VERSION ""

NS_ :

BS_:

BU_: XXX DSU HCU EPS IPAS XX X

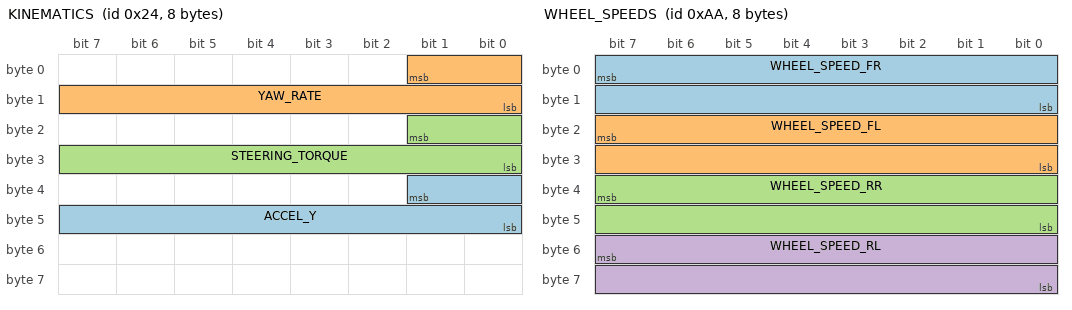
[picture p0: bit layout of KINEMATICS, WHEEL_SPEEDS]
BO_ 36 KINEMATICS: 8 XXX
 SG_ ACCEL_Y : 33|10@0+ (1,-512) [0|65535] "" XXX
 SG_ YAW_RATE : 1|10@0+ (1,-512) [0|65535] "" XXX
 SG_ STEERING_TORQUE : 17|10@0+ (1,-512) [0|65535] "" XXX

BO_ 166 BRAKE: 8 XXX
 SG_ BRAKE_AMOUNT : 7|8@0+ (1,0) [0|255] "" XXX
 SG_ BRAKE_PEDAL : 23|8@0+ (1,0) [0|255] "" XXX

BO_ 170 WHEEL_SPEEDS: 8 XXX
 SG_ WHEEL_SPEED_FR : 7|16@0+ (0.01,-67.67) [0|250] "kph" XXX
 SG_ WHEEL_SPEED_FL : 23|16@0+ (0.01,-67.67) [0|250] "kph" XXX
 SG_ WHEEL_SPEED_RR : 39|16@0+ (0.01,-67.67) [0|250] "kph" XXX
 SG_ WHEEL_SPEED_RL : 55|16@0+ (0.01,-67.67) [0|250] "kph" XXX

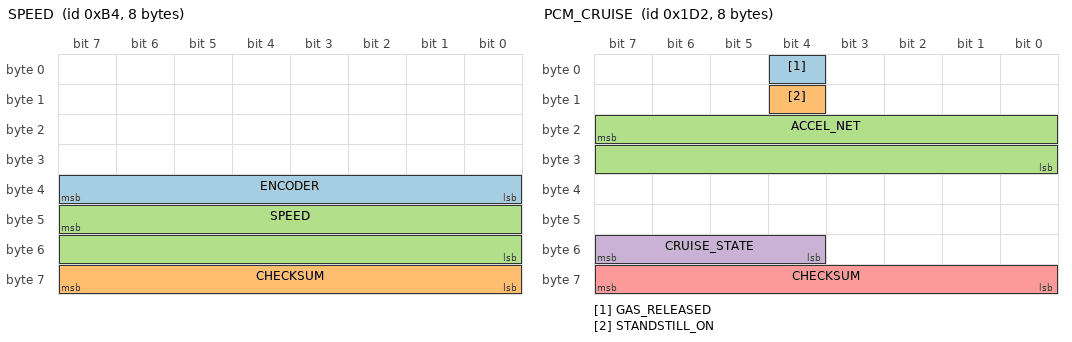
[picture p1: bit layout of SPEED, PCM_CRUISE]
BO_ 180 SPEED: 8 XXX
 SG_ ENCODER : 39|8@0+ (1,0) [0|255] "" XXX
 SG_ CHECKSUM : 63|8@0+ (1,0) [0|255] "" XXX
 SG_ SPEED : 47|16@0+ (0.01,0) [0|250] "kph" XXX

BO_ 466 PCM_CRUISE: 8 XXX
 SG_ GAS_RELEASED : 4|1@0+ (1,0) [0|1] "" XXX
 SG_ STANDSTILL_ON : 12|1@0+ (1,0) [0|1] "" XXX
 SG_ ACCEL_NET : 23|16@0- (0.001,0) [-20|20] "m/s2" XXX
 SG_ CRUISE_STATE : 55|4@0+ (1,0) [0|15] "" XXX
 SG_ CHECKSUM : 63|8@0+ (1,0) [0|255] "" XXX

BO_ 552 ACCELEROMETER: 8 XXX
 SG_ ACCEL_Z : 22|15@0- (1,0) [0|32767] "" XXX
 SG_ ACCEL_X : 6|15@0- (0.001,0) [-20|20] "m/s2" XXX

BO_ 560 BRAKE_MODULE2: 7 XXX
 SG_ BRAKE_PRESSED : 26|1@0+ (1,0) [0|1] "" XXX

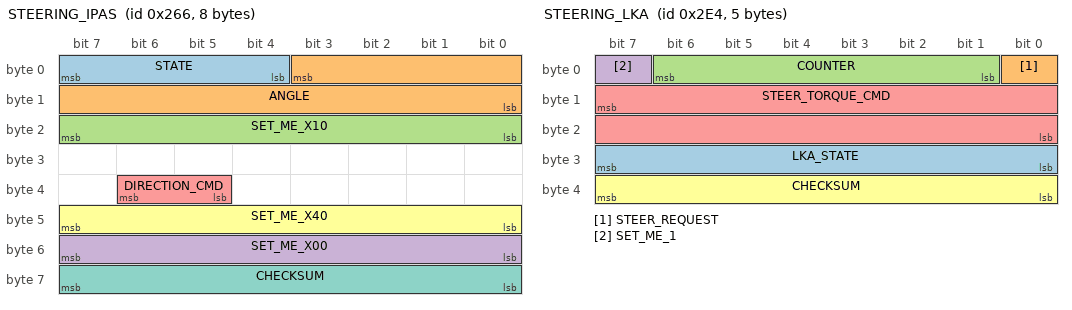
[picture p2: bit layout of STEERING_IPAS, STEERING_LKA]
BO_ 614 STEERING_IPAS: 8 IPAS
 SG_ STATE : 7|4@0+ (1,0) [0|15] "" XXX
 SG_ ANGLE : 3|12@0- (1.5,0) [-510|510] "deg" XXX
 SG_ SET_ME_X10 : 23|8@0+ (1,0) [0|255] "" XXX
 SG_ SET_ME_X00 : 55|8@0+ (1,0) [0|255] "" XXX
 SG_ DIRECTION_CMD : 38|2@0+ (1,0) [0|3] "" XXX
 SG_ SET_ME_X40 : 47|8@0+ (1,0) [0|255] "" XXX
 SG_ CHECKSUM : 63|8@0+ (1,0) [0|255] "" XXX

BO_ 643 PRE_COLLISION: 8 XXX

BO_ 740 STEERING_LKA: 5 XXX
 SG_ LKA_STATE : 31|8@0+ (1,0) [0|255] "" XXX
 SG_ STEER_REQUEST : 0|1@0+ (1,0) [0|1] "" XXX
 SG_ COUNTER : 6|6@0+ (1,0) [0|63] "" XXX
 SG_ SET_ME_1 : 7|1@0+ (1,0) [0|1] "" XXX
 SG_ STEER_TORQUE_CMD : 15|16@0- (1,0) [0|65535] "" XXX
 SG_ CHECKSUM : 39|8@0+ (1,0) [0|255] "" XXX

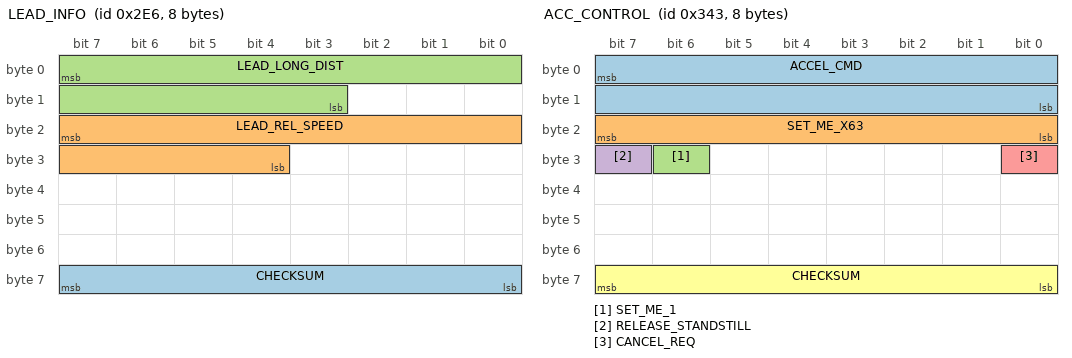
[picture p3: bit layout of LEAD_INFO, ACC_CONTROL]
BO_ 742 LEAD_INFO: 8 DSU
 SG_ CHECKSUM : 63|8@0+ (1,0) [0|255] "" HCU
 SG_ LEAD_REL_SPEED : 23|12@0- (0.025,0) [-100|100] "m/s" HCU
 SG_ LEAD_LONG_DIST : 7|13@0+ (0.05,0) [0|300] "m" HCU

BO_ 835 ACC_CONTROL: 8 DSU
 SG_ ACCEL_CMD : 7|16@0- (0.001,0) [-20|20] "m/s2" HCU
 SG_ SET_ME_X63 : 23|8@0+ (1,0) [0|255] "" HCU
 SG_ SET_ME_1 : 30|1@0+ (1,0) [0|1] "" HCU
 SG_ RELEASE_STANDSTILL : 31|1@0+ (1,0) [0|1] "" HCU
 SG_ CANCEL_REQ : 24|1@0+ (1,0) [0|1] "" HCU
 SG_ CHECKSUM : 63|8@0+ (1,0) [0|255] "" XXX

BO_ 1556 STEERING_LEVERS: 8 XXX
 SG_ TURN_SIGNALS : 29|2@0+ (1,0) [0|3] "" XXX

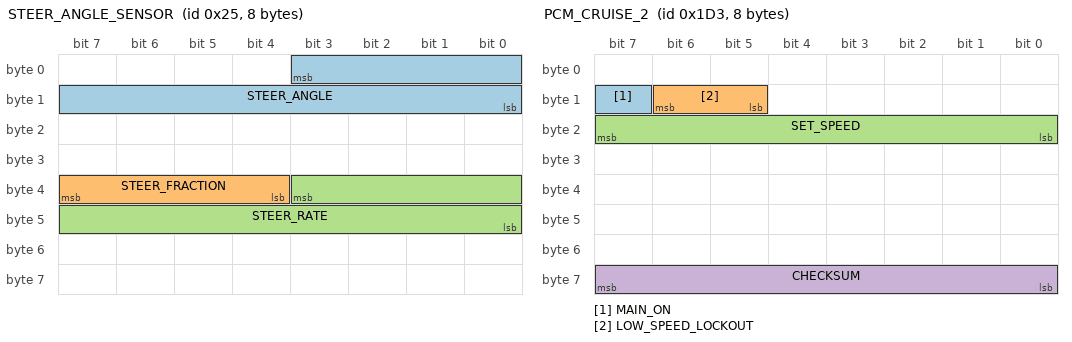
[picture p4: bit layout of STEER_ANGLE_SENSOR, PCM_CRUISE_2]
BO_ 37 STEER_ANGLE_SENSOR: 8 XXX
 SG_ STEER_ANGLE : 3|12@0- (1.5,0) [-500|500] "deg" XXX
 SG_ STEER_FRACTION : 39|4@0- (0.1,0) [-0.7|0.7] "deg" XXX
 SG_ STEER_RATE : 35|12@0- (1,0) [-2000|2000] "deg/s" XXX

BO_ 467 PCM_CRUISE_2: 8 XXX
 SG_ MAIN_ON : 15|1@0+ (1,0) [0|1] "" XXX
 SG_ LOW_SPEED_LOCKOUT : 14|2@0+ (1,0) [0|3] "kph" XXX
 SG_ SET_SPEED : 23|8@0+ (1,0) [0|255] "kph" XXX
 SG_ CHECKSUM : 63|8@0+ (1,0) [0|255] "" XXX

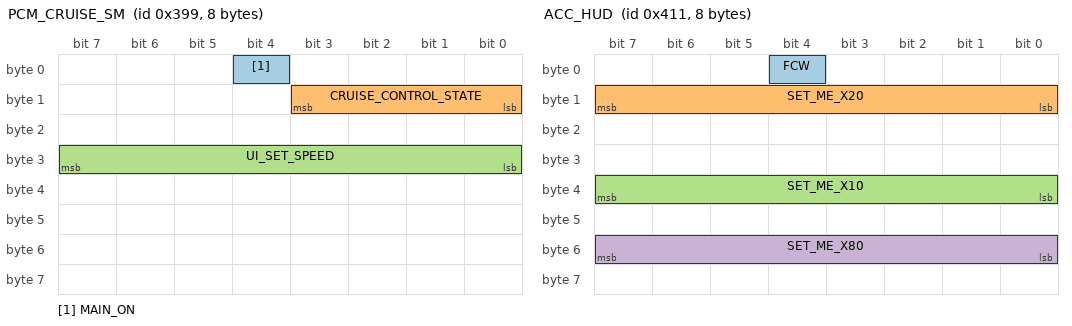
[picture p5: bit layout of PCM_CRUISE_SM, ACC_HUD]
BO_ 921 PCM_CRUISE_SM: 8 XXX
 SG_ MAIN_ON : 4|1@0+ (1,0) [0|1] "" XXX
 SG_ CRUISE_CONTROL_STATE : 11|4@0+ (1,0) [0|15] "" XXX
 SG_ UI_SET_SPEED : 31|8@0+ (1,0) [0|255] "" XXX

BO_ 951 ESP_CONTROL: 8 ESP
 SG_ TC_DISABLED : 13|1@0+ (1,0) [0|1] "" XXX
 SG_ BRAKE_LIGHTS_ACC : 18|1@0+ (1,0) [0|1] "" XXX

BO_ 1041 ACC_HUD: 8 DSU
 SG_ FCW : 4|1@0+ (1,0) [0|1] "" XXX
 SG_ SET_ME_X20 : 15|8@0+ (1,0) [0|1] "" XXX
 SG_ SET_ME_X10 : 39|8@0+ (1,0) [0|1] "" XXX
 SG_ SET_ME_X80 : 55|8@0+ (1,0) [0|1] "" XXX

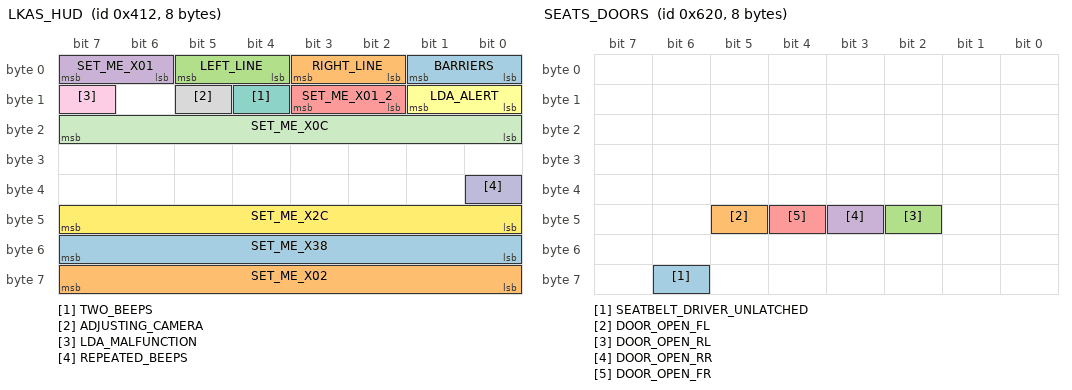
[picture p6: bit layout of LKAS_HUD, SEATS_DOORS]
BO_ 1042 LKAS_HUD: 8 XXX
 SG_ BARRIERS : 1|2@0+ (1,0) [0|3] "" XXX
 SG_ RIGHT_LINE : 3|2@0+ (1,0) [0|3] "" XXX
 SG_ LEFT_LINE : 5|2@0+ (1,0) [0|3] "" XXX
 SG_ SET_ME_X01 : 7|2@0+ (1,0) [0|3] "" XXX
 SG_ SET_ME_X01_2 : 11|2@0+ (1,0) [0|3] "" XXX
 SG_ LDA_ALERT : 9|2@0+ (1,0) [0|3] "" XXX
 SG_ TWO_BEEPS : 12|1@0+ (1,0) [0|1] "" XXX
 SG_ ADJUSTING_CAMERA : 13|1@0+ (1,0) [0|1] "" XXX
 SG_ LDA_MALFUNCTION : 15|1@0+ (1,0) [0|1] "" XXX
 SG_ REPEATED_BEEPS : 32|1@0+ (1,0) [0|1] "" XXX
 SG_ SET_ME_X0C : 23|8@0+ (1,0) [0|1] "" XXX
 SG_ SET_ME_X2C : 47|8@0+ (1,0) [0|1] "" XXX
 SG_ SET_ME_X38 : 55|8@0+ (1,0) [0|1] "" XXX
 SG_ SET_ME_X02 : 63|8@0+ (1,0) [0|1] "" XXX

BO_ 1553 UI_SEETING: 8 XXX
 SG_ UNITS : 26|2@0+ (1,0) [0|3] "" XXX

BO_ 1568 SEATS_DOORS: 8 XXX
 SG_ SEATBELT_DRIVER_UNLATCHED : 62|1@0+ (1,0) [0|1] "" XXX
 SG_ DOOR_OPEN_FL : 45|1@0+ (1,0) [0|1] "" XXX
 SG_ DOOR_OPEN_RL : 42|1@0+ (1,0) [0|1] "" XXX
 SG_ DOOR_OPEN_RR : 43|1@0+ (1,0) [0|1] "" XXX
 SG_ DOOR_OPEN_FR : 44|1@0+ (1,0) [0|1] "" XXX

BO_ 1570 LIGHT_STALK: 8 SCM
 SG_ AUTO_HIGH_BEAM : 37|1@0+ (1,0) [0|1] "" XXX

BO_ 550 BRAKE_MODULE: 8 XXX

BO_ 581 GAS_PEDAL: 5 XXX
 SG_ GAS_PEDAL : 23|8@0+ (0.005,0) [0|1] "" XXX

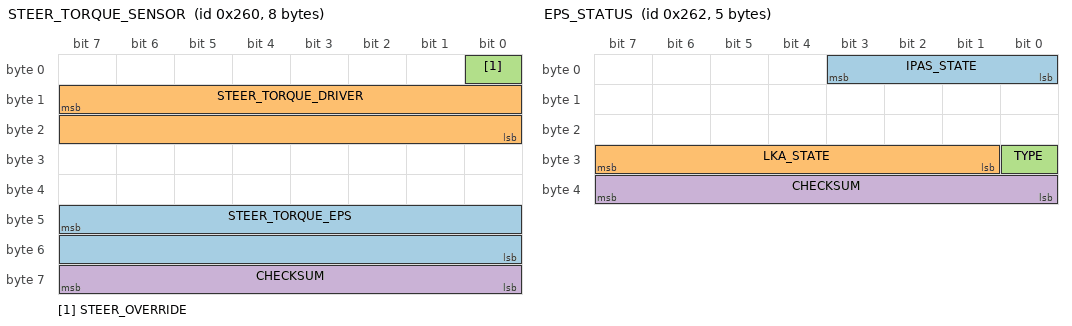
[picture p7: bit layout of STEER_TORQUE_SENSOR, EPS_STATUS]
BO_ 608 STEER_TORQUE_SENSOR: 8 XXX
 SG_ STEER_TORQUE_EPS : 47|16@0- (0.73,0) [-20000|20000] "" XXX
 SG_ STEER_TORQUE_DRIVER : 15|16@0- (1,0) [-32768|32767] "" XXX
 SG_ STEER_OVERRIDE : 0|1@0+ (1,0) [0|1] "" XXX
 SG_ CHECKSUM : 63|8@0+ (1,0) [0|255] "" XXX

BO_ 610 EPS_STATUS: 5 EPS
 SG_ IPAS_STATE : 3|4@0+ (1,0) [0|15] "" XXX
 SG_ LKA_STATE : 31|7@0+ (1,0) [0|127] "" XXX
 SG_ TYPE : 24|1@0+ (1,0) [0|1] "" XXX
 SG_ CHECKSUM : 39|8@0+ (1,0) [0|255] "" XXX

BO_ 956 GEAR_PACKET: 8 XXX
 SG_ GEAR : 13|6@0+ (1,0) [0|63] "" XXX

BO_ 1880 DEBUG: 8 XXX
 SG_ 61 : 16|8@1+ (1,0) [0|255] "" XXX
 SG_ 69 : 24|8@1+ (1,0) [0|255] "" XXX
 SG_ BLINDSPOTSIDE : 7|8@0+ (1,0) [0|255] "" XXX
 SG_ Blindspot : 38|1@0+ (1,0) [0|3] "" XXX
 SG_ NEW_SIGNAL_2 : 63|1@1+ (1,0) [0|15] "" XXX
 SG_ NEW_SIGNAL_1 : 59|1@1+ (1,0) [0|15] "" XXX
 SG_ NEW_SIGNAL_3 : 58|1@1+ (1,0) [0|7] "" XXX
 SG_ NEW_SIGNAL_4 : 57|1@1+ (1,0) [0|3] "" XXX
 SG_ NEW_SIGNAL_5 : 56|1@0+ (1,0) [0|3] "" XXX
 SG_ 06 : 8|8@1+ (1,0) [0|255] "" XXX
 SG_ NEW_SIGNAL_7 : 37|1@0+ (1,0) [0|1] "" XXX
 SG_ NEW_SIGNAL_6 : 36|1@1+ (1,0) [0|63] "" XXX
 SG_ NEW_SIGNAL_8 : 39|1@0+ (1,0) [0|1] "" XXX
 SG_ NEW_SIGNAL_10 : 47|8@0+ (1,0) [0|255] "" XXX
 SG_ NEW_SIGNAL_9 : 32|4@1+ (1,0) [0|15] "" XXX
 SG_ NEW_SIGNAL_12 : 62|3@0+ (1,0) [0|7] "" XXX
 SG_ NEW_SIGNAL_11 : 55|8@0+ (1,0) [0|255] "" XXX

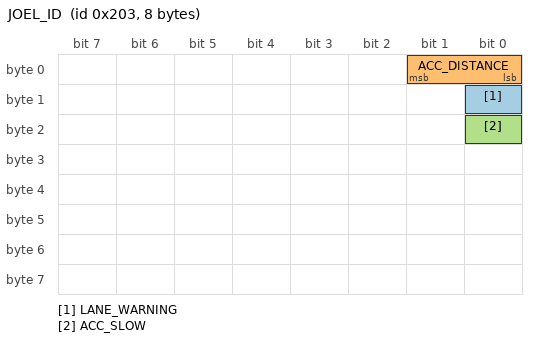
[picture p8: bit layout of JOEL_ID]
BO_ 515 JOEL_ID: 8 XXX
 SG_ LANE_WARNING : 8|1@0+ (1,0) [0|1] "" XXX
 SG_ ACC_DISTANCE : 1|2@0+ (1,0) [1|3] "" XXX
 SG_ ACC_SLOW : 16|1@0+ (1,0) [0|1] "" XXX

CM_ SG_ 36 ACCEL_Y "unit is tbd";
CM_ SG_ 36 YAW_RATE "verify";
CM_ SG_ 36 STEERING_TORQUE "does not seem the steer torque, tbd";
CM_ SG_ 466 ACCEL_NET "net acceleration produced by the system, given ACCEL_CMD, road grade and other factors";
CM_ SG_ 560 BRAKE_PRESSED "another brake pressed?";
CM_ SG_ 614 ANGLE "set to measured angle when ipas control isn't active";
CM_ SG_ 37 STEER_FRACTION "1/15th of the signal STEER_ANGLE, which is 1.5 deg; note that 0x8 is never set";
CM_ SG_ 37 STEER_RATE "factor is tbd";
CM_ SG_ 467 LOW_SPEED_LOCKOUT "in low speed lockout, system would always disengage below 28mph";
CM_ SG_ 467 SET_SPEED "43 kph are shown as 28mph, so conversion isnt perfect";
CM_ SG_ 921 UI_SET_SPEED "set speed shown in UI with user set unit";
CM_ SG_ 951 BRAKE_LIGHTS_ACC "brake lights when ACC commands decel";
CM_ SG_ 1042 REPEATED_BEEPS "recommended for fcw and other important alerts";
CM_ SG_ 581 GAS_PEDAL "it seems slightly filtered";
CM_ SG_ 610 TYPE "seems 1 on Corolla, 0 on all others";
CM_ SG_ 1880 BLINDSPOTSIDE "65 for Left and 66 for Right";
VAL_ 466 CRUISE_STATE 8 "active" 7 "standstill" 1 "off" ;
VAL_ 614 STATE 3 "enabled" 1 "disabled" ;
VAL_ 614 DIRECTION_CMD 3 "right" 2 "center" 1 "left" ;
VAL_ 1556 TURN_SIGNALS 3 "none" 2 "right" 1 "left" ;
VAL_ 467 LOW_SPEED_LOCKOUT 2 "low speed locked" 1 "ok" ;
VAL_ 921 CRUISE_CONTROL_STATE 2 "disabled" 11 "hold" 10 "hold_waiting_user_cmd" 6 "enabled" 5 "faulted" ;
VAL_ 1042 BARRIERS 3 "both" 2 "right" 1 "left" 0 "none" ;
VAL_ 1042 RIGHT_LINE 3 "orange" 2 "double" 1 "solid" 0 "none" ;
VAL_ 1042 LEFT_LINE 3 "orange" 2 "double" 1 "solid" 0 "none" ;
VAL_ 1042 LDA_ALERT 3 "hold with continuous beep" 2 "LDA unavailable" 1 "hold" 0 "none" ;
VAL_ 1553 UNITS 1 "km" 2 "miles" ;
VAL_ 610 IPAS_STATE 5 "override" 3 "enabled" 1 "disabled" ;
VAL_ 610 LKA_STATE 25 "temporary_fault" 9 "temporary_fault2" 5 "active" 1 "standby" ;
VAL_ 956 GEAR 0 "D" 1 "S" 8 "N" 16 "R" 32 "P" ;
CM_ "toyota_rav4_hybrid_2017_pt.dbc start
CM_ "toyota_rav4_hybrid_2017_pt.dbc st";
CM_ "toyota_rav4_hybrid_2017_pt.dbc sta
CM_ "toyota_rav4_hybrid_2017_pt.dbc sta";
CM_ "toyota_rav4_hybrid_2017_pt.dbc star
CM_ "toyota_rav4_hybrid_2017_pt.dbc sta";
CM_ "toyota_rav4_hybrid_2017_pt.dbc star
CM_ "toyota_rav4_hybrid_2017_pt.dbc star";
CM_ "toyota_rav4_hybrid_2017_pt.dbc start
CM_ "toyota_rav4_hybrid_2017_pt.dbc sta";
CM_ "toyota_rav4_hybrid_2017_pt.dbc star
CM_ "toyota_rav4_hybrid_2017_pt.dbc star";
CM_ "toyota_rav4_hybrid_2017_pt.dbc start
CM_ "toyota_rav4_hybrid_2017_pt.dbc star";
CM_ "toyota_rav4_hybrid_2017_pt.dbc start
CM_ "toyota_rav4_hybrid_2017_pt.dbc start";
CM_ "toyota_rav4_hybrid_2017_pt.dbc starts
CM_ "toyota_rav4_hybrid_2017_pt.dbc s";
CM_ "toyota_rav4_hybrid_2017_pt.dbc st
CM_ "toyota_rav4_hybrid_2017_pt.dbc st";
CM_ "toyota_rav4_hybrid_2017_pt.dbc sta
CM_ "toyota_rav4_hybrid_2017_pt.dbc st";
CM_ "toyota_rav4_hybrid_2017_pt.dbc sta
CM_ "toyota_rav4_hybrid_2017_pt.dbc sta";
CM_ "toyota_rav4_hybrid_2017_pt.dbc star
CM_ "toyota_rav4_hybrid_2017_pt.dbc st";
CM_ "toyota_rav4_hybrid_2017_pt.dbc sta
CM_ "toyota_rav4_hybrid_2017_pt.dbc sta";
CM_ "toyota_rav4_hybrid_2017_pt.dbc star
CM_ "toyota_rav4_hybrid_2017_pt.dbc sta";
CM_ "toyota_rav4_hybrid_2017_pt.dbc star
CM_ "toyota_rav4_hybrid_2017_pt.dbc star";
CM_ "toyota_rav4_hybrid_2017_pt.dbc start
CM_ "toyota_rav4_hybrid_2017_pt.dbc st";
CM_ "toyota_rav4_hybrid_2017_pt.dbc sta
CM_ "toyota_rav4_hybrid_2017_pt.dbc sta";
CM_ "toyota_rav4_hybrid_2017_pt.dbc star
CM_ "toyota_rav4_hybrid_2017_pt.dbc sta";
CM_ "toyota_rav4_hybrid_2017_pt.dbc star
CM_ "toyota_rav4_hybrid_2017_pt.dbc star";
CM_ "toyota_rav4_hybrid_2017_pt.dbc start
CM_ "toyota_rav4_hybrid_2017_pt.dbc sta";
CM_ "toyota_rav4_hybrid_2017_pt.dbc star
CM_ "toyota_rav4_hybrid_2017_pt.dbc star";
CM_ "toyota_rav4_hybrid_2017_pt.dbc start
CM_ "toyota_rav4_hybrid_2017_pt.dbc star";
CM_ "toyota_rav4_hybrid_2017_pt.dbc start
CM_ "toyota_rav4_hybrid_2017_pt.dbc start";
CM_ "toyota_rav4_hybrid_2017_pt.dbc starts
CM_ "toyota_rav4_hybrid_2017_pt.dbc s";
CM_ "toyota_rav4_hybrid_2017_pt.dbc st
CM_ "toyota_rav4_hybrid_2017_pt.dbc st";
CM_ "toyota_rav4_hybrid_2017_pt.dbc sta
CM_ "toyota_rav4_hybrid_2017_pt.dbc st";
CM_ "toyota_rav4_hybrid_2017_pt.dbc sta
CM_ "toyota_rav4_hybrid_2017_pt.dbc sta";
CM_ "toyota_rav4_hybrid_2017_pt.dbc star
CM_ "toyota_rav4_hybrid_2017_pt.dbc st";
CM_ "toyota_rav4_hybrid_2017_pt.dbc sta
CM_ "toyota_rav4_hybrid_2017_pt.dbc sta";
CM_ "toyota_rav4_hybrid_2017_pt.dbc star
CM_ "toyota_rav4_hybrid_2017_pt.dbc sta";
CM_ "toyota_rav4_hybrid_2017_pt.dbc star
CM_ "toyota_rav4_hybrid_2017_pt.dbc star";
CM_ "toyota_rav4_hybrid_2017_pt.dbc start
CM_ "toyota_rav4_hybrid_2017_pt.dbc st";
CM_ "toyota_rav4_hybrid_2017_pt.dbc sta
CM_ "toyota_rav4_hybrid_2017_pt.dbc sta";
CM_ "toyota_rav4_hybrid_2017_pt.dbc star
CM_ "toyota_rav4_hybrid_2017_pt.dbc sta";
CM_ "toyota_rav4_hybrid_2017_pt.dbc star
CM_ "toyota_rav4_hybrid_2017_pt.dbc star";
CM_ "toyota_rav4_hybrid_2017_pt.dbc start
CM_ "toyota_rav4_hybrid_2017_pt.dbc sta";
CM_ "toyota_rav4_hybrid_2017_pt.dbc star
CM_ "toyota_rav4_hybrid_2017_pt.dbc star";
CM_ "toyota_rav4_hybrid_2017_pt.dbc start
CM_ "toyota_rav4_hybrid_2017_pt.dbc star";
CM_ "toyota_rav4_hybrid_2017_pt.dbc start
CM_ "toyota_rav4_hybrid_2017_pt.dbc start";
CM_ "toyota_rav4_hybrid_2017_pt.dbc starts
CM_ "toyota_rav4_hybrid_2017_pt.dbc st";
CM_ "toyota_rav4_hybrid_2017_pt.dbc sta
CM_ "toyota_rav4_hybrid_2017_pt.dbc sta";
CM_ "toyota_rav4_hybrid_2017_pt.dbc star
CM_ "toyota_rav4_hybrid_2017_pt.dbc sta";
CM_ "toyota_rav4_hybrid_2017_pt.dbc star
CM_ "toyota_rav4_hybrid_2017_pt.dbc star";
CM_ "toyota_rav4_hybrid_2017_pt.dbc start
CM_ "toyota_rav4_hybrid_2017_pt.dbc sta";
CM_ "toyota_rav4_hybrid_2017_pt.dbc star
CM_ "toyota_rav4_hybrid_2017_pt.dbc star";
CM_ "toyota_rav4_hybrid_2017_pt.dbc start
CM_ "toyota_rav4_hybrid_2017_pt.dbc star";
CM_ "toyota_rav4_hybrid_2017_pt.dbc start
CM_ "toyota_rav4_hybrid_2017_pt.dbc start";
CM_ "toyota_rav4_hybrid_2017_pt.dbc starts
CM_ "toyota_rav4_hybrid_2017_pt.dbc st";
CM_ "toyota_rav4_hybrid_2017_pt.dbc sta
CM_ "toyota_rav4_hybrid_2017_pt.dbc sta";
CM_ "toyota_rav4_hybrid_2017_pt.dbc star
CM_ "toyota_rav4_hybrid_2017_pt.dbc sta";
CM_ "toyota_rav4_hybrid_2017_pt.dbc star
CM_ "toyota_rav4_hybrid_2017_pt.dbc star";
CM_ "toyota_rav4_hybrid_2017_pt.dbc start
CM_ "toyota_rav4_hybrid_2017_pt.dbc sta";
CM_ "toyota_rav4_hybrid_2017_pt.dbc star
CM_ "toyota_rav4_hybrid_2017_pt.dbc star";
CM_ "toyota_rav4_hybrid_2017_pt.dbc start
CM_ "toyota_rav4_hybrid_2017_pt.dbc star";
CM_ "toyota_rav4_hybrid_2017_pt.dbc start
CM_ "toyota_rav4_hybrid_2017_pt.dbc start";
CM_ "toyota_rav4_hybrid_2017_pt.dbc starts
CM_ "toyota_rav4_hybrid_2017_pt.dbc sta";
CM_ "toyota_rav4_hybrid_2017_pt.dbc star
CM_ "toyota_rav4_hybrid_2017_pt.dbc star";
CM_ "toyota_rav4_hybrid_2017_pt.dbc start
CM_ "toyota_rav4_hybrid_2017_pt.dbc star";
CM_ "toyota_rav4_hybrid_2017_pt.dbc start
CM_ "toyota_rav4_hybrid_2017_pt.dbc start";
CM_ "toyota_rav4_hybrid_2017_pt.dbc starts
CM_ "toyota_rav4_hybrid_2017_pt.dbc sta";
CM_ "toyota_rav4_hybrid_2017_pt.dbc star
CM_ "toyota_rav4_hybrid_2017_pt.dbc star";
CM_ "toyota_rav4_hybrid_2017_pt.dbc start
CM_ "toyota_rav4_hybrid_2017_pt.dbc star";
CM_ "toyota_rav4_hybrid_2017_pt.dbc start
CM_ "toyota_rav4_hybrid_2017_pt.dbc start";
CM_ "toyota_rav4_hybrid_2017_pt.dbc starts
CM_ "toyota_rav4_hybrid_2017_pt.dbc star";
CM_ "toyota_rav4_hybrid_2017_pt.dbc start
CM_ "toyota_rav4_hybrid_2017_pt.dbc start";
CM_ "toyota_rav4_hybrid_2017_pt.dbc starts
CM_ "toyota_rav4_hybrid_2017_pt.dbc star";
CM_ "toyota_rav4_hybrid_2017_pt.dbc start
CM_ "toyota_rav4_hybrid_2017_pt.dbc start";
CM_ "toyota_rav4_hybrid_2017_pt.dbc starts
CM_ "toyota_rav4_hybrid_2017_pt.dbc start";
CM_ "toyota_rav4_hybrid_2017_pt.dbc starts
CM_ "toyota_rav4_hybrid_2017_pt.dbc start";
CM_ "toyota_rav4_hybrid_2017_pt.dbc starts
CM_ "toyota_rav4_hybrid_2017_pt.dbc starts";
CM_ "toyota_rav4_hybrid_2017_pt.dbc starts
CM_ "toyota_rav4_hybrid_2017_pt.dbc starts ";
CM_ "toyota_rav4_hybrid_2017_pt.dbc starts h
CM_ "toyota_rav4_hybrid_2017_pt.dbc s";
CM_ "toyota_rav4_hybrid_2017_pt.dbc st
CM_ "toyota_rav4_hybrid_2017_pt.dbc st";
CM_ "toyota_rav4_hybrid_2017_pt.dbc sta
CM_ "toyota_rav4_hybrid_2017_pt.dbc st";
CM_ "toyota_rav4_hybrid_2017_pt.dbc sta
CM_ "toyota_rav4_hybrid_2017_pt.dbc sta";
CM_ "toyota_rav4_hybrid_2017_pt.dbc star
CM_ "toyota_rav4_hybrid_2017_pt.dbc st";
CM_ "toyota_rav4_hybrid_2017_pt.dbc sta
CM_ "toyota_rav4_hybrid_2017_pt.dbc sta";
CM_ "toyota_rav4_hybrid_2017_pt.dbc star
CM_ "toyota_rav4_hybrid_2017_pt.dbc sta";
CM_ "toyota_rav4_hybrid_2017_pt.dbc star
CM_ "toyota_rav4_hybrid_2017_pt.dbc star";
CM_ "toyota_rav4_hybrid_2017_pt.dbc start
CM_ "toyota_rav4_hybrid_2017_pt.dbc st";
CM_ "toyota_rav4_hybrid_2017_pt.dbc sta
CM_ "toyota_rav4_hybrid_2017_pt.dbc sta";
CM_ "toyota_rav4_hybrid_2017_pt.dbc star
CM_ "toyota_rav4_hybrid_2017_pt.dbc sta";
CM_ "toyota_rav4_hybrid_2017_pt.dbc star
CM_ "toyota_rav4_hybrid_2017_pt.dbc star";
CM_ "toyota_rav4_hybrid_2017_pt.dbc start
CM_ "toyota_rav4_hybrid_2017_pt.dbc sta";
CM_ "toyota_rav4_hybrid_2017_pt.dbc star
CM_ "toyota_rav4_hybrid_2017_pt.dbc star";
CM_ "toyota_rav4_hybrid_2017_pt.dbc start
CM_ "toyota_rav4_hybrid_2017_pt.dbc star";
CM_ "toyota_rav4_hybrid_2017_pt.dbc start
CM_ "toyota_rav4_hybrid_2017_pt.dbc start";
CM_ "toyota_rav4_hybrid_2017_pt.dbc starts
CM_ "toyota_rav4_hybrid_2017_pt.dbc s";
CM_ "toyota_rav4_hybrid_2017_pt.dbc st
CM_ "toyota_rav4_hybrid_2017_pt.dbc st";
CM_ "toyota_rav4_hybrid_2017_pt.dbc sta
CM_ "toyota_rav4_hybrid_2017_pt.dbc st";
CM_ "toyota_rav4_hybrid_2017_pt.dbc sta
CM_ "toyota_rav4_hybrid_2017_pt.dbc sta";
CM_ "toyota_rav4_hybrid_2017_pt.dbc star
CM_ "toyota_rav4_hybrid_2017_pt.dbc st";
CM_ "toyota_rav4_hybrid_2017_pt.dbc sta
CM_ "toyota_rav4_hybrid_2017_pt.dbc sta";
CM_ "toyota_rav4_hybrid_2017_pt.dbc star
CM_ "toyota_rav4_hybrid_2017_pt.dbc sta";
CM_ "toyota_rav4_hybrid_2017_pt.dbc star
CM_ "toyota_rav4_hybrid_2017_pt.dbc star";
CM_ "toyota_rav4_hybrid_2017_pt.dbc start
CM_ "toyota_rav4_hybrid_2017_pt.dbc st";
CM_ "toyota_rav4_hybrid_2017_pt.dbc sta
CM_ "toyota_rav4_hybrid_2017_pt.dbc sta";
CM_ "toyota_rav4_hybrid_2017_pt.dbc star
CM_ "toyota_rav4_hybrid_2017_pt.dbc sta";
CM_ "toyota_rav4_hybrid_2017_pt.dbc star
CM_ "toyota_rav4_hybrid_2017_pt.dbc star";
CM_ "toyota_rav4_hybrid_2017_pt.dbc start
CM_ "toyota_rav4_hybrid_2017_pt.dbc sta";
CM_ "toyota_rav4_hybrid_2017_pt.dbc star
CM_ "toyota_rav4_hybrid_2017_pt.dbc star";
CM_ "toyota_rav4_hybrid_2017_pt.dbc start
CM_ "toyota_rav4_hybrid_2017_pt.dbc star";
CM_ "toyota_rav4_hybrid_2017_pt.dbc start
CM_ "toyota_rav4_hybrid_2017_pt.dbc start";
CM_ "toyota_rav4_hybrid_2017_pt.dbc starts
CM_ "toyota_rav4_hybrid_2017_pt.dbc st";
CM_ "toyota_rav4_hybrid_2017_pt.dbc sta
CM_ "toyota_rav4_hybrid_2017_pt.dbc sta";
CM_ "toyota_rav4_hybrid_2017_pt.dbc star
CM_ "toyota_rav4_hybrid_2017_pt.dbc sta";
CM_ "toyota_rav4_hybrid_2017_pt.dbc star
CM_ "toyota_rav4_hybrid_2017_pt.dbc star";
CM_ "toyota_rav4_hybrid_2017_pt.dbc start
CM_ "toyota_rav4_hybrid_2017_pt.dbc sta";
CM_ "toyota_rav4_hybrid_2017_pt.dbc star
CM_ "toyota_rav4_hybrid_2017_pt.dbc star";
CM_ "toyota_rav4_hybrid_2017_pt.dbc start
CM_ "toyota_rav4_hybrid_2017_pt.dbc star";
CM_ "toyota_rav4_hybrid_2017_pt.dbc start
CM_ "toyota_rav4_hybrid_2017_pt.dbc start";
CM_ "toyota_rav4_hybrid_2017_pt.dbc starts
CM_ "toyota_rav4_hybrid_2017_pt.dbc st";
CM_ "toyota_rav4_hybrid_2017_pt.dbc sta
CM_ "toyota_rav4_hybrid_2017_pt.dbc sta";
CM_ "toyota_rav4_hybrid_2017_pt.dbc star
CM_ "toyota_rav4_hybrid_2017_pt.dbc sta";
CM_ "toyota_rav4_hybrid_2017_pt.dbc star
CM_ "toyota_rav4_hybrid_2017_pt.dbc star";
CM_ "toyota_rav4_hybrid_2017_pt.dbc start
CM_ "toyota_rav4_hybrid_2017_pt.dbc sta";
CM_ "toyota_rav4_hybrid_2017_pt.dbc star
CM_ "toyota_rav4_hybrid_2017_pt.dbc star";
CM_ "toyota_rav4_hybrid_2017_pt.dbc start
CM_ "toyota_rav4_hybrid_2017_pt.dbc star";
CM_ "toyota_rav4_hybrid_2017_pt.dbc start
CM_ "toyota_rav4_hybrid_2017_pt.dbc start";
CM_ "toyota_rav4_hybrid_2017_pt.dbc starts
CM_ "toyota_rav4_hybrid_2017_pt.dbc sta";
CM_ "toyota_rav4_hybrid_2017_pt.dbc star
CM_ "toyota_rav4_hybrid_2017_pt.dbc star";
CM_ "toyota_rav4_hybrid_2017_pt.dbc start
CM_ "toyota_rav4_hybrid_2017_pt.dbc star";
CM_ "toyota_rav4_hybrid_2017_pt.dbc start
CM_ "toyota_rav4_hybrid_2017_pt.dbc start";
CM_ "toyota_rav4_hybrid_2017_pt.dbc starts
CM_ "toyota_rav4_hybrid_2017_pt.dbc sta";
CM_ "toyota_rav4_hybrid_2017_pt.dbc star
CM_ "toyota_rav4_hybrid_2017_pt.dbc star";
CM_ "toyota_rav4_hybrid_2017_pt.dbc start
CM_ "toyota_rav4_hybrid_2017_pt.dbc star";
CM_ "toyota_rav4_hybrid_2017_pt.dbc start
CM_ "toyota_rav4_hybrid_2017_pt.dbc start";
CM_ "toyota_rav4_hybrid_2017_pt.dbc starts
CM_ "toyota_rav4_hybrid_2017_pt.dbc star";
CM_ "toyota_rav4_hybrid_2017_pt.dbc start
CM_ "toyota_rav4_hybrid_2017_pt.dbc start";
CM_ "toyota_rav4_hybrid_2017_pt.dbc starts
CM_ "toyota_rav4_hybrid_2017_pt.dbc star";
CM_ "toyota_rav4_hybrid_2017_pt.dbc start
CM_ "toyota_rav4_hybrid_2017_pt.dbc start";
CM_ "toyota_rav4_hybrid_2017_pt.dbc starts
CM_ "toyota_rav4_hybrid_2017_pt.dbc start";
CM_ "toyota_rav4_hybrid_2017_pt.dbc starts
CM_ "toyota_rav4_hybrid_2017_pt.dbc start";
CM_ "toyota_rav4_hybrid_2017_pt.dbc starts
CM_ "toyota_rav4_hybrid_2017_pt.dbc starts";
CM_ "toyota_rav4_hybrid_2017_pt.dbc starts
CM_ "toyota_rav4_hybrid_2017_pt.dbc starts ";
CM_ "toyota_rav4_hybrid_2017_pt.dbc starts h
CM_ "toyota_rav4_hybrid_2017_pt.dbc st";
CM_ "toyota_rav4_hybrid_2017_pt.dbc sta
CM_ "toyota_rav4_hybrid_2017_pt.dbc sta";
CM_ "toyota_rav4_hybrid_2017_pt.dbc star
CM_ "toyota_rav4_hybrid_2017_pt.dbc sta";
CM_ "toyota_rav4_hybrid_2017_pt.dbc star
CM_ "toyota_rav4_hybrid_2017_pt.dbc star";
CM_ "toyota_rav4_hybrid_2017_pt.dbc start
CM_ "toyota_rav4_hybrid_2017_pt.dbc sta";
CM_ "toyota_rav4_hybrid_2017_pt.dbc star
CM_ "toyota_rav4_hybrid_2017_pt.dbc star";
CM_ "toyota_rav4_hybrid_2017_pt.dbc start
CM_ "toyota_rav4_hybrid_2017_pt.dbc star";
CM_ "toyota_rav4_hybrid_2017_pt.dbc start
CM_ "toyota_rav4_hybrid_2017_pt.dbc start";
CM_ "toyota_rav4_hybrid_2017_pt.dbc starts
CM_ "toyota_rav4_hybrid_2017_pt.dbc st";
CM_ "toyota_rav4_hybrid_2017_pt.dbc sta
CM_ "toyota_rav4_hybrid_2017_pt.dbc sta";
CM_ "toyota_rav4_hybrid_2017_pt.dbc star
CM_ "toyota_rav4_hybrid_2017_pt.dbc sta";
CM_ "toyota_rav4_hybrid_2017_pt.dbc star
CM_ "toyota_rav4_hybrid_2017_pt.dbc star";
CM_ "toyota_rav4_hybrid_2017_pt.dbc start
CM_ "toyota_rav4_hybrid_2017_pt.dbc sta";
CM_ "toyota_rav4_hybrid_2017_pt.dbc star
CM_ "toyota_rav4_hybrid_2017_pt.dbc star";
CM_ "toyota_rav4_hybrid_2017_pt.dbc start
CM_ "toyota_rav4_hybrid_2017_pt.dbc star";
CM_ "toyota_rav4_hybrid_2017_pt.dbc start
CM_ "toyota_rav4_hybrid_2017_pt.dbc start";
CM_ "toyota_rav4_hybrid_2017_pt.dbc starts
CM_ "toyota_rav4_hybrid_2017_pt.dbc sta";
CM_ "toyota_rav4_hybrid_2017_pt.dbc star
CM_ "toyota_rav4_hybrid_2017_pt.dbc star";
CM_ "toyota_rav4_hybrid_2017_pt.dbc start
CM_ "toyota_rav4_hybrid_2017_pt.dbc star";
CM_ "toyota_rav4_hybrid_2017_pt.dbc start
CM_ "toyota_rav4_hybrid_2017_pt.dbc start";
CM_ "toyota_rav4_hybrid_2017_pt.dbc starts
CM_ "toyota_rav4_hybrid_2017_pt.dbc sta";
CM_ "toyota_rav4_hybrid_2017_pt.dbc star
CM_ "toyota_rav4_hybrid_2017_pt.dbc star";
CM_ "toyota_rav4_hybrid_2017_pt.dbc start
CM_ "toyota_rav4_hybrid_2017_pt.dbc star";
CM_ "toyota_rav4_hybrid_2017_pt.dbc start
CM_ "toyota_rav4_hybrid_2017_pt.dbc start";
CM_ "toyota_rav4_hybrid_2017_pt.dbc starts
CM_ "toyota_rav4_hybrid_2017_pt.dbc star";
CM_ "toyota_rav4_hybrid_2017_pt.dbc start
CM_ "toyota_rav4_hybrid_2017_pt.dbc start";
CM_ "toyota_rav4_hybrid_2017_pt.dbc starts
CM_ "toyota_rav4_hybrid_2017_pt.dbc star";
CM_ "toyota_rav4_hybrid_2017_pt.dbc start
CM_ "toyota_rav4_hybrid_2017_pt.dbc start";
CM_ "toyota_rav4_hybrid_2017_pt.dbc starts
CM_ "toyota_rav4_hybrid_2017_pt.dbc start";
CM_ "toyota_rav4_hybrid_2017_pt.dbc starts
CM_ "toyota_rav4_hybrid_2017_pt.dbc start";
CM_ "toyota_rav4_hybrid_2017_pt.dbc starts
CM_ "toyota_rav4_hybrid_2017_pt.dbc starts";
CM_ "toyota_rav4_hybrid_2017_pt.dbc starts
CM_ "toyota_rav4_hybrid_2017_pt.dbc starts ";
CM_ "toyota_rav4_hybrid_2017_pt.dbc starts h
CM_ "toyota_rav4_hybrid_2017_pt.dbc sta";
CM_ "toyota_rav4_hybrid_2017_pt.dbc star
CM_ "toyota_rav4_hybrid_2017_pt.dbc star";
CM_ "toyota_rav4_hybrid_2017_pt.dbc start
CM_ "toyota_rav4_hybrid_2017_pt.dbc star";
CM_ "toyota_rav4_hybrid_2017_pt.dbc start
CM_ "toyota_rav4_hybrid_2017_pt.dbc start";
CM_ "toyota_rav4_hybrid_2017_pt.dbc starts
CM_ "toyota_rav4_hybrid_2017_pt.dbc sta";
CM_ "toyota_rav4_hybrid_2017_pt.dbc star
CM_ "toyota_rav4_hybrid_2017_pt.dbc star";
CM_ "toyota_rav4_hybrid_2017_pt.dbc start
CM_ "toyota_rav4_hybrid_2017_pt.dbc star";
CM_ "toyota_rav4_hybrid_2017_pt.dbc start
CM_ "toyota_rav4_hybrid_2017_pt.dbc start";
CM_ "toyota_rav4_hybrid_2017_pt.dbc starts
CM_ "toyota_rav4_hybrid_2017_pt.dbc star";
CM_ "toyota_rav4_hybrid_2017_pt.dbc start
CM_ "toyota_rav4_hybrid_2017_pt.dbc start";
CM_ "toyota_rav4_hybrid_2017_pt.dbc starts
CM_ "toyota_rav4_hybrid_2017_pt.dbc star";
CM_ "toyota_rav4_hybrid_2017_pt.dbc start
CM_ "toyota_rav4_hybrid_2017_pt.dbc start";
CM_ "toyota_rav4_hybrid_2017_pt.dbc starts
CM_ "toyota_rav4_hybrid_2017_pt.dbc start";
CM_ "toyota_rav4_hybrid_2017_pt.dbc starts
CM_ "toyota_rav4_hybrid_2017_pt.dbc start";
CM_ "toyota_rav4_hybrid_2017_pt.dbc starts
CM_ "toyota_rav4_hybrid_2017_pt.dbc starts";
CM_ "toyota_rav4_hybrid_2017_pt.dbc starts
CM_ "toyota_rav4_hybrid_2017_pt.dbc starts ";
CM_ "toyota_rav4_hybrid_2017_pt.dbc starts h
CM_ "toyota_rav4_hybrid_2017_pt.dbc star";
CM_ "toyota_rav4_hybrid_2017_pt.dbc start
CM_ "toyota_rav4_hybrid_2017_pt.dbc start";
CM_ "toyota_rav4_hybrid_2017_pt.dbc starts
CM_ "toyota_rav4_hybrid_2017_pt.dbc star";
CM_ "toyota_rav4_hybrid_2017_pt.dbc start
CM_ "toyota_rav4_hybrid_2017_pt.dbc start";
CM_ "toyota_rav4_hybrid_2017_pt.dbc starts
CM_ "toyota_rav4_hybrid_2017_pt.dbc start";
CM_ "toyota_rav4_hybrid_2017_pt.dbc starts
CM_ "toyota_rav4_hybrid_2017_pt.dbc start";
CM_ "toyota_rav4_hybrid_2017_pt.dbc starts
CM_ "toyota_rav4_hybrid_2017_pt.dbc starts";
CM_ "toyota_rav4_hybrid_2017_pt.dbc starts
CM_ "toyota_rav4_hybrid_2017_pt.dbc starts ";
CM_ "toyota_rav4_hybrid_2017_pt.dbc starts h
CM_ "toyota_rav4_hybrid_2017_pt.dbc start";
CM_ "toyota_rav4_hybrid_2017_pt.dbc starts
CM_ "toyota_rav4_hybrid_2017_pt.dbc start";
CM_ "toyota_rav4_hybrid_2017_pt.dbc starts
CM_ "toyota_rav4_hybrid_2017_pt.dbc starts";
CM_ "toyota_rav4_hybrid_2017_pt.dbc starts
CM_ "toyota_rav4_hybrid_2017_pt.dbc starts ";
CM_ "toyota_rav4_hybrid_2017_pt.dbc starts h
CM_ "toyota_rav4_hybrid_2017_pt.dbc starts";
CM_ "toyota_rav4_hybrid_2017_pt.dbc starts
CM_ "toyota_rav4_hybrid_2017_pt.dbc starts ";
CM_ "toyota_rav4_hybrid_2017_pt.dbc starts h
CM_ "toyota_rav4_hybrid_2017_pt.dbc starts ";
CM_ "toyota_rav4_hybrid_2017_pt.dbc starts h
CM_ "toyota_rav4_hybrid_2017_pt.dbc starts h";
CM_ "toyota_rav4_hybrid_2017_pt.dbc starts he
CM_ "toyota_rav4_hybrid_2017_pt.dbc s";
CM_ "toyota_rav4_hybrid_2017_pt.dbc st
CM_ "toyota_rav4_hybrid_2017_pt.dbc st";
CM_ "toyota_rav4_hybrid_2017_pt.dbc sta
CM_ "toyota_rav4_hybrid_2017_pt.dbc st";
CM_ "toyota_rav4_hybrid_2017_pt.dbc sta
CM_ "toyota_rav4_hybrid_2017_pt.dbc sta";
CM_ "toyota_rav4_hybrid_2017_pt.dbc star
CM_ "toyota_rav4_hybrid_2017_pt.dbc st";
CM_ "toyota_rav4_hybrid_2017_pt.dbc sta
CM_ "toyota_rav4_hybrid_2017_pt.dbc sta";
CM_ "toyota_rav4_hybrid_2017_pt.dbc star
CM_ "toyota_rav4_hybrid_2017_pt.dbc sta";
CM_ "toyota_rav4_hybrid_2017_pt.dbc star
CM_ "toyota_rav4_hybrid_2017_pt.dbc star";
CM_ "toyota_rav4_hybrid_2017_pt.dbc start
CM_ "toyota_rav4_hybrid_2017_pt.dbc st";
CM_ "toyota_rav4_hybrid_2017_pt.dbc sta
CM_ "toyota_rav4_hybrid_2017_pt.dbc sta";
CM_ "toyota_rav4_hybrid_2017_pt.dbc star
CM_ "toyota_rav4_hybrid_2017_pt.dbc sta";
CM_ "toyota_rav4_hybrid_2017_pt.dbc star
CM_ "toyota_rav4_hybrid_2017_pt.dbc star";
CM_ "toyota_rav4_hybrid_2017_pt.dbc start
CM_ "toyota_rav4_hybrid_2017_pt.dbc sta";
CM_ "toyota_rav4_hybrid_2017_pt.dbc star
CM_ "toyota_rav4_hybrid_2017_pt.dbc star";
CM_ "toyota_rav4_hybrid_2017_pt.dbc start
CM_ "toyota_rav4_hybrid_2017_pt.dbc star";
CM_ "toyota_rav4_hybrid_2017_pt.dbc start
CM_ "toyota_rav4_hybrid_2017_pt.dbc start";
CM_ "toyota_rav4_hybrid_2017_pt.dbc starts
CM_ "toyota_rav4_hybrid_2017_pt.dbc s";
CM_ "toyota_rav4_hybrid_2017_pt.dbc st
CM_ "toyota_rav4_hybrid_2017_pt.dbc st";
CM_ "toyota_rav4_hybrid_2017_pt.dbc sta
CM_ "toyota_rav4_hybrid_2017_pt.dbc st";
CM_ "toyota_rav4_hybrid_2017_pt.dbc sta
CM_ "toyota_rav4_hybrid_2017_pt.dbc sta";
CM_ "toyota_rav4_hybrid_2017_pt.dbc star
CM_ "toyota_rav4_hybrid_2017_pt.dbc st";
CM_ "toyota_rav4_hybrid_2017_pt.dbc sta
CM_ "toyota_rav4_hybrid_2017_pt.dbc sta";
CM_ "toyota_rav4_hybrid_2017_pt.dbc star
CM_ "toyota_rav4_hybrid_2017_pt.dbc sta";
CM_ "toyota_rav4_hybrid_2017_pt.dbc star
CM_ "toyota_rav4_hybrid_2017_pt.dbc star";
CM_ "toyota_rav4_hybrid_2017_pt.dbc start
CM_ "toyota_rav4_hybrid_2017_pt.dbc st";
CM_ "toyota_rav4_hybrid_2017_pt.dbc sta
CM_ "toyota_rav4_hybrid_2017_pt.dbc sta";
CM_ "toyota_rav4_hybrid_2017_pt.dbc star
CM_ "toyota_rav4_hybrid_2017_pt.dbc sta";
CM_ "toyota_rav4_hybrid_2017_pt.dbc star
CM_ "toyota_rav4_hybrid_2017_pt.dbc star";
CM_ "toyota_rav4_hybrid_2017_pt.dbc start
CM_ "toyota_rav4_hybrid_2017_pt.dbc sta";
CM_ "toyota_rav4_hybrid_2017_pt.dbc star
CM_ "toyota_rav4_hybrid_2017_pt.dbc star";
CM_ "toyota_rav4_hybrid_2017_pt.dbc start
CM_ "toyota_rav4_hybrid_2017_pt.dbc star";
CM_ "toyota_rav4_hybrid_2017_pt.dbc start
CM_ "toyota_rav4_hybrid_2017_pt.dbc start";
CM_ "toyota_rav4_hybrid_2017_pt.dbc starts
CM_ "toyota_rav4_hybrid_2017_pt.dbc st";
CM_ "toyota_rav4_hybrid_2017_pt.dbc sta
CM_ "toyota_rav4_hybrid_2017_pt.dbc sta";
CM_ "toyota_rav4_hybrid_2017_pt.dbc star
CM_ "toyota_rav4_hybrid_2017_pt.dbc sta";
CM_ "toyota_rav4_hybrid_2017_pt.dbc star
CM_ "toyota_rav4_hybrid_2017_pt.dbc star";
CM_ "toyota_rav4_hybrid_2017_pt.dbc start
CM_ "toyota_rav4_hybrid_2017_pt.dbc sta";
CM_ "toyota_rav4_hybrid_2017_pt.dbc star
CM_ "toyota_rav4_hybrid_2017_pt.dbc star";
CM_ "toyota_rav4_hybrid_2017_pt.dbc start
CM_ "toyota_rav4_hybrid_2017_pt.dbc star";
CM_ "toyota_rav4_hybrid_2017_pt.dbc start
CM_ "toyota_rav4_hybrid_2017_pt.dbc start";
CM_ "toyota_rav4_hybrid_2017_pt.dbc starts
CM_ "toyota_rav4_hybrid_2017_pt.dbc st";
CM_ "toyota_rav4_hybrid_2017_pt.dbc sta
CM_ "toyota_rav4_hybrid_2017_pt.dbc sta";
CM_ "toyota_rav4_hybrid_2017_pt.dbc star
CM_ "toyota_rav4_hybrid_2017_pt.dbc sta";
CM_ "toyota_rav4_hybrid_2017_pt.dbc star
CM_ "toyota_rav4_hybrid_2017_pt.dbc star";
CM_ "toyota_rav4_hybrid_2017_pt.dbc start
CM_ "toyota_rav4_hybrid_2017_pt.dbc sta";
CM_ "toyota_rav4_hybrid_2017_pt.dbc star
CM_ "toyota_rav4_hybrid_2017_pt.dbc star";
CM_ "toyota_rav4_hybrid_2017_pt.dbc start
CM_ "toyota_rav4_hybrid_2017_pt.dbc star";
CM_ "toyota_rav4_hybrid_2017_pt.dbc start
CM_ "toyota_rav4_hybrid_2017_pt.dbc start";
CM_ "toyota_rav4_hybrid_2017_pt.dbc starts
CM_ "toyota_rav4_hybrid_2017_pt.dbc sta";
CM_ "toyota_rav4_hybrid_2017_pt.dbc star
CM_ "toyota_rav4_hybrid_2017_pt.dbc star";
CM_ "toyota_rav4_hybrid_2017_pt.dbc start
CM_ "toyota_rav4_hybrid_2017_pt.dbc star";
CM_ "toyota_rav4_hybrid_2017_pt.dbc start
CM_ "toyota_rav4_hybrid_2017_pt.dbc start";
CM_ "toyota_rav4_hybrid_2017_pt.dbc starts
CM_ "toyota_rav4_hybrid_2017_pt.dbc sta";
CM_ "toyota_rav4_hybrid_2017_pt.dbc star
CM_ "toyota_rav4_hybrid_2017_pt.dbc star";
CM_ "toyota_rav4_hybrid_2017_pt.dbc start
CM_ "toyota_rav4_hybrid_2017_pt.dbc star";
CM_ "toyota_rav4_hybrid_2017_pt.dbc start
CM_ "toyota_rav4_hybrid_2017_pt.dbc start";
CM_ "toyota_rav4_hybrid_2017_pt.dbc starts
CM_ "toyota_rav4_hybrid_2017_pt.dbc star";
CM_ "toyota_rav4_hybrid_2017_pt.dbc start
CM_ "toyota_rav4_hybrid_2017_pt.dbc start";
CM_ "toyota_rav4_hybrid_2017_pt.dbc starts
CM_ "toyota_rav4_hybrid_2017_pt.dbc star";
CM_ "toyota_rav4_hybrid_2017_pt.dbc start
CM_ "toyota_rav4_hybrid_2017_pt.dbc start";
CM_ "toyota_rav4_hybrid_2017_pt.dbc starts
CM_ "toyota_rav4_hybrid_2017_pt.dbc start";
CM_ "toyota_rav4_hybrid_2017_pt.dbc starts
CM_ "toyota_rav4_hybrid_2017_pt.dbc start";
CM_ "toyota_rav4_hybrid_2017_pt.dbc starts
CM_ "toyota_rav4_hybrid_2017_pt.dbc starts";
CM_ "toyota_rav4_hybrid_2017_pt.dbc starts
CM_ "toyota_rav4_hybrid_2017_pt.dbc starts ";
CM_ "toyota_rav4_hybrid_2017_pt.dbc starts h
CM_ "toyota_rav4_hybrid_2017_pt.dbc st";
CM_ "toyota_rav4_hybrid_2017_pt.dbc sta
CM_ "toyota_rav4_hybrid_2017_pt.dbc sta";
CM_ "toyota_rav4_hybrid_2017_pt.dbc star
CM_ "toyota_rav4_hybrid_2017_pt.dbc sta";
CM_ "toyota_rav4_hybrid_2017_pt.dbc star
CM_ "toyota_rav4_hybrid_2017_pt.dbc star";
CM_ "toyota_rav4_hybrid_2017_pt.dbc start
CM_ "toyota_rav4_hybrid_2017_pt.dbc sta";
CM_ "toyota_rav4_hybrid_2017_pt.dbc star
CM_ "toyota_rav4_hybrid_2017_pt.dbc star";
CM_ "toyota_rav4_hybrid_2017_pt.dbc start
CM_ "toyota_rav4_hybrid_2017_pt.dbc star";
CM_ "toyota_rav4_hybrid_2017_pt.dbc start
CM_ "toyota_rav4_hybrid_2017_pt.dbc start";
CM_ "toyota_rav4_hybrid_2017_pt.dbc starts
CM_ "toyota_rav4_hybrid_2017_pt.dbc st";
CM_ "toyota_rav4_hybrid_2017_pt.dbc sta
CM_ "toyota_rav4_hybrid_2017_pt.dbc sta";
CM_ "toyota_rav4_hybrid_2017_pt.dbc star
CM_ "toyota_rav4_hybrid_2017_pt.dbc sta";
CM_ "toyota_rav4_hybrid_2017_pt.dbc star
CM_ "toyota_rav4_hybrid_2017_pt.dbc star";
CM_ "toyota_rav4_hybrid_2017_pt.dbc start
CM_ "toyota_rav4_hybrid_2017_pt.dbc sta";
CM_ "toyota_rav4_hybrid_2017_pt.dbc star
CM_ "toyota_rav4_hybrid_2017_pt.dbc star";
CM_ "toyota_rav4_hybrid_2017_pt.dbc start
CM_ "toyota_rav4_hybrid_2017_pt.dbc star";
CM_ "toyota_rav4_hybrid_2017_pt.dbc start
CM_ "toyota_rav4_hybrid_2017_pt.dbc start";
CM_ "toyota_rav4_hybrid_2017_pt.dbc starts
CM_ "toyota_rav4_hybrid_2017_pt.dbc sta";
CM_ "toyota_rav4_hybrid_2017_pt.dbc star
CM_ "toyota_rav4_hybrid_2017_pt.dbc star";
CM_ "toyota_rav4_hybrid_2017_pt.dbc start
CM_ "toyota_rav4_hybrid_2017_pt.dbc star";
CM_ "toyota_rav4_hybrid_2017_pt.dbc start
CM_ "toyota_rav4_hybrid_2017_pt.dbc start";
CM_ "toyota_rav4_hybrid_2017_pt.dbc starts
CM_ "toyota_rav4_hybrid_2017_pt.dbc sta";
CM_ "toyota_rav4_hybrid_2017_pt.dbc star
CM_ "toyota_rav4_hybrid_2017_pt.dbc star";
CM_ "toyota_rav4_hybrid_2017_pt.dbc start
CM_ "toyota_rav4_hybrid_2017_pt.dbc star";
CM_ "toyota_rav4_hybrid_2017_pt.dbc start
CM_ "toyota_rav4_hybrid_2017_pt.dbc start";
CM_ "toyota_rav4_hybrid_2017_pt.dbc starts
CM_ "toyota_rav4_hybrid_2017_pt.dbc star";
CM_ "toyota_rav4_hybrid_2017_pt.dbc start
CM_ "toyota_rav4_hybrid_2017_pt.dbc start";
CM_ "toyota_rav4_hybrid_2017_pt.dbc starts
CM_ "toyota_rav4_hybrid_2017_pt.dbc star";
CM_ "toyota_rav4_hybrid_2017_pt.dbc start
CM_ "toyota_rav4_hybrid_2017_pt.dbc start";
CM_ "toyota_rav4_hybrid_2017_pt.dbc starts
CM_ "toyota_rav4_hybrid_2017_pt.dbc start";
CM_ "toyota_rav4_hybrid_2017_pt.dbc starts
CM_ "toyota_rav4_hybrid_2017_pt.dbc start";
CM_ "toyota_rav4_hybrid_2017_pt.dbc starts
CM_ "toyota_rav4_hybrid_2017_pt.dbc starts";
CM_ "toyota_rav4_hybrid_2017_pt.dbc starts
CM_ "toyota_rav4_hybrid_2017_pt.dbc starts ";
CM_ "toyota_rav4_hybrid_2017_pt.dbc starts h
CM_ "toyota_rav4_hybrid_2017_pt.dbc sta";
CM_ "toyota_rav4_hybrid_2017_pt.dbc star
CM_ "toyota_rav4_hybrid_2017_pt.dbc star";
CM_ "toyota_rav4_hybrid_2017_pt.dbc start
CM_ "toyota_rav4_hybrid_2017_pt.dbc star";
CM_ "toyota_rav4_hybrid_2017_pt.dbc start
CM_ "toyota_rav4_hybrid_2017_pt.dbc start";
CM_ "toyota_rav4_hybrid_2017_pt.dbc starts
CM_ "toyota_rav4_hybrid_2017_pt.dbc sta";
CM_ "toyota_rav4_hybrid_2017_pt.dbc star
CM_ "toyota_rav4_hybrid_2017_pt.dbc star";
CM_ "toyota_rav4_hybrid_2017_pt.dbc start
CM_ "toyota_rav4_hybrid_2017_pt.dbc star";
CM_ "toyota_rav4_hybrid_2017_pt.dbc start
CM_ "toyota_rav4_hybrid_2017_pt.dbc start";
CM_ "toyota_rav4_hybrid_2017_pt.dbc starts
CM_ "toyota_rav4_hybrid_2017_pt.dbc star";
CM_ "toyota_rav4_hybrid_2017_pt.dbc start
CM_ "toyota_rav4_hybrid_2017_pt.dbc start";
CM_ "toyota_rav4_hybrid_2017_pt.dbc starts
CM_ "toyota_rav4_hybrid_2017_pt.dbc star";
CM_ "toyota_rav4_hybrid_2017_pt.dbc start
CM_ "toyota_rav4_hybrid_2017_pt.dbc start";
CM_ "toyota_rav4_hybrid_2017_pt.dbc starts
CM_ "toyota_rav4_hybrid_2017_pt.dbc start";
CM_ "toyota_rav4_hybrid_2017_pt.dbc starts
CM_ "toyota_rav4_hybrid_2017_pt.dbc start";
CM_ "toyota_rav4_hybrid_2017_pt.dbc starts
CM_ "toyota_rav4_hybrid_2017_pt.dbc starts";
CM_ "toyota_rav4_hybrid_2017_pt.dbc starts
CM_ "toyota_rav4_hybrid_2017_pt.dbc starts ";
CM_ "toyota_rav4_hybrid_2017_pt.dbc starts h
CM_ "toyota_rav4_hybrid_2017_pt.dbc star";
CM_ "toyota_rav4_hybrid_2017_pt.dbc start
CM_ "toyota_rav4_hybrid_2017_pt.dbc start";
CM_ "toyota_rav4_hybrid_2017_pt.dbc starts
CM_ "toyota_rav4_hybrid_2017_pt.dbc star";
CM_ "toyota_rav4_hybrid_2017_pt.dbc start
CM_ "toyota_rav4_hybrid_2017_pt.dbc start";
CM_ "toyota_rav4_hybrid_2017_pt.dbc starts
CM_ "toyota_rav4_hybrid_2017_pt.dbc start";
CM_ "toyota_rav4_hybrid_2017_pt.dbc starts
CM_ "toyota_rav4_hybrid_2017_pt.dbc start";
CM_ "toyota_rav4_hybrid_2017_pt.dbc starts
CM_ "toyota_rav4_hybrid_2017_pt.dbc starts";
CM_ "toyota_rav4_hybrid_2017_pt.dbc starts
CM_ "toyota_rav4_hybrid_2017_pt.dbc starts ";
CM_ "toyota_rav4_hybrid_2017_pt.dbc starts h
CM_ "toyota_rav4_hybrid_2017_pt.dbc start";
CM_ "toyota_rav4_hybrid_2017_pt.dbc starts
CM_ "toyota_rav4_hybrid_2017_pt.dbc start";
CM_ "toyota_rav4_hybrid_2017_pt.dbc starts
CM_ "toyota_rav4_hybrid_2017_pt.dbc starts";
CM_ "toyota_rav4_hybrid_2017_pt.dbc starts
CM_ "toyota_rav4_hybrid_2017_pt.dbc starts ";
CM_ "toyota_rav4_hybrid_2017_pt.dbc starts h
CM_ "toyota_rav4_hybrid_2017_pt.dbc starts";
CM_ "toyota_rav4_hybrid_2017_pt.dbc starts
CM_ "toyota_rav4_hybrid_2017_pt.dbc starts ";
CM_ "toyota_rav4_hybrid_2017_pt.dbc starts h
CM_ "toyota_rav4_hybrid_2017_pt.dbc starts ";
CM_ "toyota_rav4_hybrid_2017_pt.dbc starts h
CM_ "toyota_rav4_hybrid_2017_pt.dbc starts h";
CM_ "toyota_rav4_hybrid_2017_pt.dbc starts he
CM_ "toyota_rav4_hybrid_2017_pt.dbc st";
CM_ "toyota_rav4_hybrid_2017_pt.dbc sta
CM_ "toyota_rav4_hybrid_2017_pt.dbc sta";
CM_ "toyota_rav4_hybrid_2017_pt.dbc star
CM_ "toyota_rav4_hybrid_2017_pt.dbc sta";
CM_ "toyota_rav4_hybrid_2017_pt.dbc star
CM_ "toyota_rav4_hybrid_2017_pt.dbc star";
CM_ "toyota_rav4_hybrid_2017_pt.dbc start
CM_ "toyota_rav4_hybrid_2017_pt.dbc sta";
CM_ "toyota_rav4_hybrid_2017_pt.dbc star
CM_ "toyota_rav4_hybrid_2017_pt.dbc star";
CM_ "toyota_rav4_hybrid_2017_pt.dbc start
CM_ "toyota_rav4_hybrid_2017_pt.dbc star";
CM_ "toyota_rav4_hybrid_2017_pt.dbc start
CM_ "toyota_rav4_hybrid_2017_pt.dbc start";
CM_ "toyota_rav4_hybrid_2017_pt.dbc starts
CM_ "toyota_rav4_hybrid_2017_pt.dbc st";
CM_ "toyota_rav4_hybrid_2017_pt.dbc sta
CM_ "toyota_rav4_hybrid_2017_pt.dbc sta";
CM_ "toyota_rav4_hybrid_2017_pt.dbc star
CM_ "toyota_rav4_hybrid_2017_pt.dbc sta";
CM_ "toyota_rav4_hybrid_2017_pt.dbc star
CM_ "toyota_rav4_hybrid_2017_pt.dbc star";
CM_ "toyota_rav4_hybrid_2017_pt.dbc start
CM_ "toyota_rav4_hybrid_2017_pt.dbc sta";
CM_ "toyota_rav4_hybrid_2017_pt.dbc star
CM_ "toyota_rav4_hybrid_2017_pt.dbc star";
CM_ "toyota_rav4_hybrid_2017_pt.dbc start
CM_ "toyota_rav4_hybrid_2017_pt.dbc star";
CM_ "toyota_rav4_hybrid_2017_pt.dbc start
CM_ "toyota_rav4_hybrid_2017_pt.dbc start";
CM_ "toyota_rav4_hybrid_2017_pt.dbc starts
CM_ "toyota_rav4_hybrid_2017_pt.dbc sta";
CM_ "toyota_rav4_hybrid_2017_pt.dbc star
CM_ "toyota_rav4_hybrid_2017_pt.dbc star";
CM_ "toyota_rav4_hybrid_2017_pt.dbc start
CM_ "toyota_rav4_hybrid_2017_pt.dbc star";
CM_ "toyota_rav4_hybrid_2017_pt.dbc start
CM_ "toyota_rav4_hybrid_2017_pt.dbc start";
CM_ "toyota_rav4_hybrid_2017_pt.dbc starts
CM_ "toyota_rav4_hybrid_2017_pt.dbc sta";
CM_ "toyota_rav4_hybrid_2017_pt.dbc star
CM_ "toyota_rav4_hybrid_2017_pt.dbc star";
CM_ "toyota_rav4_hybrid_2017_pt.dbc start
CM_ "toyota_rav4_hybrid_2017_pt.dbc star";
CM_ "toyota_rav4_hybrid_2017_pt.dbc start
CM_ "toyota_rav4_hybrid_2017_pt.dbc start";
CM_ "toyota_rav4_hybrid_2017_pt.dbc starts
CM_ "toyota_rav4_hybrid_2017_pt.dbc star";
CM_ "toyota_rav4_hybrid_2017_pt.dbc start
CM_ "toyota_rav4_hybrid_2017_pt.dbc start";
CM_ "toyota_rav4_hybrid_2017_pt.dbc starts
CM_ "toyota_rav4_hybrid_2017_pt.dbc star";
CM_ "toyota_rav4_hybrid_2017_pt.dbc start
CM_ "toyota_rav4_hybrid_2017_pt.dbc start";
CM_ "toyota_rav4_hybrid_2017_pt.dbc starts
CM_ "toyota_rav4_hybrid_2017_pt.dbc start";
CM_ "toyota_rav4_hybrid_2017_pt.dbc starts
CM_ "toyota_rav4_hybrid_2017_pt.dbc start";
CM_ "toyota_rav4_hybrid_2017_pt.dbc starts
CM_ "toyota_rav4_hybrid_2017_pt.dbc starts";
CM_ "toyota_rav4_hybrid_2017_pt.dbc starts
CM_ "toyota_rav4_hybrid_2017_pt.dbc starts ";
CM_ "toyota_rav4_hybrid_2017_pt.dbc starts h
CM_ "toyota_rav4_hybrid_2017_pt.dbc sta";
CM_ "toyota_rav4_hybrid_2017_pt.dbc star
CM_ "toyota_rav4_hybrid_2017_pt.dbc star";
CM_ "toyota_rav4_hybrid_2017_pt.dbc start
CM_ "toyota_rav4_hybrid_2017_pt.dbc star";
CM_ "toyota_rav4_hybrid_2017_pt.dbc start
CM_ "toyota_rav4_hybrid_2017_pt.dbc start";
CM_ "toyota_rav4_hybrid_2017_pt.dbc starts
CM_ "toyota_rav4_hybrid_2017_pt.dbc sta";
CM_ "toyota_rav4_hybrid_2017_pt.dbc star
CM_ "toyota_rav4_hybrid_2017_pt.dbc star";
CM_ "toyota_rav4_hybrid_2017_pt.dbc start
CM_ "toyota_rav4_hybrid_2017_pt.dbc star";
CM_ "toyota_rav4_hybrid_2017_pt.dbc start
CM_ "toyota_rav4_hybrid_2017_pt.dbc start";
CM_ "toyota_rav4_hybrid_2017_pt.dbc starts
CM_ "toyota_rav4_hybrid_2017_pt.dbc star";
CM_ "toyota_rav4_hybrid_2017_pt.dbc start
CM_ "toyota_rav4_hybrid_2017_pt.dbc start";
CM_ "toyota_rav4_hybrid_2017_pt.dbc starts
CM_ "toyota_rav4_hybrid_2017_pt.dbc star";
CM_ "toyota_rav4_hybrid_2017_pt.dbc start
CM_ "toyota_rav4_hybrid_2017_pt.dbc start";
CM_ "toyota_rav4_hybrid_2017_pt.dbc starts
CM_ "toyota_rav4_hybrid_2017_pt.dbc start";
CM_ "toyota_rav4_hybrid_2017_pt.dbc starts
CM_ "toyota_rav4_hybrid_2017_pt.dbc start";
CM_ "toyota_rav4_hybrid_2017_pt.dbc starts
CM_ "toyota_rav4_hybrid_2017_pt.dbc starts";
CM_ "toyota_rav4_hybrid_2017_pt.dbc starts
CM_ "toyota_rav4_hybrid_2017_pt.dbc starts ";
CM_ "toyota_rav4_hybrid_2017_pt.dbc starts h
CM_ "toyota_rav4_hybrid_2017_pt.dbc star";
CM_ "toyota_rav4_hybrid_2017_pt.dbc start
CM_ "toyota_rav4_hybrid_2017_pt.dbc start";
CM_ "toyota_rav4_hybrid_2017_pt.dbc starts
CM_ "toyota_rav4_hybrid_2017_pt.dbc star";
CM_ "toyota_rav4_hybrid_2017_pt.dbc start
CM_ "toyota_rav4_hybrid_2017_pt.dbc start";
CM_ "toyota_rav4_hybrid_2017_pt.dbc starts
CM_ "toyota_rav4_hybrid_2017_pt.dbc start";
CM_ "toyota_rav4_hybrid_2017_pt.dbc starts
CM_ "toyota_rav4_hybrid_2017_pt.dbc start";
CM_ "toyota_rav4_hybrid_2017_pt.dbc starts
CM_ "toyota_rav4_hybrid_2017_pt.dbc starts";
CM_ "toyota_rav4_hybrid_2017_pt.dbc starts
CM_ "toyota_rav4_hybrid_2017_pt.dbc starts ";
CM_ "toyota_rav4_hybrid_2017_pt.dbc starts h
CM_ "toyota_rav4_hybrid_2017_pt.dbc start";
CM_ "toyota_rav4_hybrid_2017_pt.dbc starts
CM_ "toyota_rav4_hybrid_2017_pt.dbc start";
CM_ "toyota_rav4_hybrid_2017_pt.dbc starts
CM_ "toyota_rav4_hybrid_2017_pt.dbc starts";
CM_ "toyota_rav4_hybrid_2017_pt.dbc starts
CM_ "toyota_rav4_hybrid_2017_pt.dbc starts ";
CM_ "toyota_rav4_hybrid_2017_pt.dbc starts h
CM_ "toyota_rav4_hybrid_2017_pt.dbc starts";
CM_ "toyota_rav4_hybrid_2017_pt.dbc starts
CM_ "toyota_rav4_hybrid_2017_pt.dbc starts ";
CM_ "toyota_rav4_hybrid_2017_pt.dbc starts h
CM_ "toyota_rav4_hybrid_2017_pt.dbc starts ";
CM_ "toyota_rav4_hybrid_2017_pt.dbc starts h
CM_ "toyota_rav4_hybrid_2017_pt.dbc starts h";
CM_ "toyota_rav4_hybrid_2017_pt.dbc starts he
CM_ "toyota_rav4_hybrid_2017_pt.dbc sta";
CM_ "toyota_rav4_hybrid_2017_pt.dbc star
CM_ "toyota_rav4_hybrid_2017_pt.dbc star";
CM_ "toyota_rav4_hybrid_2017_pt.dbc start
CM_ "toyota_rav4_hybrid_2017_pt.dbc star";
CM_ "toyota_rav4_hybrid_2017_pt.dbc start
CM_ "toyota_rav4_hybrid_2017_pt.dbc start";
CM_ "toyota_rav4_hybrid_2017_pt.dbc starts
CM_ "toyota_rav4_hybrid_2017_pt.dbc sta";
CM_ "toyota_rav4_hybrid_2017_pt.dbc star
CM_ "toyota_rav4_hybrid_2017_pt.dbc star";
CM_ "toyota_rav4_hybrid_2017_pt.dbc start
CM_ "toyota_rav4_hybrid_2017_pt.dbc star";
CM_ "toyota_rav4_hybrid_2017_pt.dbc start
CM_ "toyota_rav4_hybrid_2017_pt.dbc start";
CM_ "toyota_rav4_hybrid_2017_pt.dbc starts
CM_ "toyota_rav4_hybrid_2017_pt.dbc star";
CM_ "toyota_rav4_hybrid_2017_pt.dbc start
CM_ "toyota_rav4_hybrid_2017_pt.dbc start";
CM_ "toyota_rav4_hybrid_2017_pt.dbc starts
CM_ "toyota_rav4_hybrid_2017_pt.dbc star";
CM_ "toyota_rav4_hybrid_2017_pt.dbc start
CM_ "toyota_rav4_hybrid_2017_pt.dbc start";
CM_ "toyota_rav4_hybrid_2017_pt.dbc starts
CM_ "toyota_rav4_hybrid_2017_pt.dbc start";
CM_ "toyota_rav4_hybrid_2017_pt.dbc starts
CM_ "toyota_rav4_hybrid_2017_pt.dbc start";
CM_ "toyota_rav4_hybrid_2017_pt.dbc starts
CM_ "toyota_rav4_hybrid_2017_pt.dbc starts";
CM_ "toyota_rav4_hybrid_2017_pt.dbc starts
CM_ "toyota_rav4_hybrid_2017_pt.dbc starts ";
CM_ "toyota_rav4_hybrid_2017_pt.dbc starts h
CM_ "toyota_rav4_hybrid_2017_pt.dbc star";
CM_ "toyota_rav4_hybrid_2017_pt.dbc start
CM_ "toyota_rav4_hybrid_2017_pt.dbc start";
CM_ "toyota_rav4_hybrid_2017_pt.dbc starts
CM_ "toyota_rav4_hybrid_2017_pt.dbc star";
CM_ "toyota_rav4_hybrid_2017_pt.dbc start
CM_ "toyota_rav4_hybrid_2017_pt.dbc start";
CM_ "toyota_rav4_hybrid_2017_pt.dbc starts
CM_ "toyota_rav4_hybrid_2017_pt.dbc start";
CM_ "toyota_rav4_hybrid_2017_pt.dbc starts
CM_ "toyota_rav4_hybrid_2017_pt.dbc start";
CM_ "toyota_rav4_hybrid_2017_pt.dbc starts
CM_ "toyota_rav4_hybrid_2017_pt.dbc starts";
CM_ "toyota_rav4_hybrid_2017_pt.dbc starts
CM_ "toyota_rav4_hybrid_2017_pt.dbc starts ";
CM_ "toyota_rav4_hybrid_2017_pt.dbc starts h
CM_ "toyota_rav4_hybrid_2017_pt.dbc start";
CM_ "toyota_rav4_hybrid_2017_pt.dbc starts
CM_ "toyota_rav4_hybrid_2017_pt.dbc start";
CM_ "toyota_rav4_hybrid_2017_pt.dbc starts
CM_ "toyota_rav4_hybrid_2017_pt.dbc starts";
CM_ "toyota_rav4_hybrid_2017_pt.dbc starts
CM_ "toyota_rav4_hybrid_2017_pt.dbc starts ";
CM_ "toyota_rav4_hybrid_2017_pt.dbc starts h
CM_ "toyota_rav4_hybrid_2017_pt.dbc starts";
CM_ "toyota_rav4_hybrid_2017_pt.dbc starts
CM_ "toyota_rav4_hybrid_2017_pt.dbc starts ";
CM_ "toyota_rav4_hybrid_2017_pt.dbc starts h
CM_ "toyota_rav4_hybrid_2017_pt.dbc starts ";
CM_ "toyota_rav4_hybrid_2017_pt.dbc starts h
CM_ "toyota_rav4_hybrid_2017_pt.dbc starts h";
CM_ "toyota_rav4_hybrid_2017_pt.dbc starts he
CM_ "toyota_rav4_hybrid_2017_pt.dbc star";
CM_ "toyota_rav4_hybrid_2017_pt.dbc start
CM_ "toyota_rav4_hybrid_2017_pt.dbc start";
CM_ "toyota_rav4_hybrid_2017_pt.dbc starts
CM_ "toyota_rav4_hybrid_2017_pt.dbc star";
CM_ "toyota_rav4_hybrid_2017_pt.dbc start
CM_ "toyota_rav4_hybrid_2017_pt.dbc start";
CM_ "toyota_rav4_hybrid_2017_pt.dbc starts
CM_ "toyota_rav4_hybrid_2017_pt.dbc start";
CM_ "toyota_rav4_hybrid_2017_pt.dbc starts
CM_ "toyota_rav4_hybrid_2017_pt.dbc start";
CM_ "toyota_rav4_hybrid_2017_pt.dbc starts
CM_ "toyota_rav4_hybrid_2017_pt.dbc starts";
CM_ "toyota_rav4_hybrid_2017_pt.dbc starts
CM_ "toyota_rav4_hybrid_2017_pt.dbc starts ";
CM_ "toyota_rav4_hybrid_2017_pt.dbc starts h
CM_ "toyota_rav4_hybrid_2017_pt.dbc start";
CM_ "toyota_rav4_hybrid_2017_pt.dbc starts
CM_ "toyota_rav4_hybrid_2017_pt.dbc start";
CM_ "toyota_rav4_hybrid_2017_pt.dbc starts
CM_ "toyota_rav4_hybrid_2017_pt.dbc starts";
CM_ "toyota_rav4_hybrid_2017_pt.dbc starts
CM_ "toyota_rav4_hybrid_2017_pt.dbc starts ";
CM_ "toyota_rav4_hybrid_2017_pt.dbc starts h
CM_ "toyota_rav4_hybrid_2017_pt.dbc starts";
CM_ "toyota_rav4_hybrid_2017_pt.dbc starts
CM_ "toyota_rav4_hybrid_2017_pt.dbc starts ";
CM_ "toyota_rav4_hybrid_2017_pt.dbc starts h
CM_ "toyota_rav4_hybrid_2017_pt.dbc starts ";
CM_ "toyota_rav4_hybrid_2017_pt.dbc starts h
CM_ "toyota_rav4_hybrid_2017_pt.dbc starts h";
CM_ "toyota_rav4_hybrid_2017_pt.dbc starts he
CM_ "toyota_rav4_hybrid_2017_pt.dbc start";
CM_ "toyota_rav4_hybrid_2017_pt.dbc starts
CM_ "toyota_rav4_hybrid_2017_pt.dbc start";
CM_ "toyota_rav4_hybrid_2017_pt.dbc starts
CM_ "toyota_rav4_hybrid_2017_pt.dbc starts";
CM_ "toyota_rav4_hybrid_2017_pt.dbc starts
CM_ "toyota_rav4_hybrid_2017_pt.dbc starts ";
CM_ "toyota_rav4_hybrid_2017_pt.dbc starts h
CM_ "toyota_rav4_hybrid_2017_pt.dbc starts";
CM_ "toyota_rav4_hybrid_2017_pt.dbc starts
CM_ "toyota_rav4_hybrid_2017_pt.dbc starts ";
CM_ "toyota_rav4_hybrid_2017_pt.dbc starts h
CM_ "toyota_rav4_hybrid_2017_pt.dbc starts ";
CM_ "toyota_rav4_hybrid_2017_pt.dbc starts h
CM_ "toyota_rav4_hybrid_2017_pt.dbc starts h";
CM_ "toyota_rav4_hybrid_2017_pt.dbc starts he
CM_ "toyota_rav4_hybrid_2017_pt.dbc starts";
CM_ "toyota_rav4_hybrid_2017_pt.dbc starts
CM_ "toyota_rav4_hybrid_2017_pt.dbc starts ";
CM_ "toyota_rav4_hybrid_2017_pt.dbc starts h
CM_ "toyota_rav4_hybrid_2017_pt.dbc starts ";
CM_ "toyota_rav4_hybrid_2017_pt.dbc starts h
CM_ "toyota_rav4_hybrid_2017_pt.dbc starts h";
CM_ "toyota_rav4_hybrid_2017_pt.dbc starts he
CM_ "toyota_rav4_hybrid_2017_pt.dbc starts ";
CM_ "toyota_rav4_hybrid_2017_pt.dbc starts h
CM_ "toyota_rav4_hybrid_2017_pt.dbc starts h";
CM_ "toyota_rav4_hybrid_2017_pt.dbc starts he
CM_ "toyota_rav4_hybrid_2017_pt.dbc starts h";
CM_ "toyota_rav4_hybrid_2017_pt.dbc starts he
CM_ "toyota_rav4_hybrid_2017_pt.dbc starts he";
CM_ "toyota_rav4_hybrid_2017_pt.dbc starts her
CM_ "toyota_rav4_hybrid_2017_pt.dbc s";
CM_ "toyota_rav4_hybrid_2017_pt.dbc st
CM_ "toyota_rav4_hybrid_2017_pt.dbc st";
CM_ "toyota_rav4_hybrid_2017_pt.dbc sta
CM_ "toyota_rav4_hybrid_2017_pt.dbc st";
CM_ "toyota_rav4_hybrid_2017_pt.dbc sta
CM_ "toyota_rav4_hybrid_2017_pt.dbc sta";
CM_ "toyota_rav4_hybrid_2017_pt.dbc star
CM_ "toyota_rav4_hybrid_2017_pt.dbc st";
CM_ "toyota_rav4_hybrid_2017_pt.dbc sta
CM_ "toyota_rav4_hybrid_2017_pt.dbc sta";
CM_ "toyota_rav4_hybrid_2017_pt.dbc star
CM_ "toyota_rav4_hybrid_2017_pt.dbc sta";
CM_ "toyota_rav4_hybrid_2017_pt.dbc star
CM_ "toyota_rav4_hybrid_2017_pt.dbc star";
CM_ "toyota_rav4_hybrid_2017_pt.dbc start
CM_ "toyota_rav4_hybrid_2017_pt.dbc st";
CM_ "toyota_rav4_hybrid_2017_pt.dbc sta
CM_ "toyota_rav4_hybrid_2017_pt.dbc sta";
CM_ "toyota_rav4_hybrid_2017_pt.dbc star
CM_ "toyota_rav4_hybrid_2017_pt.dbc sta";
CM_ "toyota_rav4_hybrid_2017_pt.dbc star
CM_ "toyota_rav4_hybrid_2017_pt.dbc star";
CM_ "toyota_rav4_hybrid_2017_pt.dbc start
CM_ "toyota_rav4_hybrid_2017_pt.dbc sta";
CM_ "toyota_rav4_hybrid_2017_pt.dbc star
CM_ "toyota_rav4_hybrid_2017_pt.dbc star";
CM_ "toyota_rav4_hybrid_2017_pt.dbc start
CM_ "toyota_rav4_hybrid_2017_pt.dbc star";
CM_ "toyota_rav4_hybrid_2017_pt.dbc start
CM_ "toyota_rav4_hybrid_2017_pt.dbc start";
CM_ "toyota_rav4_hybrid_2017_pt.dbc starts
CM_ "toyota_rav4_hybrid_2017_pt.dbc s";
CM_ "toyota_rav4_hybrid_2017_pt.dbc st
CM_ "toyota_rav4_hybrid_2017_pt.dbc st";
CM_ "toyota_rav4_hybrid_2017_pt.dbc sta
CM_ "toyota_rav4_hybrid_2017_pt.dbc st";
CM_ "toyota_rav4_hybrid_2017_pt.dbc sta
CM_ "toyota_rav4_hybrid_2017_pt.dbc sta";
CM_ "toyota_rav4_hybrid_2017_pt.dbc star
CM_ "toyota_rav4_hybrid_2017_pt.dbc st";
CM_ "toyota_rav4_hybrid_2017_pt.dbc sta
CM_ "toyota_rav4_hybrid_2017_pt.dbc sta";
CM_ "toyota_rav4_hybrid_2017_pt.dbc star
CM_ "toyota_rav4_hybrid_2017_pt.dbc sta";
CM_ "toyota_rav4_hybrid_2017_pt.dbc star
CM_ "toyota_rav4_hybrid_2017_pt.dbc star";
CM_ "toyota_rav4_hybrid_2017_pt.dbc start
CM_ "toyota_rav4_hybrid_2017_pt.dbc st";
CM_ "toyota_rav4_hybrid_2017_pt.dbc sta
CM_ "toyota_rav4_hybrid_2017_pt.dbc sta";
CM_ "toyota_rav4_hybrid_2017_pt.dbc star
CM_ "toyota_rav4_hybrid_2017_pt.dbc sta";
CM_ "toyota_rav4_hybrid_2017_pt.dbc star
CM_ "toyota_rav4_hybrid_2017_pt.dbc star";
CM_ "toyota_rav4_hybrid_2017_pt.dbc start
CM_ "toyota_rav4_hybrid_2017_pt.dbc sta";
CM_ "toyota_rav4_hybrid_2017_pt.dbc star
CM_ "toyota_rav4_hybrid_2017_pt.dbc star";
CM_ "toyota_rav4_hybrid_2017_pt.dbc start
CM_ "toyota_rav4_hybrid_2017_pt.dbc star";
CM_ "toyota_rav4_hybrid_2017_pt.dbc start
CM_ "toyota_rav4_hybrid_2017_pt.dbc start";
CM_ "toyota_rav4_hybrid_2017_pt.dbc starts
CM_ "toyota_rav4_hybrid_2017_pt.dbc st";
CM_ "toyota_rav4_hybrid_2017_pt.dbc sta
CM_ "toyota_rav4_hybrid_2017_pt.dbc sta";
CM_ "toyota_rav4_hybrid_2017_pt.dbc star
CM_ "toyota_rav4_hybrid_2017_pt.dbc sta";
CM_ "toyota_rav4_hybrid_2017_pt.dbc star
CM_ "toyota_rav4_hybrid_2017_pt.dbc star";
CM_ "toyota_rav4_hybrid_2017_pt.dbc start
CM_ "toyota_rav4_hybrid_2017_pt.dbc sta";
CM_ "toyota_rav4_hybrid_2017_pt.dbc star
CM_ "toyota_rav4_hybrid_2017_pt.dbc star";
CM_ "toyota_rav4_hybrid_2017_pt.dbc start
CM_ "toyota_rav4_hybrid_2017_pt.dbc star";
CM_ "toyota_rav4_hybrid_2017_pt.dbc start
CM_ "toyota_rav4_hybrid_2017_pt.dbc start";
CM_ "toyota_rav4_hybrid_2017_pt.dbc starts
CM_ "toyota_rav4_hybrid_2017_pt.dbc st";
CM_ "toyota_rav4_hybrid_2017_pt.dbc sta
CM_ "toyota_rav4_hybrid_2017_pt.dbc sta";
CM_ "toyota_rav4_hybrid_2017_pt.dbc star
CM_ "toyota_rav4_hybrid_2017_pt.dbc sta";
CM_ "toyota_rav4_hybrid_2017_pt.dbc star
CM_ "toyota_rav4_hybrid_2017_pt.dbc star";
CM_ "toyota_rav4_hybrid_2017_pt.dbc start
CM_ "toyota_rav4_hybrid_2017_pt.dbc sta";
CM_ "toyota_rav4_hybrid_2017_pt.dbc star
CM_ "toyota_rav4_hybrid_2017_pt.dbc star";
CM_ "toyota_rav4_hybrid_2017_pt.dbc start
CM_ "toyota_rav4_hybrid_2017_pt.dbc star";
CM_ "toyota_rav4_hybrid_2017_pt.dbc start
CM_ "toyota_rav4_hybrid_2017_pt.dbc start";
CM_ "toyota_rav4_hybrid_2017_pt.dbc starts
CM_ "toyota_rav4_hybrid_2017_pt.dbc sta";
CM_ "toyota_rav4_hybrid_2017_pt.dbc star
CM_ "toyota_rav4_hybrid_2017_pt.dbc star";
CM_ "toyota_rav4_hybrid_2017_pt.dbc start
CM_ "toyota_rav4_hybrid_2017_pt.dbc star";
CM_ "toyota_rav4_hybrid_2017_pt.dbc start
CM_ "toyota_rav4_hybrid_2017_pt.dbc start";
CM_ "toyota_rav4_hybrid_2017_pt.dbc starts
CM_ "toyota_rav4_hybrid_2017_pt.dbc sta";
CM_ "toyota_rav4_hybrid_2017_pt.dbc star
CM_ "toyota_rav4_hybrid_2017_pt.dbc star";
CM_ "toyota_rav4_hybrid_2017_pt.dbc start
CM_ "toyota_rav4_hybrid_2017_pt.dbc star";
CM_ "toyota_rav4_hybrid_2017_pt.dbc start
CM_ "toyota_rav4_hybrid_2017_pt.dbc start";
CM_ "toyota_rav4_hybrid_2017_pt.dbc starts
CM_ "toyota_rav4_hybrid_2017_pt.dbc star";
CM_ "toyota_rav4_hybrid_2017_pt.dbc start
CM_ "toyota_rav4_hybrid_2017_pt.dbc start";
CM_ "toyota_rav4_hybrid_2017_pt.dbc starts
CM_ "toyota_rav4_hybrid_2017_pt.dbc star";
CM_ "toyota_rav4_hybrid_2017_pt.dbc start
CM_ "toyota_rav4_hybrid_2017_pt.dbc start";
CM_ "toyota_rav4_hybrid_2017_pt.dbc starts
CM_ "toyota_rav4_hybrid_2017_pt.dbc start";
CM_ "toyota_rav4_hybrid_2017_pt.dbc starts
CM_ "toyota_rav4_hybrid_2017_pt.dbc start";
CM_ "toyota_rav4_hybrid_2017_pt.dbc starts
CM_ "toyota_rav4_hybrid_2017_pt.dbc starts";
CM_ "toyota_rav4_hybrid_2017_pt.dbc starts
CM_ "toyota_rav4_hybrid_2017_pt.dbc starts ";
CM_ "toyota_rav4_hybrid_2017_pt.dbc starts h
CM_ "toyota_rav4_hybrid_2017_pt.dbc st";
CM_ "toyota_rav4_hybrid_2017_pt.dbc sta
CM_ "toyota_rav4_hybrid_2017_pt.dbc sta";
CM_ "toyota_rav4_hybrid_2017_pt.dbc star
CM_ "toyota_rav4_hybrid_2017_pt.dbc sta";
CM_ "toyota_rav4_hybrid_2017_pt.dbc star
CM_ "toyota_rav4_hybrid_2017_pt.dbc star";
CM_ "toyota_rav4_hybrid_2017_pt.dbc start
CM_ "toyota_rav4_hybrid_2017_pt.dbc sta";
CM_ "toyota_rav4_hybrid_2017_pt.dbc star
CM_ "toyota_rav4_hybrid_2017_pt.dbc star";
CM_ "toyota_rav4_hybrid_2017_pt.dbc start
CM_ "toyota_rav4_hybrid_2017_pt.dbc star";
CM_ "toyota_rav4_hybrid_2017_pt.dbc start
CM_ "toyota_rav4_hybrid_2017_pt.dbc start";
CM_ "toyota_rav4_hybrid_2017_pt.dbc starts
CM_ "toyota_rav4_hybrid_2017_pt.dbc st";
CM_ "toyota_rav4_hybrid_2017_pt.dbc sta
CM_ "toyota_rav4_hybrid_2017_pt.dbc sta";
CM_ "toyota_rav4_hybrid_2017_pt.dbc star
CM_ "toyota_rav4_hybrid_2017_pt.dbc sta";
CM_ "toyota_rav4_hybrid_2017_pt.dbc star
CM_ "toyota_rav4_hybrid_2017_pt.dbc star";
CM_ "toyota_rav4_hybrid_2017_pt.dbc start
CM_ "toyota_rav4_hybrid_2017_pt.dbc sta";
CM_ "toyota_rav4_hybrid_2017_pt.dbc star
CM_ "toyota_rav4_hybrid_2017_pt.dbc star";
CM_ "toyota_rav4_hybrid_2017_pt.dbc start
CM_ "toyota_rav4_hybrid_2017_pt.dbc star";
CM_ "toyota_rav4_hybrid_2017_pt.dbc start
CM_ "toyota_rav4_hybrid_2017_pt.dbc start";
CM_ "toyota_rav4_hybrid_2017_pt.dbc starts
CM_ "toyota_rav4_hybrid_2017_pt.dbc sta";
CM_ "toyota_rav4_hybrid_2017_pt.dbc star
CM_ "toyota_rav4_hybrid_2017_pt.dbc star";
CM_ "toyota_rav4_hybrid_2017_pt.dbc start
CM_ "toyota_rav4_hybrid_2017_pt.dbc star";
CM_ "toyota_rav4_hybrid_2017_pt.dbc start
CM_ "toyota_rav4_hybrid_2017_pt.dbc start";
CM_ "toyota_rav4_hybrid_2017_pt.dbc starts
CM_ "toyota_rav4_hybrid_2017_pt.dbc sta";
CM_ "toyota_rav4_hybrid_2017_pt.dbc star
CM_ "toyota_rav4_hybrid_2017_pt.dbc star";
CM_ "toyota_rav4_hybrid_2017_pt.dbc start
CM_ "toyota_rav4_hybrid_2017_pt.dbc star";
CM_ "toyota_rav4_hybrid_2017_pt.dbc start
CM_ "toyota_rav4_hybrid_2017_pt.dbc start";
CM_ "toyota_rav4_hybrid_2017_pt.dbc starts
CM_ "toyota_rav4_hybrid_2017_pt.dbc star";
CM_ "toyota_rav4_hybrid_2017_pt.dbc start
CM_ "toyota_rav4_hybrid_2017_pt.dbc start";
CM_ "toyota_rav4_hybrid_2017_pt.dbc starts
CM_ "toyota_rav4_hybrid_2017_pt.dbc star";
CM_ "toyota_rav4_hybrid_2017_pt.dbc start
CM_ "toyota_rav4_hybrid_2017_pt.dbc start";
CM_ "toyota_rav4_hybrid_2017_pt.dbc starts
CM_ "toyota_rav4_hybrid_2017_pt.dbc start";
CM_ "toyota_rav4_hybrid_2017_pt.dbc starts
CM_ "toyota_rav4_hybrid_2017_pt.dbc start";
CM_ "toyota_rav4_hybrid_2017_pt.dbc starts
CM_ "toyota_rav4_hybrid_2017_pt.dbc starts";
CM_ "toyota_rav4_hybrid_2017_pt.dbc starts
CM_ "toyota_rav4_hybrid_2017_pt.dbc starts ";
CM_ "toyota_rav4_hybrid_2017_pt.dbc starts h
CM_ "toyota_rav4_hybrid_2017_pt.dbc sta";
CM_ "toyota_rav4_hybrid_2017_pt.dbc star
CM_ "toyota_rav4_hybrid_2017_pt.dbc star";
CM_ "toyota_rav4_hybrid_2017_pt.dbc start
CM_ "toyota_rav4_hybrid_2017_pt.dbc star";
CM_ "toyota_rav4_hybrid_2017_pt.dbc start
CM_ "toyota_rav4_hybrid_2017_pt.dbc start";
CM_ "toyota_rav4_hybrid_2017_pt.dbc starts
CM_ "toyota_rav4_hybrid_2017_pt.dbc sta";
CM_ "toyota_rav4_hybrid_2017_pt.dbc star
CM_ "toyota_rav4_hybrid_2017_pt.dbc star";
CM_ "toyota_rav4_hybrid_2017_pt.dbc start
CM_ "toyota_rav4_hybrid_2017_pt.dbc star";
CM_ "toyota_rav4_hybrid_2017_pt.dbc start
CM_ "toyota_rav4_hybrid_2017_pt.dbc start";
CM_ "toyota_rav4_hybrid_2017_pt.dbc starts
CM_ "toyota_rav4_hybrid_2017_pt.dbc star";
CM_ "toyota_rav4_hybrid_2017_pt.dbc start
CM_ "toyota_rav4_hybrid_2017_pt.dbc start";
CM_ "toyota_rav4_hybrid_2017_pt.dbc starts
CM_ "toyota_rav4_hybrid_2017_pt.dbc star";
CM_ "toyota_rav4_hybrid_2017_pt.dbc start
CM_ "toyota_rav4_hybrid_2017_pt.dbc start";
CM_ "toyota_rav4_hybrid_2017_pt.dbc starts
CM_ "toyota_rav4_hybrid_2017_pt.dbc start";
CM_ "toyota_rav4_hybrid_2017_pt.dbc starts
CM_ "toyota_rav4_hybrid_2017_pt.dbc start";
CM_ "toyota_rav4_hybrid_2017_pt.dbc starts
CM_ "toyota_rav4_hybrid_2017_pt.dbc starts";
CM_ "toyota_rav4_hybrid_2017_pt.dbc starts
CM_ "toyota_rav4_hybrid_2017_pt.dbc starts ";
CM_ "toyota_rav4_hybrid_2017_pt.dbc starts h
CM_ "toyota_rav4_hybrid_2017_pt.dbc star";
CM_ "toyota_rav4_hybrid_2017_pt.dbc start
CM_ "toyota_rav4_hybrid_2017_pt.dbc start";
CM_ "toyota_rav4_hybrid_2017_pt.dbc starts
CM_ "toyota_rav4_hybrid_2017_pt.dbc star";
CM_ "toyota_rav4_hybrid_2017_pt.dbc start
CM_ "toyota_rav4_hybrid_2017_pt.dbc start";
CM_ "toyota_rav4_hybrid_2017_pt.dbc starts
CM_ "toyota_rav4_hybrid_2017_pt.dbc start";
CM_ "toyota_rav4_hybrid_2017_pt.dbc starts
CM_ "toyota_rav4_hybrid_2017_pt.dbc start";
CM_ "toyota_rav4_hybrid_2017_pt.dbc starts
CM_ "toyota_rav4_hybrid_2017_pt.dbc starts";
CM_ "toyota_rav4_hybrid_2017_pt.dbc starts
CM_ "toyota_rav4_hybrid_2017_pt.dbc starts ";
CM_ "toyota_rav4_hybrid_2017_pt.dbc starts h
CM_ "toyota_rav4_hybrid_2017_pt.dbc start";
CM_ "toyota_rav4_hybrid_2017_pt.dbc starts
CM_ "toyota_rav4_hybrid_2017_pt.dbc start";
CM_ "toyota_rav4_hybrid_2017_pt.dbc starts
CM_ "toyota_rav4_hybrid_2017_pt.dbc starts";
CM_ "toyota_rav4_hybrid_2017_pt.dbc starts
CM_ "toyota_rav4_hybrid_2017_pt.dbc starts ";
CM_ "toyota_rav4_hybrid_2017_pt.dbc starts h
CM_ "toyota_rav4_hybrid_2017_pt.dbc starts";
CM_ "toyota_rav4_hybrid_2017_pt.dbc starts
CM_ "toyota_rav4_hybrid_2017_pt.dbc starts ";
CM_ "toyota_rav4_hybrid_2017_pt.dbc starts h
CM_ "toyota_rav4_hybrid_2017_pt.dbc starts ";
CM_ "toyota_rav4_hybrid_2017_pt.dbc starts h
CM_ "toyota_rav4_hybrid_2017_pt.dbc starts h";
CM_ "toyota_rav4_hybrid_2017_pt.dbc starts he
CM_ "toyota_rav4_hybrid_2017_pt.dbc st";
CM_ "toyota_rav4_hybrid_2017_pt.dbc sta
CM_ "toyota_rav4_hybrid_2017_pt.dbc sta";
CM_ "toyota_rav4_hybrid_2017_pt.dbc star
CM_ "toyota_rav4_hybrid_2017_pt.dbc sta";
CM_ "toyota_rav4_hybrid_2017_pt.dbc star
CM_ "toyota_rav4_hybrid_2017_pt.dbc star";
CM_ "toyota_rav4_hybrid_2017_pt.dbc start
CM_ "toyota_rav4_hybrid_2017_pt.dbc sta";
CM_ "toyota_rav4_hybrid_2017_pt.dbc star
CM_ "toyota_rav4_hybrid_2017_pt.dbc star";
CM_ "toyota_rav4_hybrid_2017_pt.dbc start
CM_ "toyota_rav4_hybrid_2017_pt.dbc star";
CM_ "toyota_rav4_hybrid_2017_pt.dbc start
CM_ "toyota_rav4_hybrid_2017_pt.dbc start";
CM_ "toyota_rav4_hybrid_2017_pt.dbc starts
CM_ "toyota_rav4_hybrid_2017_pt.dbc st";
CM_ "toyota_rav4_hybrid_2017_pt.dbc sta
CM_ "toyota_rav4_hybrid_2017_pt.dbc sta";
CM_ "toyota_rav4_hybrid_2017_pt.dbc star
CM_ "toyota_rav4_hybrid_2017_pt.dbc sta";
CM_ "toyota_rav4_hybrid_2017_pt.dbc star
CM_ "toyota_rav4_hybrid_2017_pt.dbc star";
CM_ "toyota_rav4_hybrid_2017_pt.dbc start
CM_ "toyota_rav4_hybrid_2017_pt.dbc sta";
CM_ "toyota_rav4_hybrid_2017_pt.dbc star
CM_ "toyota_rav4_hybrid_2017_pt.dbc star";
CM_ "toyota_rav4_hybrid_2017_pt.dbc start
CM_ "toyota_rav4_hybrid_2017_pt.dbc star";
CM_ "toyota_rav4_hybrid_2017_pt.dbc start
CM_ "toyota_rav4_hybrid_2017_pt.dbc start";
CM_ "toyota_rav4_hybrid_2017_pt.dbc starts
CM_ "toyota_rav4_hybrid_2017_pt.dbc sta";
CM_ "toyota_rav4_hybrid_2017_pt.dbc star
CM_ "toyota_rav4_hybrid_2017_pt.dbc star";
CM_ "toyota_rav4_hybrid_2017_pt.dbc start
CM_ "toyota_rav4_hybrid_2017_pt.dbc star";
CM_ "toyota_rav4_hybrid_2017_pt.dbc start
CM_ "toyota_rav4_hybrid_2017_pt.dbc start";
CM_ "toyota_rav4_hybrid_2017_pt.dbc starts
CM_ "toyota_rav4_hybrid_2017_pt.dbc sta";
CM_ "toyota_rav4_hybrid_2017_pt.dbc star
CM_ "toyota_rav4_hybrid_2017_pt.dbc star";
CM_ "toyota_rav4_hybrid_2017_pt.dbc start
CM_ "toyota_rav4_hybrid_2017_pt.dbc star";
CM_ "toyota_rav4_hybrid_2017_pt.dbc start
CM_ "toyota_rav4_hybrid_2017_pt.dbc start";
CM_ "toyota_rav4_hybrid_2017_pt.dbc starts
CM_ "toyota_rav4_hybrid_2017_pt.dbc star";
CM_ "toyota_rav4_hybrid_2017_pt.dbc start
CM_ "toyota_rav4_hybrid_2017_pt.dbc start";
CM_ "toyota_rav4_hybrid_2017_pt.dbc starts
CM_ "toyota_rav4_hybrid_2017_pt.dbc star";
CM_ "toyota_rav4_hybrid_2017_pt.dbc start
CM_ "toyota_rav4_hybrid_2017_pt.dbc start";
CM_ "toyota_rav4_hybrid_2017_pt.dbc starts
CM_ "toyota_rav4_hybrid_2017_pt.dbc start";
CM_ "toyota_rav4_hybrid_2017_pt.dbc starts
CM_ "toyota_rav4_hybrid_2017_pt.dbc start";
CM_ "toyota_rav4_hybrid_2017_pt.dbc starts
CM_ "toyota_rav4_hybrid_2017_pt.dbc starts";
CM_ "toyota_rav4_hybrid_2017_pt.dbc starts
CM_ "toyota_rav4_hybrid_2017_pt.dbc starts ";
CM_ "toyota_rav4_hybrid_2017_pt.dbc starts h
CM_ "toyota_rav4_hybrid_2017_pt.dbc sta";
CM_ "toyota_rav4_hybrid_2017_pt.dbc star
CM_ "toyota_rav4_hybrid_2017_pt.dbc star";
CM_ "toyota_rav4_hybrid_2017_pt.dbc start
CM_ "toyota_rav4_hybrid_2017_pt.dbc star";
CM_ "toyota_rav4_hybrid_2017_pt.dbc start
CM_ "toyota_rav4_hybrid_2017_pt.dbc start";
CM_ "toyota_rav4_hybrid_2017_pt.dbc starts
CM_ "toyota_rav4_hybrid_2017_pt.dbc sta";
CM_ "toyota_rav4_hybrid_2017_pt.dbc star
CM_ "toyota_rav4_hybrid_2017_pt.dbc star";
CM_ "toyota_rav4_hybrid_2017_pt.dbc start
CM_ "toyota_rav4_hybrid_2017_pt.dbc star";
CM_ "toyota_rav4_hybrid_2017_pt.dbc start
CM_ "toyota_rav4_hybrid_2017_pt.dbc start";
CM_ "toyota_rav4_hybrid_2017_pt.dbc starts
CM_ "toyota_rav4_hybrid_2017_pt.dbc star";
CM_ "toyota_rav4_hybrid_2017_pt.dbc start
CM_ "toyota_rav4_hybrid_2017_pt.dbc start";
CM_ "toyota_rav4_hybrid_2017_pt.dbc starts
CM_ "toyota_rav4_hybrid_2017_pt.dbc star";
CM_ "toyota_rav4_hybrid_2017_pt.dbc start
CM_ "toyota_rav4_hybrid_2017_pt.dbc start";
CM_ "toyota_rav4_hybrid_2017_pt.dbc starts
CM_ "toyota_rav4_hybrid_2017_pt.dbc start";
CM_ "toyota_rav4_hybrid_2017_pt.dbc starts
CM_ "toyota_rav4_hybrid_2017_pt.dbc start";
CM_ "toyota_rav4_hybrid_2017_pt.dbc starts
CM_ "toyota_rav4_hybrid_2017_pt.dbc starts";
CM_ "toyota_rav4_hybrid_2017_pt.dbc starts
CM_ "toyota_rav4_hybrid_2017_pt.dbc starts ";
CM_ "toyota_rav4_hybrid_2017_pt.dbc starts h
CM_ "toyota_rav4_hybrid_2017_pt.dbc star";
CM_ "toyota_rav4_hybrid_2017_pt.dbc start
CM_ "toyota_rav4_hybrid_2017_pt.dbc start";
CM_ "toyota_rav4_hybrid_2017_pt.dbc starts
CM_ "toyota_rav4_hybrid_2017_pt.dbc star";
CM_ "toyota_rav4_hybrid_2017_pt.dbc start
CM_ "toyota_rav4_hybrid_2017_pt.dbc start";
CM_ "toyota_rav4_hybrid_2017_pt.dbc starts
CM_ "toyota_rav4_hybrid_2017_pt.dbc start";
CM_ "toyota_rav4_hybrid_2017_pt.dbc starts
CM_ "toyota_rav4_hybrid_2017_pt.dbc start";
CM_ "toyota_rav4_hybrid_2017_pt.dbc starts
CM_ "toyota_rav4_hybrid_2017_pt.dbc starts";
CM_ "toyota_rav4_hybrid_2017_pt.dbc starts
CM_ "toyota_rav4_hybrid_2017_pt.dbc starts ";
CM_ "toyota_rav4_hybrid_2017_pt.dbc starts h
CM_ "toyota_rav4_hybrid_2017_pt.dbc start";
CM_ "toyota_rav4_hybrid_2017_pt.dbc starts
CM_ "toyota_rav4_hybrid_2017_pt.dbc start";
CM_ "toyota_rav4_hybrid_2017_pt.dbc starts
CM_ "toyota_rav4_hybrid_2017_pt.dbc starts";
CM_ "toyota_rav4_hybrid_2017_pt.dbc starts
CM_ "toyota_rav4_hybrid_2017_pt.dbc starts ";
CM_ "toyota_rav4_hybrid_2017_pt.dbc starts h
CM_ "toyota_rav4_hybrid_2017_pt.dbc starts";
CM_ "toyota_rav4_hybrid_2017_pt.dbc starts
CM_ "toyota_rav4_hybrid_2017_pt.dbc starts ";
CM_ "toyota_rav4_hybrid_2017_pt.dbc starts h
CM_ "toyota_rav4_hybrid_2017_pt.dbc starts ";
CM_ "toyota_rav4_hybrid_2017_pt.dbc starts h
CM_ "toyota_rav4_hybrid_2017_pt.dbc starts h";
CM_ "toyota_rav4_hybrid_2017_pt.dbc starts he
CM_ "toyota_rav4_hybrid_2017_pt.dbc sta";
CM_ "toyota_rav4_hybrid_2017_pt.dbc star
CM_ "toyota_rav4_hybrid_2017_pt.dbc star";
CM_ "toyota_rav4_hybrid_2017_pt.dbc start
CM_ "toyota_rav4_hybrid_2017_pt.dbc star";
CM_ "toyota_rav4_hybrid_2017_pt.dbc start
CM_ "toyota_rav4_hybrid_2017_pt.dbc start";
CM_ "toyota_rav4_hybrid_2017_pt.dbc starts
CM_ "toyota_rav4_hybrid_2017_pt.dbc sta";
CM_ "toyota_rav4_hybrid_2017_pt.dbc star
CM_ "toyota_rav4_hybrid_2017_pt.dbc star";
CM_ "toyota_rav4_hybrid_2017_pt.dbc start
CM_ "toyota_rav4_hybrid_2017_pt.dbc star";
CM_ "toyota_rav4_hybrid_2017_pt.dbc start
CM_ "toyota_rav4_hybrid_2017_pt.dbc start";
CM_ "toyota_rav4_hybrid_2017_pt.dbc starts
CM_ "toyota_rav4_hybrid_2017_pt.dbc star";
CM_ "toyota_rav4_hybrid_2017_pt.dbc start
CM_ "toyota_rav4_hybrid_2017_pt.dbc start";
CM_ "toyota_rav4_hybrid_2017_pt.dbc starts
CM_ "toyota_rav4_hybrid_2017_pt.dbc star";
CM_ "toyota_rav4_hybrid_2017_pt.dbc start
CM_ "toyota_rav4_hybrid_2017_pt.dbc start";
CM_ "toyota_rav4_hybrid_2017_pt.dbc starts
CM_ "toyota_rav4_hybrid_2017_pt.dbc start";
CM_ "toyota_rav4_hybrid_2017_pt.dbc starts
CM_ "toyota_rav4_hybrid_2017_pt.dbc start";
CM_ "toyota_rav4_hybrid_2017_pt.dbc starts
CM_ "toyota_rav4_hybrid_2017_pt.dbc starts";
CM_ "toyota_rav4_hybrid_2017_pt.dbc starts
CM_ "toyota_rav4_hybrid_2017_pt.dbc starts ";
CM_ "toyota_rav4_hybrid_2017_pt.dbc starts h
CM_ "toyota_rav4_hybrid_2017_pt.dbc star";
CM_ "toyota_rav4_hybrid_2017_pt.dbc start
CM_ "toyota_rav4_hybrid_2017_pt.dbc start";
CM_ "toyota_rav4_hybrid_2017_pt.dbc starts
CM_ "toyota_rav4_hybrid_2017_pt.dbc star";
CM_ "toyota_rav4_hybrid_2017_pt.dbc start
CM_ "toyota_rav4_hybrid_2017_pt.dbc start";
CM_ "toyota_rav4_hybrid_2017_pt.dbc starts
CM_ "toyota_rav4_hybrid_2017_pt.dbc start";
CM_ "toyota_rav4_hybrid_2017_pt.dbc starts
CM_ "toyota_rav4_hybrid_2017_pt.dbc start";
CM_ "toyota_rav4_hybrid_2017_pt.dbc starts
CM_ "toyota_rav4_hybrid_2017_pt.dbc starts";
CM_ "toyota_rav4_hybrid_2017_pt.dbc starts
CM_ "toyota_rav4_hybrid_2017_pt.dbc starts ";
CM_ "toyota_rav4_hybrid_2017_pt.dbc starts h
CM_ "toyota_rav4_hybrid_2017_pt.dbc start";
CM_ "toyota_rav4_hybrid_2017_pt.dbc starts
CM_ "toyota_rav4_hybrid_2017_pt.dbc start";
CM_ "toyota_rav4_hybrid_2017_pt.dbc starts
CM_ "toyota_rav4_hybrid_2017_pt.dbc starts";
CM_ "toyota_rav4_hybrid_2017_pt.dbc starts
CM_ "toyota_rav4_hybrid_2017_pt.dbc starts ";
CM_ "toyota_rav4_hybrid_2017_pt.dbc starts h
CM_ "toyota_rav4_hybrid_2017_pt.dbc starts";
CM_ "toyota_rav4_hybrid_2017_pt.dbc starts
CM_ "toyota_rav4_hybrid_2017_pt.dbc starts ";
CM_ "toyota_rav4_hybrid_2017_pt.dbc starts h
CM_ "toyota_rav4_hybrid_2017_pt.dbc starts ";
CM_ "toyota_rav4_hybrid_2017_pt.dbc starts h
CM_ "toyota_rav4_hybrid_2017_pt.dbc starts h";
CM_ "toyota_rav4_hybrid_2017_pt.dbc starts he
CM_ "toyota_rav4_hybrid_2017_pt.dbc star";
CM_ "toyota_rav4_hybrid_2017_pt.dbc start
CM_ "toyota_rav4_hybrid_2017_pt.dbc start";
CM_ "toyota_rav4_hybrid_2017_pt.dbc starts
CM_ "toyota_rav4_hybrid_2017_pt.dbc star";
CM_ "toyota_rav4_hybrid_2017_pt.dbc start
CM_ "toyota_rav4_hybrid_2017_pt.dbc start";
CM_ "toyota_rav4_hybrid_2017_pt.dbc starts
CM_ "toyota_rav4_hybrid_2017_pt.dbc start";
CM_ "toyota_rav4_hybrid_2017_pt.dbc starts
CM_ "toyota_rav4_hybrid_2017_pt.dbc start";
CM_ "toyota_rav4_hybrid_2017_pt.dbc starts
CM_ "toyota_rav4_hybrid_2017_pt.dbc starts";
CM_ "toyota_rav4_hybrid_2017_pt.dbc starts
CM_ "toyota_rav4_hybrid_2017_pt.dbc starts ";
CM_ "toyota_rav4_hybrid_2017_pt.dbc starts h
CM_ "toyota_rav4_hybrid_2017_pt.dbc start";
CM_ "toyota_rav4_hybrid_2017_pt.dbc starts
CM_ "toyota_rav4_hybrid_2017_pt.dbc start";
CM_ "toyota_rav4_hybrid_2017_pt.dbc starts
CM_ "toyota_rav4_hybrid_2017_pt.dbc starts";
CM_ "toyota_rav4_hybrid_2017_pt.dbc starts
CM_ "toyota_rav4_hybrid_2017_pt.dbc starts ";
CM_ "toyota_rav4_hybrid_2017_pt.dbc starts h
CM_ "toyota_rav4_hybrid_2017_pt.dbc starts";
CM_ "toyota_rav4_hybrid_2017_pt.dbc starts
CM_ "toyota_rav4_hybrid_2017_pt.dbc starts ";
CM_ "toyota_rav4_hybrid_2017_pt.dbc starts h
CM_ "toyota_rav4_hybrid_2017_pt.dbc starts ";
CM_ "toyota_rav4_hybrid_2017_pt.dbc starts h
CM_ "toyota_rav4_hybrid_2017_pt.dbc starts h";
CM_ "toyota_rav4_hybrid_2017_pt.dbc starts he
CM_ "toyota_rav4_hybrid_2017_pt.dbc start";
CM_ "toyota_rav4_hybrid_2017_pt.dbc starts
CM_ "toyota_rav4_hybrid_2017_pt.dbc start";
CM_ "toyota_rav4_hybrid_2017_pt.dbc starts
CM_ "toyota_rav4_hybrid_2017_pt.dbc starts";
CM_ "toyota_rav4_hybrid_2017_pt.dbc starts
CM_ "toyota_rav4_hybrid_2017_pt.dbc starts ";
CM_ "toyota_rav4_hybrid_2017_pt.dbc starts h
CM_ "toyota_rav4_hybrid_2017_pt.dbc starts";
CM_ "toyota_rav4_hybrid_2017_pt.dbc starts
CM_ "toyota_rav4_hybrid_2017_pt.dbc starts ";
CM_ "toyota_rav4_hybrid_2017_pt.dbc starts h
CM_ "toyota_rav4_hybrid_2017_pt.dbc starts ";
CM_ "toyota_rav4_hybrid_2017_pt.dbc starts h
CM_ "toyota_rav4_hybrid_2017_pt.dbc starts h";
CM_ "toyota_rav4_hybrid_2017_pt.dbc starts he
CM_ "toyota_rav4_hybrid_2017_pt.dbc starts";
CM_ "toyota_rav4_hybrid_2017_pt.dbc starts
CM_ "toyota_rav4_hybrid_2017_pt.dbc starts ";
CM_ "toyota_rav4_hybrid_2017_pt.dbc starts h
CM_ "toyota_rav4_hybrid_2017_pt.dbc starts ";
CM_ "toyota_rav4_hybrid_2017_pt.dbc starts h
CM_ "toyota_rav4_hybrid_2017_pt.dbc starts h";
CM_ "toyota_rav4_hybrid_2017_pt.dbc starts he
CM_ "toyota_rav4_hybrid_2017_pt.dbc starts ";
CM_ "toyota_rav4_hybrid_2017_pt.dbc starts h
CM_ "toyota_rav4_hybrid_2017_pt.dbc starts h";
CM_ "toyota_rav4_hybrid_2017_pt.dbc starts he
CM_ "toyota_rav4_hybrid_2017_pt.dbc starts h";
CM_ "toyota_rav4_hybrid_2017_pt.dbc starts he
CM_ "toyota_rav4_hybrid_2017_pt.dbc starts he";
CM_ "toyota_rav4_hybrid_2017_pt.dbc starts her
CM_ "toyota_rav4_hybrid_2017_pt.dbc st";
CM_ "toyota_rav4_hybrid_2017_pt.dbc sta
CM_ "toyota_rav4_hybrid_2017_pt.dbc sta";
CM_ "toyota_rav4_hybrid_2017_pt.dbc star
CM_ "toyota_rav4_hybrid_2017_pt.dbc sta";
CM_ "toyota_rav4_hybrid_2017_pt.dbc star
CM_ "toyota_rav4_hybrid_2017_pt.dbc star";
CM_ "toyota_rav4_hybrid_2017_pt.dbc start
CM_ "toyota_rav4_hybrid_2017_pt.dbc sta";
CM_ "toyota_rav4_hybrid_2017_pt.dbc star
CM_ "toyota_rav4_hybrid_2017_pt.dbc star";
CM_ "toyota_rav4_hybrid_2017_pt.dbc start
CM_ "toyota_rav4_hybrid_2017_pt.dbc star";
CM_ "toyota_rav4_hybrid_2017_pt.dbc start
CM_ "toyota_rav4_hybrid_2017_pt.dbc start";
CM_ "toyota_rav4_hybrid_2017_pt.dbc starts
CM_ "toyota_rav4_hybrid_2017_pt.dbc st";
CM_ "toyota_rav4_hybrid_2017_pt.dbc sta
CM_ "toyota_rav4_hybrid_2017_pt.dbc sta";
CM_ "toyota_rav4_hybrid_2017_pt.dbc star
CM_ "toyota_rav4_hybrid_2017_pt.dbc sta";
CM_ "toyota_rav4_hybrid_2017_pt.dbc star
CM_ "toyota_rav4_hybrid_2017_pt.dbc star";
CM_ "toyota_rav4_hybrid_2017_pt.dbc start
CM_ "toyota_rav4_hybrid_2017_pt.dbc sta";
CM_ "toyota_rav4_hybrid_2017_pt.dbc star
CM_ "toyota_rav4_hybrid_2017_pt.dbc star";
CM_ "toyota_rav4_hybrid_2017_pt.dbc start
CM_ "toyota_rav4_hybrid_2017_pt.dbc star";
CM_ "toyota_rav4_hybrid_2017_pt.dbc start
CM_ "toyota_rav4_hybrid_2017_pt.dbc start";
CM_ "toyota_rav4_hybrid_2017_pt.dbc starts
CM_ "toyota_rav4_hybrid_2017_pt.dbc sta";
CM_ "toyota_rav4_hybrid_2017_pt.dbc star
CM_ "toyota_rav4_hybrid_2017_pt.dbc star";
CM_ "toyota_rav4_hybrid_2017_pt.dbc start
CM_ "toyota_rav4_hybrid_2017_pt.dbc star";
CM_ "toyota_rav4_hybrid_2017_pt.dbc start
CM_ "toyota_rav4_hybrid_2017_pt.dbc start";
CM_ "toyota_rav4_hybrid_2017_pt.dbc starts
CM_ "toyota_rav4_hybrid_2017_pt.dbc sta";
CM_ "toyota_rav4_hybrid_2017_pt.dbc star
CM_ "toyota_rav4_hybrid_2017_pt.dbc star";
CM_ "toyota_rav4_hybrid_2017_pt.dbc start
CM_ "toyota_rav4_hybrid_2017_pt.dbc star";
CM_ "toyota_rav4_hybrid_2017_pt.dbc start
CM_ "toyota_rav4_hybrid_2017_pt.dbc start";
CM_ "toyota_rav4_hybrid_2017_pt.dbc starts
CM_ "toyota_rav4_hybrid_2017_pt.dbc star";
CM_ "toyota_rav4_hybrid_2017_pt.dbc start
CM_ "toyota_rav4_hybrid_2017_pt.dbc start";
CM_ "toyota_rav4_hybrid_2017_pt.dbc starts
CM_ "toyota_rav4_hybrid_2017_pt.dbc star";
CM_ "toyota_rav4_hybrid_2017_pt.dbc start
CM_ "toyota_rav4_hybrid_2017_pt.dbc start";
CM_ "toyota_rav4_hybrid_2017_pt.dbc starts
CM_ "toyota_rav4_hybrid_2017_pt.dbc start";
CM_ "toyota_rav4_hybrid_2017_pt.dbc starts
CM_ "toyota_rav4_hybrid_2017_pt.dbc start";
CM_ "toyota_rav4_hybrid_2017_pt.dbc starts
CM_ "toyota_rav4_hybrid_2017_pt.dbc starts";
CM_ "toyota_rav4_hybrid_2017_pt.dbc starts
CM_ "toyota_rav4_hybrid_2017_pt.dbc starts ";
CM_ "toyota_rav4_hybrid_2017_pt.dbc starts h
CM_ "toyota_rav4_hybrid_2017_pt.dbc sta";
CM_ "toyota_rav4_hybrid_2017_pt.dbc star
CM_ "toyota_rav4_hybrid_2017_pt.dbc star";
CM_ "toyota_rav4_hybrid_2017_pt.dbc start
CM_ "toyota_rav4_hybrid_2017_pt.dbc star";
CM_ "toyota_rav4_hybrid_2017_pt.dbc start
CM_ "toyota_rav4_hybrid_2017_pt.dbc start";
CM_ "toyota_rav4_hybrid_2017_pt.dbc starts
CM_ "toyota_rav4_hybrid_2017_pt.dbc sta";
CM_ "toyota_rav4_hybrid_2017_pt.dbc star
CM_ "toyota_rav4_hybrid_2017_pt.dbc star";
CM_ "toyota_rav4_hybrid_2017_pt.dbc start
CM_ "toyota_rav4_hybrid_2017_pt.dbc star";
CM_ "toyota_rav4_hybrid_2017_pt.dbc start
CM_ "toyota_rav4_hybrid_2017_pt.dbc start";
CM_ "toyota_rav4_hybrid_2017_pt.dbc starts
CM_ "toyota_rav4_hybrid_2017_pt.dbc star";
CM_ "toyota_rav4_hybrid_2017_pt.dbc start
CM_ "toyota_rav4_hybrid_2017_pt.dbc start";
CM_ "toyota_rav4_hybrid_2017_pt.dbc starts
CM_ "toyota_rav4_hybrid_2017_pt.dbc star";
CM_ "toyota_rav4_hybrid_2017_pt.dbc start
CM_ "toyota_rav4_hybrid_2017_pt.dbc start";
CM_ "toyota_rav4_hybrid_2017_pt.dbc starts
CM_ "toyota_rav4_hybrid_2017_pt.dbc start";
CM_ "toyota_rav4_hybrid_2017_pt.dbc starts
CM_ "toyota_rav4_hybrid_2017_pt.dbc start";
CM_ "toyota_rav4_hybrid_2017_pt.dbc starts
CM_ "toyota_rav4_hybrid_2017_pt.dbc starts";
CM_ "toyota_rav4_hybrid_2017_pt.dbc starts
CM_ "toyota_rav4_hybrid_2017_pt.dbc starts ";
CM_ "toyota_rav4_hybrid_2017_pt.dbc starts h
CM_ "toyota_rav4_hybrid_2017_pt.dbc star";
CM_ "toyota_rav4_hybrid_2017_pt.dbc start
CM_ "toyota_rav4_hybrid_2017_pt.dbc start";
CM_ "toyota_rav4_hybrid_2017_pt.dbc starts
CM_ "toyota_rav4_hybrid_2017_pt.dbc star";
CM_ "toyota_rav4_hybrid_2017_pt.dbc start
CM_ "toyota_rav4_hybrid_2017_pt.dbc start";
CM_ "toyota_rav4_hybrid_2017_pt.dbc starts
CM_ "toyota_rav4_hybrid_2017_pt.dbc start";
CM_ "toyota_rav4_hybrid_2017_pt.dbc starts
CM_ "toyota_rav4_hybrid_2017_pt.dbc start";
CM_ "toyota_rav4_hybrid_2017_pt.dbc starts
CM_ "toyota_rav4_hybrid_2017_pt.dbc starts";
CM_ "toyota_rav4_hybrid_2017_pt.dbc starts
CM_ "toyota_rav4_hybrid_2017_pt.dbc starts ";
CM_ "toyota_rav4_hybrid_2017_pt.dbc starts h
CM_ "toyota_rav4_hybrid_2017_pt.dbc start";
CM_ "toyota_rav4_hybrid_2017_pt.dbc starts
CM_ "toyota_rav4_hybrid_2017_pt.dbc start";
CM_ "toyota_rav4_hybrid_2017_pt.dbc starts
CM_ "toyota_rav4_hybrid_2017_pt.dbc starts";
CM_ "toyota_rav4_hybrid_2017_pt.dbc starts
CM_ "toyota_rav4_hybrid_2017_pt.dbc starts ";
CM_ "toyota_rav4_hybrid_2017_pt.dbc starts h
CM_ "toyota_rav4_hybrid_2017_pt.dbc starts";
CM_ "toyota_rav4_hybrid_2017_pt.dbc starts
CM_ "toyota_rav4_hybrid_2017_pt.dbc starts ";
CM_ "toyota_rav4_hybrid_2017_pt.dbc starts h
CM_ "toyota_rav4_hybrid_2017_pt.dbc starts ";
CM_ "toyota_rav4_hybrid_2017_pt.dbc starts h
CM_ "toyota_rav4_hybrid_2017_pt.dbc starts h";
CM_ "toyota_rav4_hybrid_2017_pt.dbc starts he
CM_ "toyota_rav4_hybrid_2017_pt.dbc sta";
CM_ "toyota_rav4_hybrid_2017_pt.dbc star
CM_ "toyota_rav4_hybrid_2017_pt.dbc star";
CM_ "toyota_rav4_hybrid_2017_pt.dbc start
CM_ "toyota_rav4_hybrid_2017_pt.dbc star";
CM_ "toyota_rav4_hybrid_2017_pt.dbc start
CM_ "toyota_rav4_hybrid_2017_pt.dbc start";
CM_ "toyota_rav4_hybrid_2017_pt.dbc starts
CM_ "toyota_rav4_hybrid_2017_pt.dbc sta";
CM_ "toyota_rav4_hybrid_2017_pt.dbc star
CM_ "toyota_rav4_hybrid_2017_pt.dbc star";
CM_ "toyota_rav4_hybrid_2017_pt.dbc start
CM_ "toyota_rav4_hybrid_2017_pt.dbc star";
CM_ "toyota_rav4_hybrid_2017_pt.dbc start
CM_ "toyota_rav4_hybrid_2017_pt.dbc start";
CM_ "toyota_rav4_hybrid_2017_pt.dbc starts
CM_ "toyota_rav4_hybrid_2017_pt.dbc star";
CM_ "toyota_rav4_hybrid_2017_pt.dbc start
CM_ "toyota_rav4_hybrid_2017_pt.dbc start";
CM_ "toyota_rav4_hybrid_2017_pt.dbc starts
CM_ "toyota_rav4_hybrid_2017_pt.dbc star";
CM_ "toyota_rav4_hybrid_2017_pt.dbc start
CM_ "toyota_rav4_hybrid_2017_pt.dbc start";
CM_ "toyota_rav4_hybrid_2017_pt.dbc starts
CM_ "toyota_rav4_hybrid_2017_pt.dbc start";
CM_ "toyota_rav4_hybrid_2017_pt.dbc starts
CM_ "toyota_rav4_hybrid_2017_pt.dbc start";
CM_ "toyota_rav4_hybrid_2017_pt.dbc starts
CM_ "toyota_rav4_hybrid_2017_pt.dbc starts";
CM_ "toyota_rav4_hybrid_2017_pt.dbc starts
CM_ "toyota_rav4_hybrid_2017_pt.dbc starts ";
CM_ "toyota_rav4_hybrid_2017_pt.dbc starts h
CM_ "toyota_rav4_hybrid_2017_pt.dbc star";
CM_ "toyota_rav4_hybrid_2017_pt.dbc start
CM_ "toyota_rav4_hybrid_2017_pt.dbc start";
CM_ "toyota_rav4_hybrid_2017_pt.dbc starts
CM_ "toyota_rav4_hybrid_2017_pt.dbc star";
CM_ "toyota_rav4_hybrid_2017_pt.dbc start
CM_ "toyota_rav4_hybrid_2017_pt.dbc start";
CM_ "toyota_rav4_hybrid_2017_pt.dbc starts
CM_ "toyota_rav4_hybrid_2017_pt.dbc start";
CM_ "toyota_rav4_hybrid_2017_pt.dbc starts
CM_ "toyota_rav4_hybrid_2017_pt.dbc start";
CM_ "toyota_rav4_hybrid_2017_pt.dbc starts
CM_ "toyota_rav4_hybrid_2017_pt.dbc starts";
CM_ "toyota_rav4_hybrid_2017_pt.dbc starts
CM_ "toyota_rav4_hybrid_2017_pt.dbc starts ";
CM_ "toyota_rav4_hybrid_2017_pt.dbc starts h
CM_ "toyota_rav4_hybrid_2017_pt.dbc start";
CM_ "toyota_rav4_hybrid_2017_pt.dbc starts
CM_ "toyota_rav4_hybrid_2017_pt.dbc start";
CM_ "toyota_rav4_hybrid_2017_pt.dbc starts
CM_ "toyota_rav4_hybrid_2017_pt.dbc starts";
CM_ "toyota_rav4_hybrid_2017_pt.dbc starts
CM_ "toyota_rav4_hybrid_2017_pt.dbc starts ";
CM_ "toyota_rav4_hybrid_2017_pt.dbc starts h
CM_ "toyota_rav4_hybrid_2017_pt.dbc starts";
CM_ "toyota_rav4_hybrid_2017_pt.dbc starts
CM_ "toyota_rav4_hybrid_2017_pt.dbc starts ";
CM_ "toyota_rav4_hybrid_2017_pt.dbc starts h
CM_ "toyota_rav4_hybrid_2017_pt.dbc starts ";
CM_ "toyota_rav4_hybrid_2017_pt.dbc starts h
CM_ "toyota_rav4_hybrid_2017_pt.dbc starts h";
CM_ "toyota_rav4_hybrid_2017_pt.dbc starts he
CM_ "toyota_rav4_hybrid_2017_pt.dbc star";
CM_ "toyota_rav4_hybrid_2017_pt.dbc start
CM_ "toyota_rav4_hybrid_2017_pt.dbc start";
CM_ "toyota_rav4_hybrid_2017_pt.dbc starts
CM_ "toyota_rav4_hybrid_2017_pt.dbc star";
CM_ "toyota_rav4_hybrid_2017_pt.dbc start
CM_ "toyota_rav4_hybrid_2017_pt.dbc start";
CM_ "toyota_rav4_hybrid_2017_pt.dbc starts
CM_ "toyota_rav4_hybrid_2017_pt.dbc start";
CM_ "toyota_rav4_hybrid_2017_pt.dbc starts
CM_ "toyota_rav4_hybrid_2017_pt.dbc start";
CM_ "toyota_rav4_hybrid_2017_pt.dbc starts
CM_ "toyota_rav4_hybrid_2017_pt.dbc starts";
CM_ "toyota_rav4_hybrid_2017_pt.dbc starts
CM_ "toyota_rav4_hybrid_2017_pt.dbc starts ";
CM_ "toyota_rav4_hybrid_2017_pt.dbc starts h
CM_ "toyota_rav4_hybrid_2017_pt.dbc start";
CM_ "toyota_rav4_hybrid_2017_pt.dbc starts
CM_ "toyota_rav4_hybrid_2017_pt.dbc start";
CM_ "toyota_rav4_hybrid_2017_pt.dbc starts
CM_ "toyota_rav4_hybrid_2017_pt.dbc starts";
CM_ "toyota_rav4_hybrid_2017_pt.dbc starts
CM_ "toyota_rav4_hybrid_2017_pt.dbc starts ";
CM_ "toyota_rav4_hybrid_2017_pt.dbc starts h
CM_ "toyota_rav4_hybrid_2017_pt.dbc starts";
CM_ "toyota_rav4_hybrid_2017_pt.dbc starts
CM_ "toyota_rav4_hybrid_2017_pt.dbc starts ";
CM_ "toyota_rav4_hybrid_2017_pt.dbc starts h
CM_ "toyota_rav4_hybrid_2017_pt.dbc starts ";
CM_ "toyota_rav4_hybrid_2017_pt.dbc starts h
CM_ "toyota_rav4_hybrid_2017_pt.dbc starts h";
CM_ "toyota_rav4_hybrid_2017_pt.dbc starts he
CM_ "toyota_rav4_hybrid_2017_pt.dbc start";
CM_ "toyota_rav4_hybrid_2017_pt.dbc starts
CM_ "toyota_rav4_hybrid_2017_pt.dbc start";
CM_ "toyota_rav4_hybrid_2017_pt.dbc starts
CM_ "toyota_rav4_hybrid_2017_pt.dbc starts";
CM_ "toyota_rav4_hybrid_2017_pt.dbc starts
CM_ "toyota_rav4_hybrid_2017_pt.dbc starts ";
CM_ "toyota_rav4_hybrid_2017_pt.dbc starts h
CM_ "toyota_rav4_hybrid_2017_pt.dbc starts";
CM_ "toyota_rav4_hybrid_2017_pt.dbc starts
CM_ "toyota_rav4_hybrid_2017_pt.dbc starts ";
CM_ "toyota_rav4_hybrid_2017_pt.dbc starts h
CM_ "toyota_rav4_hybrid_2017_pt.dbc starts ";
CM_ "toyota_rav4_hybrid_2017_pt.dbc starts h
CM_ "toyota_rav4_hybrid_2017_pt.dbc starts h";
CM_ "toyota_rav4_hybrid_2017_pt.dbc starts he
CM_ "toyota_rav4_hybrid_2017_pt.dbc starts";
CM_ "toyota_rav4_hybrid_2017_pt.dbc starts
CM_ "toyota_rav4_hybrid_2017_pt.dbc starts ";
CM_ "toyota_rav4_hybrid_2017_pt.dbc starts h
CM_ "toyota_rav4_hybrid_2017_pt.dbc starts ";
CM_ "toyota_rav4_hybrid_2017_pt.dbc starts h
CM_ "toyota_rav4_hybrid_2017_pt.dbc starts h";
CM_ "toyota_rav4_hybrid_2017_pt.dbc starts he
CM_ "toyota_rav4_hybrid_2017_pt.dbc starts ";
CM_ "toyota_rav4_hybrid_2017_pt.dbc starts h
CM_ "toyota_rav4_hybrid_2017_pt.dbc starts h";
CM_ "toyota_rav4_hybrid_2017_pt.dbc starts he
CM_ "toyota_rav4_hybrid_2017_pt.dbc starts h";
CM_ "toyota_rav4_hybrid_2017_pt.dbc starts he
CM_ "toyota_rav4_hybrid_2017_pt.dbc starts he";
CM_ "toyota_rav4_hybrid_2017_pt.dbc starts her
CM_ "toyota_rav4_hybrid_2017_pt.dbc sta";
CM_ "toyota_rav4_hybrid_2017_pt.dbc star
CM_ "toyota_rav4_hybrid_2017_pt.dbc star";
CM_ "toyota_rav4_hybrid_2017_pt.dbc start
CM_ "toyota_rav4_hybrid_2017_pt.dbc star";
CM_ "toyota_rav4_hybrid_2017_pt.dbc start
CM_ "toyota_rav4_hybrid_2017_pt.dbc start";
CM_ "toyota_rav4_hybrid_2017_pt.dbc starts
CM_ "toyota_rav4_hybrid_2017_pt.dbc sta";
CM_ "toyota_rav4_hybrid_2017_pt.dbc star
CM_ "toyota_rav4_hybrid_2017_pt.dbc star";
CM_ "toyota_rav4_hybrid_2017_pt.dbc start
CM_ "toyota_rav4_hybrid_2017_pt.dbc star";
CM_ "toyota_rav4_hybrid_2017_pt.dbc start
CM_ "toyota_rav4_hybrid_2017_pt.dbc start";
CM_ "toyota_rav4_hybrid_2017_pt.dbc starts
CM_ "toyota_rav4_hybrid_2017_pt.dbc star";
CM_ "toyota_rav4_hybrid_2017_pt.dbc start
CM_ "toyota_rav4_hybrid_2017_pt.dbc start";
CM_ "toyota_rav4_hybrid_2017_pt.dbc starts
CM_ "toyota_rav4_hybrid_2017_pt.dbc star";
CM_ "toyota_rav4_hybrid_2017_pt.dbc start
CM_ "toyota_rav4_hybrid_2017_pt.dbc start";
CM_ "toyota_rav4_hybrid_2017_pt.dbc starts
CM_ "toyota_rav4_hybrid_2017_pt.dbc start";
CM_ "toyota_rav4_hybrid_2017_pt.dbc starts
CM_ "toyota_rav4_hybrid_2017_pt.dbc start";
CM_ "toyota_rav4_hybrid_2017_pt.dbc starts
CM_ "toyota_rav4_hybrid_2017_pt.dbc starts";
CM_ "toyota_rav4_hybrid_2017_pt.dbc starts
CM_ "toyota_rav4_hybrid_2017_pt.dbc starts ";
CM_ "toyota_rav4_hybrid_2017_pt.dbc starts h
CM_ "toyota_rav4_hybrid_2017_pt.dbc star";
CM_ "toyota_rav4_hybrid_2017_pt.dbc start
CM_ "toyota_rav4_hybrid_2017_pt.dbc start";
CM_ "toyota_rav4_hybrid_2017_pt.dbc starts
CM_ "toyota_rav4_hybrid_2017_pt.dbc star";
CM_ "toyota_rav4_hybrid_2017_pt.dbc start
CM_ "toyota_rav4_hybrid_2017_pt.dbc start";
CM_ "toyota_rav4_hybrid_2017_pt.dbc starts
CM_ "toyota_rav4_hybrid_2017_pt.dbc start";
CM_ "toyota_rav4_hybrid_2017_pt.dbc starts
CM_ "toyota_rav4_hybrid_2017_pt.dbc start";
CM_ "toyota_rav4_hybrid_2017_pt.dbc starts
CM_ "toyota_rav4_hybrid_2017_pt.dbc starts";
CM_ "toyota_rav4_hybrid_2017_pt.dbc starts
CM_ "toyota_rav4_hybrid_2017_pt.dbc starts ";
CM_ "toyota_rav4_hybrid_2017_pt.dbc starts h
CM_ "toyota_rav4_hybrid_2017_pt.dbc start";
CM_ "toyota_rav4_hybrid_2017_pt.dbc starts
CM_ "toyota_rav4_hybrid_2017_pt.dbc start";
CM_ "toyota_rav4_hybrid_2017_pt.dbc starts
CM_ "toyota_rav4_hybrid_2017_pt.dbc starts";
CM_ "toyota_rav4_hybrid_2017_pt.dbc starts
CM_ "toyota_rav4_hybrid_2017_pt.dbc starts ";
CM_ "toyota_rav4_hybrid_2017_pt.dbc starts h
CM_ "toyota_rav4_hybrid_2017_pt.dbc starts";
CM_ "toyota_rav4_hybrid_2017_pt.dbc starts
CM_ "toyota_rav4_hybrid_2017_pt.dbc starts ";
CM_ "toyota_rav4_hybrid_2017_pt.dbc starts h
CM_ "toyota_rav4_hybrid_2017_pt.dbc starts ";
CM_ "toyota_rav4_hybrid_2017_pt.dbc starts h
CM_ "toyota_rav4_hybrid_2017_pt.dbc starts h";
CM_ "toyota_rav4_hybrid_2017_pt.dbc starts he
CM_ "toyota_rav4_hybrid_2017_pt.dbc star";
CM_ "toyota_rav4_hybrid_2017_pt.dbc start
CM_ "toyota_rav4_hybrid_2017_pt.dbc start";
CM_ "toyota_rav4_hybrid_2017_pt.dbc starts
CM_ "toyota_rav4_hybrid_2017_pt.dbc star";
CM_ "toyota_rav4_hybrid_2017_pt.dbc start
CM_ "toyota_rav4_hybrid_2017_pt.dbc start";
CM_ "toyota_rav4_hybrid_2017_pt.dbc starts
CM_ "toyota_rav4_hybrid_2017_pt.dbc start";
CM_ "toyota_rav4_hybrid_2017_pt.dbc starts
CM_ "toyota_rav4_hybrid_2017_pt.dbc start";
CM_ "toyota_rav4_hybrid_2017_pt.dbc starts
CM_ "toyota_rav4_hybrid_2017_pt.dbc starts";
CM_ "toyota_rav4_hybrid_2017_pt.dbc starts
CM_ "toyota_rav4_hybrid_2017_pt.dbc starts ";
CM_ "toyota_rav4_hybrid_2017_pt.dbc starts h
CM_ "toyota_rav4_hybrid_2017_pt.dbc start";
CM_ "toyota_rav4_hybrid_2017_pt.dbc starts
CM_ "toyota_rav4_hybrid_2017_pt.dbc start";
CM_ "toyota_rav4_hybrid_2017_pt.dbc starts
CM_ "toyota_rav4_hybrid_2017_pt.dbc starts";
CM_ "toyota_rav4_hybrid_2017_pt.dbc starts
CM_ "toyota_rav4_hybrid_2017_pt.dbc starts ";
CM_ "toyota_rav4_hybrid_2017_pt.dbc starts h
CM_ "toyota_rav4_hybrid_2017_pt.dbc starts";
CM_ "toyota_rav4_hybrid_2017_pt.dbc starts
CM_ "toyota_rav4_hybrid_2017_pt.dbc starts ";
CM_ "toyota_rav4_hybrid_2017_pt.dbc starts h
CM_ "toyota_rav4_hybrid_2017_pt.dbc starts ";
CM_ "toyota_rav4_hybrid_2017_pt.dbc starts h
CM_ "toyota_rav4_hybrid_2017_pt.dbc starts h";
CM_ "toyota_rav4_hybrid_2017_pt.dbc starts he
CM_ "toyota_rav4_hybrid_2017_pt.dbc start";
CM_ "toyota_rav4_hybrid_2017_pt.dbc starts
CM_ "toyota_rav4_hybrid_2017_pt.dbc start";
CM_ "toyota_rav4_hybrid_2017_pt.dbc starts
CM_ "toyota_rav4_hybrid_2017_pt.dbc starts";
CM_ "toyota_rav4_hybrid_2017_pt.dbc starts
CM_ "toyota_rav4_hybrid_2017_pt.dbc starts ";
CM_ "toyota_rav4_hybrid_2017_pt.dbc starts h
CM_ "toyota_rav4_hybrid_2017_pt.dbc starts";
CM_ "toyota_rav4_hybrid_2017_pt.dbc starts
CM_ "toyota_rav4_hybrid_2017_pt.dbc starts ";
CM_ "toyota_rav4_hybrid_2017_pt.dbc starts h
CM_ "toyota_rav4_hybrid_2017_pt.dbc starts ";
CM_ "toyota_rav4_hybrid_2017_pt.dbc starts h
CM_ "toyota_rav4_hybrid_2017_pt.dbc starts h";
CM_ "toyota_rav4_hybrid_2017_pt.dbc starts he
CM_ "toyota_rav4_hybrid_2017_pt.dbc starts";
CM_ "toyota_rav4_hybrid_2017_pt.dbc starts
CM_ "toyota_rav4_hybrid_2017_pt.dbc starts ";
CM_ "toyota_rav4_hybrid_2017_pt.dbc starts h
CM_ "toyota_rav4_hybrid_2017_pt.dbc starts ";
CM_ "toyota_rav4_hybrid_2017_pt.dbc starts h
CM_ "toyota_rav4_hybrid_2017_pt.dbc starts h";
CM_ "toyota_rav4_hybrid_2017_pt.dbc starts he
CM_ "toyota_rav4_hybrid_2017_pt.dbc starts ";
CM_ "toyota_rav4_hybrid_2017_pt.dbc starts h
CM_ "toyota_rav4_hybrid_2017_pt.dbc starts h";
CM_ "toyota_rav4_hybrid_2017_pt.dbc starts he
CM_ "toyota_rav4_hybrid_2017_pt.dbc starts h";
CM_ "toyota_rav4_hybrid_2017_pt.dbc starts he
CM_ "toyota_rav4_hybrid_2017_pt.dbc starts he";
CM_ "toyota_rav4_hybrid_2017_pt.dbc starts her
CM_ "toyota_rav4_hybrid_2017_pt.dbc star";
CM_ "toyota_rav4_hybrid_2017_pt.dbc start
CM_ "toyota_rav4_hybrid_2017_pt.dbc start";
CM_ "toyota_rav4_hybrid_2017_pt.dbc starts
CM_ "toyota_rav4_hybrid_2017_pt.dbc star";
CM_ "toyota_rav4_hybrid_2017_pt.dbc start
CM_ "toyota_rav4_hybrid_2017_pt.dbc start";
CM_ "toyota_rav4_hybrid_2017_pt.dbc starts
CM_ "toyota_rav4_hybrid_2017_pt.dbc start";
CM_ "toyota_rav4_hybrid_2017_pt.dbc starts
CM_ "toyota_rav4_hybrid_2017_pt.dbc start";
CM_ "toyota_rav4_hybrid_2017_pt.dbc starts
CM_ "toyota_rav4_hybrid_2017_pt.dbc starts";
CM_ "toyota_rav4_hybrid_2017_pt.dbc starts
CM_ "toyota_rav4_hybrid_2017_pt.dbc starts ";
CM_ "toyota_rav4_hybrid_2017_pt.dbc starts h
CM_ "toyota_rav4_hybrid_2017_pt.dbc start";
CM_ "toyota_rav4_hybrid_2017_pt.dbc starts
CM_ "toyota_rav4_hybrid_2017_pt.dbc start";
CM_ "toyota_rav4_hybrid_2017_pt.dbc starts
CM_ "toyota_rav4_hybrid_2017_pt.dbc starts";
CM_ "toyota_rav4_hybrid_2017_pt.dbc starts
CM_ "toyota_rav4_hybrid_2017_pt.dbc starts ";
CM_ "toyota_rav4_hybrid_2017_pt.dbc starts h
CM_ "toyota_rav4_hybrid_2017_pt.dbc starts";
CM_ "toyota_rav4_hybrid_2017_pt.dbc starts
CM_ "toyota_rav4_hybrid_2017_pt.dbc starts ";
CM_ "toyota_rav4_hybrid_2017_pt.dbc starts h
CM_ "toyota_rav4_hybrid_2017_pt.dbc starts ";
CM_ "toyota_rav4_hybrid_2017_pt.dbc starts h
CM_ "toyota_rav4_hybrid_2017_pt.dbc starts h";
CM_ "toyota_rav4_hybrid_2017_pt.dbc starts he
CM_ "toyota_rav4_hybrid_2017_pt.dbc start";
CM_ "toyota_rav4_hybrid_2017_pt.dbc starts
CM_ "toyota_rav4_hybrid_2017_pt.dbc start";
CM_ "toyota_rav4_hybrid_2017_pt.dbc starts
CM_ "toyota_rav4_hybrid_2017_pt.dbc starts";
CM_ "toyota_rav4_hybrid_2017_pt.dbc starts
CM_ "toyota_rav4_hybrid_2017_pt.dbc starts ";
CM_ "toyota_rav4_hybrid_2017_pt.dbc starts h
CM_ "toyota_rav4_hybrid_2017_pt.dbc starts";
CM_ "toyota_rav4_hybrid_2017_pt.dbc starts
CM_ "toyota_rav4_hybrid_2017_pt.dbc starts ";
CM_ "toyota_rav4_hybrid_2017_pt.dbc starts h
CM_ "toyota_rav4_hybrid_2017_pt.dbc starts ";
CM_ "toyota_rav4_hybrid_2017_pt.dbc starts h
CM_ "toyota_rav4_hybrid_2017_pt.dbc starts h";
CM_ "toyota_rav4_hybrid_2017_pt.dbc starts he
CM_ "toyota_rav4_hybrid_2017_pt.dbc starts";
CM_ "toyota_rav4_hybrid_2017_pt.dbc starts
CM_ "toyota_rav4_hybrid_2017_pt.dbc starts ";
CM_ "toyota_rav4_hybrid_2017_pt.dbc starts h
CM_ "toyota_rav4_hybrid_2017_pt.dbc starts ";
CM_ "toyota_rav4_hybrid_2017_pt.dbc starts h
CM_ "toyota_rav4_hybrid_2017_pt.dbc starts h";
CM_ "toyota_rav4_hybrid_2017_pt.dbc starts he
CM_ "toyota_rav4_hybrid_2017_pt.dbc starts ";
CM_ "toyota_rav4_hybrid_2017_pt.dbc starts h
CM_ "toyota_rav4_hybrid_2017_pt.dbc starts h";
CM_ "toyota_rav4_hybrid_2017_pt.dbc starts he
CM_ "toyota_rav4_hybrid_2017_pt.dbc starts h";
CM_ "toyota_rav4_hybrid_2017_pt.dbc starts he
CM_ "toyota_rav4_hybrid_2017_pt.dbc starts he";
CM_ "toyota_rav4_hybrid_2017_pt.dbc starts her
CM_ "toyota_rav4_hybrid_2017_pt.dbc start";
CM_ "toyota_rav4_hybrid_2017_pt.dbc starts
CM_ "toyota_rav4_hybrid_2017_pt.dbc start";
CM_ "toyota_rav4_hybrid_2017_pt.dbc starts
CM_ "toyota_rav4_hybrid_2017_pt.dbc starts";
CM_ "toyota_rav4_hybrid_2017_pt.dbc starts
CM_ "toyota_rav4_hybrid_2017_pt.dbc starts ";
CM_ "toyota_rav4_hybrid_2017_pt.dbc starts h
CM_ "toyota_rav4_hybrid_2017_pt.dbc starts";
CM_ "toyota_rav4_hybrid_2017_pt.dbc starts
CM_ "toyota_rav4_hybrid_2017_pt.dbc starts ";
CM_ "toyota_rav4_hybrid_2017_pt.dbc starts h
CM_ "toyota_rav4_hybrid_2017_pt.dbc starts ";
CM_ "toyota_rav4_hybrid_2017_pt.dbc starts h
CM_ "toyota_rav4_hybrid_2017_pt.dbc starts h";
CM_ "toyota_rav4_hybrid_2017_pt.dbc starts he
CM_ "toyota_rav4_hybrid_2017_pt.dbc starts";
CM_ "toyota_rav4_hybrid_2017_pt.dbc starts
CM_ "toyota_rav4_hybrid_2017_pt.dbc starts ";
CM_ "toyota_rav4_hybrid_2017_pt.dbc starts h
CM_ "toyota_rav4_hybrid_2017_pt.dbc starts ";
CM_ "toyota_rav4_hybrid_2017_pt.dbc starts h
CM_ "toyota_rav4_hybrid_2017_pt.dbc starts h";
CM_ "toyota_rav4_hybrid_2017_pt.dbc starts he
CM_ "toyota_rav4_hybrid_2017_pt.dbc starts ";
CM_ "toyota_rav4_hybrid_2017_pt.dbc starts h
CM_ "toyota_rav4_hybrid_2017_pt.dbc starts h";
CM_ "toyota_rav4_hybrid_2017_pt.dbc starts he
CM_ "toyota_rav4_hybrid_2017_pt.dbc starts h";
CM_ "toyota_rav4_hybrid_2017_pt.dbc starts he
CM_ "toyota_rav4_hybrid_2017_pt.dbc starts he";
CM_ "toyota_rav4_hybrid_2017_pt.dbc starts her
CM_ "toyota_rav4_hybrid_2017_pt.dbc starts";
CM_ "toyota_rav4_hybrid_2017_pt.dbc starts
CM_ "toyota_rav4_hybrid_2017_pt.dbc starts ";
CM_ "toyota_rav4_hybrid_2017_pt.dbc starts h
CM_ "toyota_rav4_hybrid_2017_pt.dbc starts ";
CM_ "toyota_rav4_hybrid_2017_pt.dbc starts h
CM_ "toyota_rav4_hybrid_2017_pt.dbc starts h";
CM_ "toyota_rav4_hybrid_2017_pt.dbc starts he
CM_ "toyota_rav4_hybrid_2017_pt.dbc starts ";
CM_ "toyota_rav4_hybrid_2017_pt.dbc starts h
CM_ "toyota_rav4_hybrid_2017_pt.dbc starts h";
CM_ "toyota_rav4_hybrid_2017_pt.dbc starts he
CM_ "toyota_rav4_hybrid_2017_pt.dbc starts h";
CM_ "toyota_rav4_hybrid_2017_pt.dbc starts he
CM_ "toyota_rav4_hybrid_2017_pt.dbc starts he";
CM_ "toyota_rav4_hybrid_2017_pt.dbc starts her
CM_ "toyota_rav4_hybrid_2017_pt.dbc starts ";
CM_ "toyota_rav4_hybrid_2017_pt.dbc starts h
CM_ "toyota_rav4_hybrid_2017_pt.dbc starts h";
CM_ "toyota_rav4_hybrid_2017_pt.dbc starts he
CM_ "toyota_rav4_hybrid_2017_pt.dbc starts h";
CM_ "toyota_rav4_hybrid_2017_pt.dbc starts he
CM_ "toyota_rav4_hybrid_2017_pt.dbc starts he";
CM_ "toyota_rav4_hybrid_2017_pt.dbc starts her
CM_ "toyota_rav4_hybrid_2017_pt.dbc starts h";
CM_ "toyota_rav4_hybrid_2017_pt.dbc starts he
CM_ "toyota_rav4_hybrid_2017_pt.dbc starts he";
CM_ "toyota_rav4_hybrid_2017_pt.dbc starts her
CM_ "toyota_rav4_hybrid_2017_pt.dbc starts he";
CM_ "toyota_rav4_hybrid_2017_pt.dbc starts her
CM_ "toyota_rav4_hybrid_2017_pt.dbc starts her";
CM_ "toyota_rav4_hybrid_2017_pt.dbc starts here
CM_ "toyota_rav4_hybrid_2017_pt.dbc s";
CM_ "toyota_rav4_hybrid_2017_pt.dbc st
CM_ "toyota_rav4_hybrid_2017_pt.dbc st";
CM_ "toyota_rav4_hybrid_2017_pt.dbc sta
CM_ "toyota_rav4_hybrid_2017_pt.dbc st";
CM_ "toyota_rav4_hybrid_2017_pt.dbc sta
CM_ "toyota_rav4_hybrid_2017_pt.dbc sta";
CM_ "toyota_rav4_hybrid_2017_pt.dbc star
CM_ "toyota_rav4_hybrid_2017_pt.dbc st";
CM_ "toyota_rav4_hybrid_2017_pt.dbc sta
CM_ "toyota_rav4_hybrid_2017_pt.dbc sta";
CM_ "toyota_rav4_hybrid_2017_pt.dbc star
CM_ "toyota_rav4_hybrid_2017_pt.dbc sta";
CM_ "toyota_rav4_hybrid_2017_pt.dbc star
CM_ "toyota_rav4_hybrid_2017_pt.dbc star";
CM_ "toyota_rav4_hybrid_2017_pt.dbc start
CM_ "toyota_rav4_hybrid_2017_pt.dbc st";
CM_ "toyota_rav4_hybrid_2017_pt.dbc sta
CM_ "toyota_rav4_hybrid_2017_pt.dbc sta";
CM_ "toyota_rav4_hybrid_2017_pt.dbc star
CM_ "toyota_rav4_hybrid_2017_pt.dbc sta";
CM_ "toyota_rav4_hybrid_2017_pt.dbc star
CM_ "toyota_rav4_hybrid_2017_pt.dbc star";
CM_ "toyota_rav4_hybrid_2017_pt.dbc start
CM_ "toyota_rav4_hybrid_2017_pt.dbc sta";
CM_ "toyota_rav4_hybrid_2017_pt.dbc star
CM_ "toyota_rav4_hybrid_2017_pt.dbc star";
CM_ "toyota_rav4_hybrid_2017_pt.dbc start
CM_ "toyota_rav4_hybrid_2017_pt.dbc star";
CM_ "toyota_rav4_hybrid_2017_pt.dbc start
CM_ "toyota_rav4_hybrid_2017_pt.dbc start";
CM_ "toyota_rav4_hybrid_2017_pt.dbc starts
CM_ "toyota_rav4_hybrid_2017_pt.dbc s";
CM_ "toyota_rav4_hybrid_2017_pt.dbc st
CM_ "toyota_rav4_hybrid_2017_pt.dbc st";
CM_ "toyota_rav4_hybrid_2017_pt.dbc sta
CM_ "toyota_rav4_hybrid_2017_pt.dbc st";
CM_ "toyota_rav4_hybrid_2017_pt.dbc sta
CM_ "toyota_rav4_hybrid_2017_pt.dbc sta";
CM_ "toyota_rav4_hybrid_2017_pt.dbc star
CM_ "toyota_rav4_hybrid_2017_pt.dbc st";
CM_ "toyota_rav4_hybrid_2017_pt.dbc sta
CM_ "toyota_rav4_hybrid_2017_pt.dbc sta";
CM_ "toyota_rav4_hybrid_2017_pt.dbc star
CM_ "toyota_rav4_hybrid_2017_pt.dbc sta";
CM_ "toyota_rav4_hybrid_2017_pt.dbc star
CM_ "toyota_rav4_hybrid_2017_pt.dbc star";
CM_ "toyota_rav4_hybrid_2017_pt.dbc start
CM_ "toyota_rav4_hybrid_2017_pt.dbc st";
CM_ "toyota_rav4_hybrid_2017_pt.dbc sta
CM_ "toyota_rav4_hybrid_2017_pt.dbc sta";
CM_ "toyota_rav4_hybrid_2017_pt.dbc star
CM_ "toyota_rav4_hybrid_2017_pt.dbc sta";
CM_ "toyota_rav4_hybrid_2017_pt.dbc star
CM_ "toyota_rav4_hybrid_2017_pt.dbc star";
CM_ "toyota_rav4_hybrid_2017_pt.dbc start
CM_ "toyota_rav4_hybrid_2017_pt.dbc sta";
CM_ "toyota_rav4_hybrid_2017_pt.dbc star
CM_ "toyota_rav4_hybrid_2017_pt.dbc star";
CM_ "toyota_rav4_hybrid_2017_pt.dbc start
CM_ "toyota_rav4_hybrid_2017_pt.dbc star";
CM_ "toyota_rav4_hybrid_2017_pt.dbc start
CM_ "toyota_rav4_hybrid_2017_pt.dbc start";
CM_ "toyota_rav4_hybrid_2017_pt.dbc starts
CM_ "toyota_rav4_hybrid_2017_pt.dbc st";
CM_ "toyota_rav4_hybrid_2017_pt.dbc sta
CM_ "toyota_rav4_hybrid_2017_pt.dbc sta";
CM_ "toyota_rav4_hybrid_2017_pt.dbc star
CM_ "toyota_rav4_hybrid_2017_pt.dbc sta";
CM_ "toyota_rav4_hybrid_2017_pt.dbc star
CM_ "toyota_rav4_hybrid_2017_pt.dbc star";
CM_ "toyota_rav4_hybrid_2017_pt.dbc start
CM_ "toyota_rav4_hybrid_2017_pt.dbc sta";
CM_ "toyota_rav4_hybrid_2017_pt.dbc star
CM_ "toyota_rav4_hybrid_2017_pt.dbc star";
CM_ "toyota_rav4_hybrid_2017_pt.dbc start
CM_ "toyota_rav4_hybrid_2017_pt.dbc star";
CM_ "toyota_rav4_hybrid_2017_pt.dbc start
CM_ "toyota_rav4_hybrid_2017_pt.dbc start";
CM_ "toyota_rav4_hybrid_2017_pt.dbc starts
CM_ "toyota_rav4_hybrid_2017_pt.dbc st";
CM_ "toyota_rav4_hybrid_2017_pt.dbc sta
CM_ "toyota_rav4_hybrid_2017_pt.dbc sta";
CM_ "toyota_rav4_hybrid_2017_pt.dbc star
CM_ "toyota_rav4_hybrid_2017_pt.dbc sta";
CM_ "toyota_rav4_hybrid_2017_pt.dbc star
CM_ "toyota_rav4_hybrid_2017_pt.dbc star";
CM_ "toyota_rav4_hybrid_2017_pt.dbc start
CM_ "toyota_rav4_hybrid_2017_pt.dbc sta";
CM_ "toyota_rav4_hybrid_2017_pt.dbc star
CM_ "toyota_rav4_hybrid_2017_pt.dbc star";
CM_ "toyota_rav4_hybrid_2017_pt.dbc start
CM_ "toyota_rav4_hybrid_2017_pt.dbc star";
CM_ "toyota_rav4_hybrid_2017_pt.dbc start
CM_ "toyota_rav4_hybrid_2017_pt.dbc start";
CM_ "toyota_rav4_hybrid_2017_pt.dbc starts
CM_ "toyota_rav4_hybrid_2017_pt.dbc sta";
CM_ "toyota_rav4_hybrid_2017_pt.dbc star
CM_ "toyota_rav4_hybrid_2017_pt.dbc star";
CM_ "toyota_rav4_hybrid_2017_pt.dbc start
CM_ "toyota_rav4_hybrid_2017_pt.dbc star";
CM_ "toyota_rav4_hybrid_2017_pt.dbc start
CM_ "toyota_rav4_hybrid_2017_pt.dbc start";
CM_ "toyota_rav4_hybrid_2017_pt.dbc starts
CM_ "toyota_rav4_hybrid_2017_pt.dbc sta";
CM_ "toyota_rav4_hybrid_2017_pt.dbc star
CM_ "toyota_rav4_hybrid_2017_pt.dbc star";
CM_ "toyota_rav4_hybrid_2017_pt.dbc start
CM_ "toyota_rav4_hybrid_2017_pt.dbc star";
CM_ "toyota_rav4_hybrid_2017_pt.dbc start
CM_ "toyota_rav4_hybrid_2017_pt.dbc start";
CM_ "toyota_rav4_hybrid_2017_pt.dbc starts
CM_ "toyota_rav4_hybrid_2017_pt.dbc star";
CM_ "toyota_rav4_hybrid_2017_pt.dbc start
CM_ "toyota_rav4_hybrid_2017_pt.dbc start";
CM_ "toyota_rav4_hybrid_2017_pt.dbc starts
CM_ "toyota_rav4_hybrid_2017_pt.dbc star";
CM_ "toyota_rav4_hybrid_2017_pt.dbc start
CM_ "toyota_rav4_hybrid_2017_pt.dbc start";
CM_ "toyota_rav4_hybrid_2017_pt.dbc starts
CM_ "toyota_rav4_hybrid_2017_pt.dbc start";
CM_ "toyota_rav4_hybrid_2017_pt.dbc starts
CM_ "toyota_rav4_hybrid_2017_pt.dbc start";
CM_ "toyota_rav4_hybrid_2017_pt.dbc starts
CM_ "toyota_rav4_hybrid_2017_pt.dbc starts";
CM_ "toyota_rav4_hybrid_2017_pt.dbc starts
CM_ "toyota_rav4_hybrid_2017_pt.dbc starts ";
CM_ "toyota_rav4_hybrid_2017_pt.dbc starts h
CM_ "toyota_rav4_hybrid_2017_pt.dbc st";
CM_ "toyota_rav4_hybrid_2017_pt.dbc sta
CM_ "toyota_rav4_hybrid_2017_pt.dbc sta";
CM_ "toyota_rav4_hybrid_2017_pt.dbc star
CM_ "toyota_rav4_hybrid_2017_pt.dbc sta";
CM_ "toyota_rav4_hybrid_2017_pt.dbc star
CM_ "toyota_rav4_hybrid_2017_pt.dbc star";
CM_ "toyota_rav4_hybrid_2017_pt.dbc start
CM_ "toyota_rav4_hybrid_2017_pt.dbc sta";
CM_ "toyota_rav4_hybrid_2017_pt.dbc star
CM_ "toyota_rav4_hybrid_2017_pt.dbc star";
CM_ "toyota_rav4_hybrid_2017_pt.dbc start
CM_ "toyota_rav4_hybrid_2017_pt.dbc star";
CM_ "toyota_rav4_hybrid_2017_pt.dbc start
CM_ "toyota_rav4_hybrid_2017_pt.dbc start";
CM_ "toyota_rav4_hybrid_2017_pt.dbc starts
CM_ "toyota_rav4_hybrid_2017_pt.dbc st";
CM_ "toyota_rav4_hybrid_2017_pt.dbc sta
CM_ "toyota_rav4_hybrid_2017_pt.dbc sta";
CM_ "toyota_rav4_hybrid_2017_pt.dbc star
CM_ "toyota_rav4_hybrid_2017_pt.dbc sta";
CM_ "toyota_rav4_hybrid_2017_pt.dbc star
CM_ "toyota_rav4_hybrid_2017_pt.dbc star";
CM_ "toyota_rav4_hybrid_2017_pt.dbc start
CM_ "toyota_rav4_hybrid_2017_pt.dbc sta";
CM_ "toyota_rav4_hybrid_2017_pt.dbc star
CM_ "toyota_rav4_hybrid_2017_pt.dbc star";
CM_ "toyota_rav4_hybrid_2017_pt.dbc start
CM_ "toyota_rav4_hybrid_2017_pt.dbc star";
CM_ "toyota_rav4_hybrid_2017_pt.dbc start
CM_ "toyota_rav4_hybrid_2017_pt.dbc start";
CM_ "toyota_rav4_hybrid_2017_pt.dbc starts
CM_ "toyota_rav4_hybrid_2017_pt.dbc sta";
CM_ "toyota_rav4_hybrid_2017_pt.dbc star
CM_ "toyota_rav4_hybrid_2017_pt.dbc star";
CM_ "toyota_rav4_hybrid_2017_pt.dbc start
CM_ "toyota_rav4_hybrid_2017_pt.dbc star";
CM_ "toyota_rav4_hybrid_2017_pt.dbc start
CM_ "toyota_rav4_hybrid_2017_pt.dbc start";
CM_ "toyota_rav4_hybrid_2017_pt.dbc starts
CM_ "toyota_rav4_hybrid_2017_pt.dbc sta";
CM_ "toyota_rav4_hybrid_2017_pt.dbc star
CM_ "toyota_rav4_hybrid_2017_pt.dbc star";
CM_ "toyota_rav4_hybrid_2017_pt.dbc start
CM_ "toyota_rav4_hybrid_2017_pt.dbc star";
CM_ "toyota_rav4_hybrid_2017_pt.dbc start
CM_ "toyota_rav4_hybrid_2017_pt.dbc start";
CM_ "toyota_rav4_hybrid_2017_pt.dbc starts
CM_ "toyota_rav4_hybrid_2017_pt.dbc star";
CM_ "toyota_rav4_hybrid_2017_pt.dbc start
CM_ "toyota_rav4_hybrid_2017_pt.dbc start";
CM_ "toyota_rav4_hybrid_2017_pt.dbc starts
CM_ "toyota_rav4_hybrid_2017_pt.dbc star";
CM_ "toyota_rav4_hybrid_2017_pt.dbc start
CM_ "toyota_rav4_hybrid_2017_pt.dbc start";
CM_ "toyota_rav4_hybrid_2017_pt.dbc starts
CM_ "toyota_rav4_hybrid_2017_pt.dbc start";
CM_ "toyota_rav4_hybrid_2017_pt.dbc starts
CM_ "toyota_rav4_hybrid_2017_pt.dbc start";
CM_ "toyota_rav4_hybrid_2017_pt.dbc starts
CM_ "toyota_rav4_hybrid_2017_pt.dbc starts";
CM_ "toyota_rav4_hybrid_2017_pt.dbc starts
CM_ "toyota_rav4_hybrid_2017_pt.dbc starts ";
CM_ "toyota_rav4_hybrid_2017_pt.dbc starts h
CM_ "toyota_rav4_hybrid_2017_pt.dbc sta";
CM_ "toyota_rav4_hybrid_2017_pt.dbc star
CM_ "toyota_rav4_hybrid_2017_pt.dbc star";
CM_ "toyota_rav4_hybrid_2017_pt.dbc start
CM_ "toyota_rav4_hybrid_2017_pt.dbc star";
CM_ "toyota_rav4_hybrid_2017_pt.dbc start
CM_ "toyota_rav4_hybrid_2017_pt.dbc start";
CM_ "toyota_rav4_hybrid_2017_pt.dbc starts
CM_ "toyota_rav4_hybrid_2017_pt.dbc sta";
CM_ "toyota_rav4_hybrid_2017_pt.dbc star
CM_ "toyota_rav4_hybrid_2017_pt.dbc star";
CM_ "toyota_rav4_hybrid_2017_pt.dbc start
CM_ "toyota_rav4_hybrid_2017_pt.dbc star";
CM_ "toyota_rav4_hybrid_2017_pt.dbc start
CM_ "toyota_rav4_hybrid_2017_pt.dbc start";
CM_ "toyota_rav4_hybrid_2017_pt.dbc starts
CM_ "toyota_rav4_hybrid_2017_pt.dbc star";
CM_ "toyota_rav4_hybrid_2017_pt.dbc start
CM_ "toyota_rav4_hybrid_2017_pt.dbc start";
CM_ "toyota_rav4_hybrid_2017_pt.dbc starts
CM_ "toyota_rav4_hybrid_2017_pt.dbc star";
CM_ "toyota_rav4_hybrid_2017_pt.dbc start
CM_ "toyota_rav4_hybrid_2017_pt.dbc start";
CM_ "toyota_rav4_hybrid_2017_pt.dbc starts
CM_ "toyota_rav4_hybrid_2017_pt.dbc start";
CM_ "toyota_rav4_hybrid_2017_pt.dbc starts
CM_ "toyota_rav4_hybrid_2017_pt.dbc start";
CM_ "toyota_rav4_hybrid_2017_pt.dbc starts
CM_ "toyota_rav4_hybrid_2017_pt.dbc starts";
CM_ "toyota_rav4_hybrid_2017_pt.dbc starts
CM_ "toyota_rav4_hybrid_2017_pt.dbc starts ";
CM_ "toyota_rav4_hybrid_2017_pt.dbc starts h
CM_ "toyota_rav4_hybrid_2017_pt.dbc star";
CM_ "toyota_rav4_hybrid_2017_pt.dbc start
CM_ "toyota_rav4_hybrid_2017_pt.dbc start";
CM_ "toyota_rav4_hybrid_2017_pt.dbc starts
CM_ "toyota_rav4_hybrid_2017_pt.dbc star";
CM_ "toyota_rav4_hybrid_2017_pt.dbc start
CM_ "toyota_rav4_hybrid_2017_pt.dbc start";
CM_ "toyota_rav4_hybrid_2017_pt.dbc starts
CM_ "toyota_rav4_hybrid_2017_pt.dbc start";
CM_ "toyota_rav4_hybrid_2017_pt.dbc starts
CM_ "toyota_rav4_hybrid_2017_pt.dbc start";
CM_ "toyota_rav4_hybrid_2017_pt.dbc starts
CM_ "toyota_rav4_hybrid_2017_pt.dbc starts";
CM_ "toyota_rav4_hybrid_2017_pt.dbc starts
CM_ "toyota_rav4_hybrid_2017_pt.dbc starts ";
CM_ "toyota_rav4_hybrid_2017_pt.dbc starts h
CM_ "toyota_rav4_hybrid_2017_pt.dbc start";
CM_ "toyota_rav4_hybrid_2017_pt.dbc starts
CM_ "toyota_rav4_hybrid_2017_pt.dbc start";
CM_ "toyota_rav4_hybrid_2017_pt.dbc starts
CM_ "toyota_rav4_hybrid_2017_pt.dbc starts";
CM_ "toyota_rav4_hybrid_2017_pt.dbc starts
CM_ "toyota_rav4_hybrid_2017_pt.dbc starts ";
CM_ "toyota_rav4_hybrid_2017_pt.dbc starts h
CM_ "toyota_rav4_hybrid_2017_pt.dbc starts";
CM_ "toyota_rav4_hybrid_2017_pt.dbc starts
CM_ "toyota_rav4_hybrid_2017_pt.dbc starts ";
CM_ "toyota_rav4_hybrid_2017_pt.dbc starts h
CM_ "toyota_rav4_hybrid_2017_pt.dbc starts ";
CM_ "toyota_rav4_hybrid_2017_pt.dbc starts h
CM_ "toyota_rav4_hybrid_2017_pt.dbc starts h";
CM_ "toyota_rav4_hybrid_2017_pt.dbc starts he
CM_ "toyota_rav4_hybrid_2017_pt.dbc st";
CM_ "toyota_rav4_hybrid_2017_pt.dbc sta
CM_ "toyota_rav4_hybrid_2017_pt.dbc sta";
CM_ "toyota_rav4_hybrid_2017_pt.dbc star
CM_ "toyota_rav4_hybrid_2017_pt.dbc sta";
CM_ "toyota_rav4_hybrid_2017_pt.dbc star
CM_ "toyota_rav4_hybrid_2017_pt.dbc star";
CM_ "toyota_rav4_hybrid_2017_pt.dbc start
CM_ "toyota_rav4_hybrid_2017_pt.dbc sta";
CM_ "toyota_rav4_hybrid_2017_pt.dbc star
CM_ "toyota_rav4_hybrid_2017_pt.dbc star";
CM_ "toyota_rav4_hybrid_2017_pt.dbc start
CM_ "toyota_rav4_hybrid_2017_pt.dbc star";
CM_ "toyota_rav4_hybrid_2017_pt.dbc start
CM_ "toyota_rav4_hybrid_2017_pt.dbc start";
CM_ "toyota_rav4_hybrid_2017_pt.dbc starts
CM_ "toyota_rav4_hybrid_2017_pt.dbc st";
CM_ "toyota_rav4_hybrid_2017_pt.dbc sta
CM_ "toyota_rav4_hybrid_2017_pt.dbc sta";
CM_ "toyota_rav4_hybrid_2017_pt.dbc star
CM_ "toyota_rav4_hybrid_2017_pt.dbc sta";
CM_ "toyota_rav4_hybrid_2017_pt.dbc star
CM_ "toyota_rav4_hybrid_2017_pt.dbc star";
CM_ "toyota_rav4_hybrid_2017_pt.dbc start
CM_ "toyota_rav4_hybrid_2017_pt.dbc sta";
CM_ "toyota_rav4_hybrid_2017_pt.dbc star
CM_ "toyota_rav4_hybrid_2017_pt.dbc star";
CM_ "toyota_rav4_hybrid_2017_pt.dbc start
CM_ "toyota_rav4_hybrid_2017_pt.dbc star";
CM_ "toyota_rav4_hybrid_2017_pt.dbc start
CM_ "toyota_rav4_hybrid_2017_pt.dbc start";
CM_ "toyota_rav4_hybrid_2017_pt.dbc starts
CM_ "toyota_rav4_hybrid_2017_pt.dbc sta";
CM_ "toyota_rav4_hybrid_2017_pt.dbc star
CM_ "toyota_rav4_hybrid_2017_pt.dbc star";
CM_ "toyota_rav4_hybrid_2017_pt.dbc start
CM_ "toyota_rav4_hybrid_2017_pt.dbc star";
CM_ "toyota_rav4_hybrid_2017_pt.dbc start
CM_ "toyota_rav4_hybrid_2017_pt.dbc start";
CM_ "toyota_rav4_hybrid_2017_pt.dbc starts
CM_ "toyota_rav4_hybrid_2017_pt.dbc sta";
CM_ "toyota_rav4_hybrid_2017_pt.dbc star
CM_ "toyota_rav4_hybrid_2017_pt.dbc star";
CM_ "toyota_rav4_hybrid_2017_pt.dbc start
CM_ "toyota_rav4_hybrid_2017_pt.dbc star";
CM_ "toyota_rav4_hybrid_2017_pt.dbc start
CM_ "toyota_rav4_hybrid_2017_pt.dbc start";
CM_ "toyota_rav4_hybrid_2017_pt.dbc starts
CM_ "toyota_rav4_hybrid_2017_pt.dbc star";
CM_ "toyota_rav4_hybrid_2017_pt.dbc start
CM_ "toyota_rav4_hybrid_2017_pt.dbc start";
CM_ "toyota_rav4_hybrid_2017_pt.dbc starts
CM_ "toyota_rav4_hybrid_2017_pt.dbc star";
CM_ "toyota_rav4_hybrid_2017_pt.dbc start
CM_ "toyota_rav4_hybrid_2017_pt.dbc start";
CM_ "toyota_rav4_hybrid_2017_pt.dbc starts
CM_ "toyota_rav4_hybrid_2017_pt.dbc start";
CM_ "toyota_rav4_hybrid_2017_pt.dbc starts
CM_ "toyota_rav4_hybrid_2017_pt.dbc start";
CM_ "toyota_rav4_hybrid_2017_pt.dbc starts
CM_ "toyota_rav4_hybrid_2017_pt.dbc starts";
CM_ "toyota_rav4_hybrid_2017_pt.dbc starts
CM_ "toyota_rav4_hybrid_2017_pt.dbc starts ";
CM_ "toyota_rav4_hybrid_2017_pt.dbc starts h
CM_ "toyota_rav4_hybrid_2017_pt.dbc sta";
CM_ "toyota_rav4_hybrid_2017_pt.dbc star
CM_ "toyota_rav4_hybrid_2017_pt.dbc star";
CM_ "toyota_rav4_hybrid_2017_pt.dbc start
CM_ "toyota_rav4_hybrid_2017_pt.dbc star";
CM_ "toyota_rav4_hybrid_2017_pt.dbc start
CM_ "toyota_rav4_hybrid_2017_pt.dbc start";
CM_ "toyota_rav4_hybrid_2017_pt.dbc starts
CM_ "toyota_rav4_hybrid_2017_pt.dbc sta";
CM_ "toyota_rav4_hybrid_2017_pt.dbc star
CM_ "toyota_rav4_hybrid_2017_pt.dbc star";
CM_ "toyota_rav4_hybrid_2017_pt.dbc start
CM_ "toyota_rav4_hybrid_2017_pt.dbc star";
CM_ "toyota_rav4_hybrid_2017_pt.dbc start
CM_ "toyota_rav4_hybrid_2017_pt.dbc start";
CM_ "toyota_rav4_hybrid_2017_pt.dbc starts
CM_ "toyota_rav4_hybrid_2017_pt.dbc star";
CM_ "toyota_rav4_hybrid_2017_pt.dbc start
CM_ "toyota_rav4_hybrid_2017_pt.dbc start";
CM_ "toyota_rav4_hybrid_2017_pt.dbc starts
CM_ "toyota_rav4_hybrid_2017_pt.dbc star";
CM_ "toyota_rav4_hybrid_2017_pt.dbc start
CM_ "toyota_rav4_hybrid_2017_pt.dbc start";
CM_ "toyota_rav4_hybrid_2017_pt.dbc starts
CM_ "toyota_rav4_hybrid_2017_pt.dbc start";
CM_ "toyota_rav4_hybrid_2017_pt.dbc starts
CM_ "toyota_rav4_hybrid_2017_pt.dbc start";
CM_ "toyota_rav4_hybrid_2017_pt.dbc starts
CM_ "toyota_rav4_hybrid_2017_pt.dbc starts";
CM_ "toyota_rav4_hybrid_2017_pt.dbc starts
CM_ "toyota_rav4_hybrid_2017_pt.dbc starts ";
CM_ "toyota_rav4_hybrid_2017_pt.dbc starts h
CM_ "toyota_rav4_hybrid_2017_pt.dbc star";
CM_ "toyota_rav4_hybrid_2017_pt.dbc start
CM_ "toyota_rav4_hybrid_2017_pt.dbc start";
CM_ "toyota_rav4_hybrid_2017_pt.dbc starts
CM_ "toyota_rav4_hybrid_2017_pt.dbc star";
CM_ "toyota_rav4_hybrid_2017_pt.dbc start
CM_ "toyota_rav4_hybrid_2017_pt.dbc start";
CM_ "toyota_rav4_hybrid_2017_pt.dbc starts
CM_ "toyota_rav4_hybrid_2017_pt.dbc start";
CM_ "toyota_rav4_hybrid_2017_pt.dbc starts
CM_ "toyota_rav4_hybrid_2017_pt.dbc start";
CM_ "toyota_rav4_hybrid_2017_pt.dbc starts
CM_ "toyota_rav4_hybrid_2017_pt.dbc starts";
CM_ "toyota_rav4_hybrid_2017_pt.dbc starts
CM_ "toyota_rav4_hybrid_2017_pt.dbc starts ";
CM_ "toyota_rav4_hybrid_2017_pt.dbc starts h
CM_ "toyota_rav4_hybrid_2017_pt.dbc start";
CM_ "toyota_rav4_hybrid_2017_pt.dbc starts
CM_ "toyota_rav4_hybrid_2017_pt.dbc start";
CM_ "toyota_rav4_hybrid_2017_pt.dbc starts
CM_ "toyota_rav4_hybrid_2017_pt.dbc starts";
CM_ "toyota_rav4_hybrid_2017_pt.dbc starts
CM_ "toyota_rav4_hybrid_2017_pt.dbc starts ";
CM_ "toyota_rav4_hybrid_2017_pt.dbc starts h
CM_ "toyota_rav4_hybrid_2017_pt.dbc starts";
CM_ "toyota_rav4_hybrid_2017_pt.dbc starts
CM_ "toyota_rav4_hybrid_2017_pt.dbc starts ";
CM_ "toyota_rav4_hybrid_2017_pt.dbc starts h
CM_ "toyota_rav4_hybrid_2017_pt.dbc starts ";
CM_ "toyota_rav4_hybrid_2017_pt.dbc starts h
CM_ "toyota_rav4_hybrid_2017_pt.dbc starts h";
CM_ "toyota_rav4_hybrid_2017_pt.dbc starts he
CM_ "toyota_rav4_hybrid_2017_pt.dbc sta";
CM_ "toyota_rav4_hybrid_2017_pt.dbc star
CM_ "toyota_rav4_hybrid_2017_pt.dbc star";
CM_ "toyota_rav4_hybrid_2017_pt.dbc start
CM_ "toyota_rav4_hybrid_2017_pt.dbc star";
CM_ "toyota_rav4_hybrid_2017_pt.dbc start
CM_ "toyota_rav4_hybrid_2017_pt.dbc start";
CM_ "toyota_rav4_hybrid_2017_pt.dbc starts
CM_ "toyota_rav4_hybrid_2017_pt.dbc sta";
CM_ "toyota_rav4_hybrid_2017_pt.dbc star
CM_ "toyota_rav4_hybrid_2017_pt.dbc star";
CM_ "toyota_rav4_hybrid_2017_pt.dbc start
CM_ "toyota_rav4_hybrid_2017_pt.dbc star";
CM_ "toyota_rav4_hybrid_2017_pt.dbc start
CM_ "toyota_rav4_hybrid_2017_pt.dbc start";
CM_ "toyota_rav4_hybrid_2017_pt.dbc starts
CM_ "toyota_rav4_hybrid_2017_pt.dbc star";
CM_ "toyota_rav4_hybrid_2017_pt.dbc start
CM_ "toyota_rav4_hybrid_2017_pt.dbc start";
CM_ "toyota_rav4_hybrid_2017_pt.dbc starts
CM_ "toyota_rav4_hybrid_2017_pt.dbc star";
CM_ "toyota_rav4_hybrid_2017_pt.dbc start
CM_ "toyota_rav4_hybrid_2017_pt.dbc start";
CM_ "toyota_rav4_hybrid_2017_pt.dbc starts
CM_ "toyota_rav4_hybrid_2017_pt.dbc start";
CM_ "toyota_rav4_hybrid_2017_pt.dbc starts
CM_ "toyota_rav4_hybrid_2017_pt.dbc start";
CM_ "toyota_rav4_hybrid_2017_pt.dbc starts
CM_ "toyota_rav4_hybrid_2017_pt.dbc starts";
CM_ "toyota_rav4_hybrid_2017_pt.dbc starts
CM_ "toyota_rav4_hybrid_2017_pt.dbc starts ";
CM_ "toyota_rav4_hybrid_2017_pt.dbc starts h
CM_ "toyota_rav4_hybrid_2017_pt.dbc star";
CM_ "toyota_rav4_hybrid_2017_pt.dbc start
CM_ "toyota_rav4_hybrid_2017_pt.dbc start";
CM_ "toyota_rav4_hybrid_2017_pt.dbc starts
CM_ "toyota_rav4_hybrid_2017_pt.dbc star";
CM_ "toyota_rav4_hybrid_2017_pt.dbc start
CM_ "toyota_rav4_hybrid_2017_pt.dbc start";
CM_ "toyota_rav4_hybrid_2017_pt.dbc starts
CM_ "toyota_rav4_hybrid_2017_pt.dbc start";
CM_ "toyota_rav4_hybrid_2017_pt.dbc starts
CM_ "toyota_rav4_hybrid_2017_pt.dbc start";
CM_ "toyota_rav4_hybrid_2017_pt.dbc starts
CM_ "toyota_rav4_hybrid_2017_pt.dbc starts";
CM_ "toyota_rav4_hybrid_2017_pt.dbc starts
CM_ "toyota_rav4_hybrid_2017_pt.dbc starts ";
CM_ "toyota_rav4_hybrid_2017_pt.dbc starts h
CM_ "toyota_rav4_hybrid_2017_pt.dbc start";
CM_ "toyota_rav4_hybrid_2017_pt.dbc starts
CM_ "toyota_rav4_hybrid_2017_pt.dbc start";
CM_ "toyota_rav4_hybrid_2017_pt.dbc starts
CM_ "toyota_rav4_hybrid_2017_pt.dbc starts";
CM_ "toyota_rav4_hybrid_2017_pt.dbc starts
CM_ "toyota_rav4_hybrid_2017_pt.dbc starts ";
CM_ "toyota_rav4_hybrid_2017_pt.dbc starts h
CM_ "toyota_rav4_hybrid_2017_pt.dbc starts";
CM_ "toyota_rav4_hybrid_2017_pt.dbc starts
CM_ "toyota_rav4_hybrid_2017_pt.dbc starts ";
CM_ "toyota_rav4_hybrid_2017_pt.dbc starts h
CM_ "toyota_rav4_hybrid_2017_pt.dbc starts ";
CM_ "toyota_rav4_hybrid_2017_pt.dbc starts h
CM_ "toyota_rav4_hybrid_2017_pt.dbc starts h";
CM_ "toyota_rav4_hybrid_2017_pt.dbc starts he
CM_ "toyota_rav4_hybrid_2017_pt.dbc star";
CM_ "toyota_rav4_hybrid_2017_pt.dbc start
CM_ "toyota_rav4_hybrid_2017_pt.dbc start";
CM_ "toyota_rav4_hybrid_2017_pt.dbc starts
CM_ "toyota_rav4_hybrid_2017_pt.dbc star";
CM_ "toyota_rav4_hybrid_2017_pt.dbc start
CM_ "toyota_rav4_hybrid_2017_pt.dbc start";
CM_ "toyota_rav4_hybrid_2017_pt.dbc starts
CM_ "toyota_rav4_hybrid_2017_pt.dbc start";
CM_ "toyota_rav4_hybrid_2017_pt.dbc starts
CM_ "toyota_rav4_hybrid_2017_pt.dbc start";
CM_ "toyota_rav4_hybrid_2017_pt.dbc starts
CM_ "toyota_rav4_hybrid_2017_pt.dbc starts";
CM_ "toyota_rav4_hybrid_2017_pt.dbc starts
CM_ "toyota_rav4_hybrid_2017_pt.dbc starts ";
CM_ "toyota_rav4_hybrid_2017_pt.dbc starts h
CM_ "toyota_rav4_hybrid_2017_pt.dbc start";
CM_ "toyota_rav4_hybrid_2017_pt.dbc starts
CM_ "toyota_rav4_hybrid_2017_pt.dbc start";
CM_ "toyota_rav4_hybrid_2017_pt.dbc starts
CM_ "toyota_rav4_hybrid_2017_pt.dbc starts";
CM_ "toyota_rav4_hybrid_2017_pt.dbc starts
CM_ "toyota_rav4_hybrid_2017_pt.dbc starts ";
CM_ "toyota_rav4_hybrid_2017_pt.dbc starts h
CM_ "toyota_rav4_hybrid_2017_pt.dbc starts";
CM_ "toyota_rav4_hybrid_2017_pt.dbc starts
CM_ "toyota_rav4_hybrid_2017_pt.dbc starts ";
CM_ "toyota_rav4_hybrid_2017_pt.dbc starts h
CM_ "toyota_rav4_hybrid_2017_pt.dbc starts ";
CM_ "toyota_rav4_hybrid_2017_pt.dbc starts h
CM_ "toyota_rav4_hybrid_2017_pt.dbc starts h";
CM_ "toyota_rav4_hybrid_2017_pt.dbc starts he
CM_ "toyota_rav4_hybrid_2017_pt.dbc start";
CM_ "toyota_rav4_hybrid_2017_pt.dbc starts
CM_ "toyota_rav4_hybrid_2017_pt.dbc start";
CM_ "toyota_rav4_hybrid_2017_pt.dbc starts
CM_ "toyota_rav4_hybrid_2017_pt.dbc starts";
CM_ "toyota_rav4_hybrid_2017_pt.dbc starts
CM_ "toyota_rav4_hybrid_2017_pt.dbc starts ";
CM_ "toyota_rav4_hybrid_2017_pt.dbc starts h
CM_ "toyota_rav4_hybrid_2017_pt.dbc starts";
CM_ "toyota_rav4_hybrid_2017_pt.dbc starts
CM_ "toyota_rav4_hybrid_2017_pt.dbc starts ";
CM_ "toyota_rav4_hybrid_2017_pt.dbc starts h
CM_ "toyota_rav4_hybrid_2017_pt.dbc starts ";
CM_ "toyota_rav4_hybrid_2017_pt.dbc starts h
CM_ "toyota_rav4_hybrid_2017_pt.dbc starts h";
CM_ "toyota_rav4_hybrid_2017_pt.dbc starts he
CM_ "toyota_rav4_hybrid_2017_pt.dbc starts";
CM_ "toyota_rav4_hybrid_2017_pt.dbc starts
CM_ "toyota_rav4_hybrid_2017_pt.dbc starts ";
CM_ "toyota_rav4_hybrid_2017_pt.dbc starts h
CM_ "toyota_rav4_hybrid_2017_pt.dbc starts ";
CM_ "toyota_rav4_hybrid_2017_pt.dbc starts h
CM_ "toyota_rav4_hybrid_2017_pt.dbc starts h";
CM_ "toyota_rav4_hybrid_2017_pt.dbc starts he
CM_ "toyota_rav4_hybrid_2017_pt.dbc starts ";
CM_ "toyota_rav4_hybrid_2017_pt.dbc starts h
CM_ "toyota_rav4_hybrid_2017_pt.dbc starts h";
CM_ "toyota_rav4_hybrid_2017_pt.dbc starts he
CM_ "toyota_rav4_hybrid_2017_pt.dbc starts h";
CM_ "toyota_rav4_hybrid_2017_pt.dbc starts he
CM_ "toyota_rav4_hybrid_2017_pt.dbc starts he";
CM_ "toyota_rav4_hybrid_2017_pt.dbc starts her
CM_ "toyota_rav4_hybrid_2017_pt.dbc st";
CM_ "toyota_rav4_hybrid_2017_pt.dbc sta
CM_ "toyota_rav4_hybrid_2017_pt.dbc sta";
CM_ "toyota_rav4_hybrid_2017_pt.dbc star
CM_ "toyota_rav4_hybrid_2017_pt.dbc sta";
CM_ "toyota_rav4_hybrid_2017_pt.dbc star
CM_ "toyota_rav4_hybrid_2017_pt.dbc star";
CM_ "toyota_rav4_hybrid_2017_pt.dbc start
CM_ "toyota_rav4_hybrid_2017_pt.dbc sta";
CM_ "toyota_rav4_hybrid_2017_pt.dbc star
CM_ "toyota_rav4_hybrid_2017_pt.dbc star";
CM_ "toyota_rav4_hybrid_2017_pt.dbc start
CM_ "toyota_rav4_hybrid_2017_pt.dbc star";
CM_ "toyota_rav4_hybrid_2017_pt.dbc start
CM_ "toyota_rav4_hybrid_2017_pt.dbc start";
CM_ "toyota_rav4_hybrid_2017_pt.dbc starts
CM_ "toyota_rav4_hybrid_2017_pt.dbc st";
CM_ "toyota_rav4_hybrid_2017_pt.dbc sta
CM_ "toyota_rav4_hybrid_2017_pt.dbc sta";
CM_ "toyota_rav4_hybrid_2017_pt.dbc star
CM_ "toyota_rav4_hybrid_2017_pt.dbc sta";
CM_ "toyota_rav4_hybrid_2017_pt.dbc star
CM_ "toyota_rav4_hybrid_2017_pt.dbc star";
CM_ "toyota_rav4_hybrid_2017_pt.dbc start
CM_ "toyota_rav4_hybrid_2017_pt.dbc sta";
CM_ "toyota_rav4_hybrid_2017_pt.dbc star
CM_ "toyota_rav4_hybrid_2017_pt.dbc star";
CM_ "toyota_rav4_hybrid_2017_pt.dbc start
CM_ "toyota_rav4_hybrid_2017_pt.dbc star";
CM_ "toyota_rav4_hybrid_2017_pt.dbc start
CM_ "toyota_rav4_hybrid_2017_pt.dbc start";
CM_ "toyota_rav4_hybrid_2017_pt.dbc starts
CM_ "toyota_rav4_hybrid_2017_pt.dbc sta";
CM_ "toyota_rav4_hybrid_2017_pt.dbc star
CM_ "toyota_rav4_hybrid_2017_pt.dbc star";
CM_ "toyota_rav4_hybrid_2017_pt.dbc start
CM_ "toyota_rav4_hybrid_2017_pt.dbc star";
CM_ "toyota_rav4_hybrid_2017_pt.dbc start
CM_ "toyota_rav4_hybrid_2017_pt.dbc start";
CM_ "toyota_rav4_hybrid_2017_pt.dbc starts
CM_ "toyota_rav4_hybrid_2017_pt.dbc sta";
CM_ "toyota_rav4_hybrid_2017_pt.dbc star
CM_ "toyota_rav4_hybrid_2017_pt.dbc star";
CM_ "toyota_rav4_hybrid_2017_pt.dbc start
CM_ "toyota_rav4_hybrid_2017_pt.dbc star";
CM_ "toyota_rav4_hybrid_2017_pt.dbc start
CM_ "toyota_rav4_hybrid_2017_pt.dbc start";
CM_ "toyota_rav4_hybrid_2017_pt.dbc starts
CM_ "toyota_rav4_hybrid_2017_pt.dbc star";
CM_ "toyota_rav4_hybrid_2017_pt.dbc start
CM_ "toyota_rav4_hybrid_2017_pt.dbc start";
CM_ "toyota_rav4_hybrid_2017_pt.dbc starts
CM_ "toyota_rav4_hybrid_2017_pt.dbc star";
CM_ "toyota_rav4_hybrid_2017_pt.dbc start
CM_ "toyota_rav4_hybrid_2017_pt.dbc start";
CM_ "toyota_rav4_hybrid_2017_pt.dbc starts
CM_ "toyota_rav4_hybrid_2017_pt.dbc start";
CM_ "toyota_rav4_hybrid_2017_pt.dbc starts
CM_ "toyota_rav4_hybrid_2017_pt.dbc start";
CM_ "toyota_rav4_hybrid_2017_pt.dbc starts
CM_ "toyota_rav4_hybrid_2017_pt.dbc starts";
CM_ "toyota_rav4_hybrid_2017_pt.dbc starts
CM_ "toyota_rav4_hybrid_2017_pt.dbc starts ";
CM_ "toyota_rav4_hybrid_2017_pt.dbc starts h
CM_ "toyota_rav4_hybrid_2017_pt.dbc sta";
CM_ "toyota_rav4_hybrid_2017_pt.dbc star
CM_ "toyota_rav4_hybrid_2017_pt.dbc star";
CM_ "toyota_rav4_hybrid_2017_pt.dbc start
CM_ "toyota_rav4_hybrid_2017_pt.dbc star";
CM_ "toyota_rav4_hybrid_2017_pt.dbc start
CM_ "toyota_rav4_hybrid_2017_pt.dbc start";
CM_ "toyota_rav4_hybrid_2017_pt.dbc starts
CM_ "toyota_rav4_hybrid_2017_pt.dbc sta";
CM_ "toyota_rav4_hybrid_2017_pt.dbc star
CM_ "toyota_rav4_hybrid_2017_pt.dbc star";
CM_ "toyota_rav4_hybrid_2017_pt.dbc start
CM_ "toyota_rav4_hybrid_2017_pt.dbc star";
CM_ "toyota_rav4_hybrid_2017_pt.dbc start
CM_ "toyota_rav4_hybrid_2017_pt.dbc start";
CM_ "toyota_rav4_hybrid_2017_pt.dbc starts
CM_ "toyota_rav4_hybrid_2017_pt.dbc star";
CM_ "toyota_rav4_hybrid_2017_pt.dbc start
CM_ "toyota_rav4_hybrid_2017_pt.dbc start";
CM_ "toyota_rav4_hybrid_2017_pt.dbc starts
CM_ "toyota_rav4_hybrid_2017_pt.dbc star";
CM_ "toyota_rav4_hybrid_2017_pt.dbc start
CM_ "toyota_rav4_hybrid_2017_pt.dbc start";
CM_ "toyota_rav4_hybrid_2017_pt.dbc starts
CM_ "toyota_rav4_hybrid_2017_pt.dbc start";
CM_ "toyota_rav4_hybrid_2017_pt.dbc starts
CM_ "toyota_rav4_hybrid_2017_pt.dbc start";
CM_ "toyota_rav4_hybrid_2017_pt.dbc starts
CM_ "toyota_rav4_hybrid_2017_pt.dbc starts";
CM_ "toyota_rav4_hybrid_2017_pt.dbc starts
CM_ "toyota_rav4_hybrid_2017_pt.dbc starts ";
CM_ "toyota_rav4_hybrid_2017_pt.dbc starts h
CM_ "toyota_rav4_hybrid_2017_pt.dbc star";
CM_ "toyota_rav4_hybrid_2017_pt.dbc start
CM_ "toyota_rav4_hybrid_2017_pt.dbc start";
CM_ "toyota_rav4_hybrid_2017_pt.dbc starts
CM_ "toyota_rav4_hybrid_2017_pt.dbc star";
CM_ "toyota_rav4_hybrid_2017_pt.dbc start
CM_ "toyota_rav4_hybrid_2017_pt.dbc start";
CM_ "toyota_rav4_hybrid_2017_pt.dbc starts
CM_ "toyota_rav4_hybrid_2017_pt.dbc start";
CM_ "toyota_rav4_hybrid_2017_pt.dbc starts
CM_ "toyota_rav4_hybrid_2017_pt.dbc start";
CM_ "toyota_rav4_hybrid_2017_pt.dbc starts
CM_ "toyota_rav4_hybrid_2017_pt.dbc starts";
CM_ "toyota_rav4_hybrid_2017_pt.dbc starts
CM_ "toyota_rav4_hybrid_2017_pt.dbc starts ";
CM_ "toyota_rav4_hybrid_2017_pt.dbc starts h
CM_ "toyota_rav4_hybrid_2017_pt.dbc start";
CM_ "toyota_rav4_hybrid_2017_pt.dbc starts
CM_ "toyota_rav4_hybrid_2017_pt.dbc start";
CM_ "toyota_rav4_hybrid_2017_pt.dbc starts
CM_ "toyota_rav4_hybrid_2017_pt.dbc starts";
CM_ "toyota_rav4_hybrid_2017_pt.dbc starts
CM_ "toyota_rav4_hybrid_2017_pt.dbc starts ";
CM_ "toyota_rav4_hybrid_2017_pt.dbc starts h
CM_ "toyota_rav4_hybrid_2017_pt.dbc starts";
CM_ "toyota_rav4_hybrid_2017_pt.dbc starts
CM_ "toyota_rav4_hybrid_2017_pt.dbc starts ";
CM_ "toyota_rav4_hybrid_2017_pt.dbc starts h
CM_ "toyota_rav4_hybrid_2017_pt.dbc starts ";
CM_ "toyota_rav4_hybrid_2017_pt.dbc starts h
CM_ "toyota_rav4_hybrid_2017_pt.dbc starts h";
CM_ "toyota_rav4_hybrid_2017_pt.dbc starts he
CM_ "toyota_rav4_hybrid_2017_pt.dbc sta";
CM_ "toyota_rav4_hybrid_2017_pt.dbc star
CM_ "toyota_rav4_hybrid_2017_pt.dbc star";
CM_ "toyota_rav4_hybrid_2017_pt.dbc start
CM_ "toyota_rav4_hybrid_2017_pt.dbc star";
CM_ "toyota_rav4_hybrid_2017_pt.dbc start
CM_ "toyota_rav4_hybrid_2017_pt.dbc start";
CM_ "toyota_rav4_hybrid_2017_pt.dbc starts
CM_ "toyota_rav4_hybrid_2017_pt.dbc sta";
CM_ "toyota_rav4_hybrid_2017_pt.dbc star
CM_ "toyota_rav4_hybrid_2017_pt.dbc star";
CM_ "toyota_rav4_hybrid_2017_pt.dbc start
CM_ "toyota_rav4_hybrid_2017_pt.dbc star";
CM_ "toyota_rav4_hybrid_2017_pt.dbc start
CM_ "toyota_rav4_hybrid_2017_pt.dbc start";
CM_ "toyota_rav4_hybrid_2017_pt.dbc starts
CM_ "toyota_rav4_hybrid_2017_pt.dbc star";
CM_ "toyota_rav4_hybrid_2017_pt.dbc start
CM_ "toyota_rav4_hybrid_2017_pt.dbc start";
CM_ "toyota_rav4_hybrid_2017_pt.dbc starts
CM_ "toyota_rav4_hybrid_2017_pt.dbc star";
CM_ "toyota_rav4_hybrid_2017_pt.dbc start
CM_ "toyota_rav4_hybrid_2017_pt.dbc start";
CM_ "toyota_rav4_hybrid_2017_pt.dbc starts
CM_ "toyota_rav4_hybrid_2017_pt.dbc start";
CM_ "toyota_rav4_hybrid_2017_pt.dbc starts
CM_ "toyota_rav4_hybrid_2017_pt.dbc start";
CM_ "toyota_rav4_hybrid_2017_pt.dbc starts
CM_ "toyota_rav4_hybrid_2017_pt.dbc starts";
CM_ "toyota_rav4_hybrid_2017_pt.dbc starts
CM_ "toyota_rav4_hybrid_2017_pt.dbc starts ";
CM_ "toyota_rav4_hybrid_2017_pt.dbc starts h
CM_ "toyota_rav4_hybrid_2017_pt.dbc star";
CM_ "toyota_rav4_hybrid_2017_pt.dbc start
CM_ "toyota_rav4_hybrid_2017_pt.dbc start";
CM_ "toyota_rav4_hybrid_2017_pt.dbc starts
CM_ "toyota_rav4_hybrid_2017_pt.dbc star";
CM_ "toyota_rav4_hybrid_2017_pt.dbc start
CM_ "toyota_rav4_hybrid_2017_pt.dbc start";
CM_ "toyota_rav4_hybrid_2017_pt.dbc starts
CM_ "toyota_rav4_hybrid_2017_pt.dbc start";
CM_ "toyota_rav4_hybrid_2017_pt.dbc starts
CM_ "toyota_rav4_hybrid_2017_pt.dbc start";
CM_ "toyota_rav4_hybrid_2017_pt.dbc starts
CM_ "toyota_rav4_hybrid_2017_pt.dbc starts";
CM_ "toyota_rav4_hybrid_2017_pt.dbc starts
CM_ "toyota_rav4_hybrid_2017_pt.dbc starts ";
CM_ "toyota_rav4_hybrid_2017_pt.dbc starts h
CM_ "toyota_rav4_hybrid_2017_pt.dbc start";
CM_ "toyota_rav4_hybrid_2017_pt.dbc starts
CM_ "toyota_rav4_hybrid_2017_pt.dbc start";
CM_ "toyota_rav4_hybrid_2017_pt.dbc starts
CM_ "toyota_rav4_hybrid_2017_pt.dbc starts";
CM_ "toyota_rav4_hybrid_2017_pt.dbc starts
CM_ "toyota_rav4_hybrid_2017_pt.dbc starts ";
CM_ "toyota_rav4_hybrid_2017_pt.dbc starts h
CM_ "toyota_rav4_hybrid_2017_pt.dbc starts";
CM_ "toyota_rav4_hybrid_2017_pt.dbc starts
CM_ "toyota_rav4_hybrid_2017_pt.dbc starts ";
CM_ "toyota_rav4_hybrid_2017_pt.dbc starts h
CM_ "toyota_rav4_hybrid_2017_pt.dbc starts ";
CM_ "toyota_rav4_hybrid_2017_pt.dbc starts h
CM_ "toyota_rav4_hybrid_2017_pt.dbc starts h";
CM_ "toyota_rav4_hybrid_2017_pt.dbc starts he
CM_ "toyota_rav4_hybrid_2017_pt.dbc star";
CM_ "toyota_rav4_hybrid_2017_pt.dbc start
CM_ "toyota_rav4_hybrid_2017_pt.dbc start";
CM_ "toyota_rav4_hybrid_2017_pt.dbc starts
CM_ "toyota_rav4_hybrid_2017_pt.dbc star";
CM_ "toyota_rav4_hybrid_2017_pt.dbc start
CM_ "toyota_rav4_hybrid_2017_pt.dbc start";
CM_ "toyota_rav4_hybrid_2017_pt.dbc starts
CM_ "toyota_rav4_hybrid_2017_pt.dbc start";
CM_ "toyota_rav4_hybrid_2017_pt.dbc starts
CM_ "toyota_rav4_hybrid_2017_pt.dbc start";
CM_ "toyota_rav4_hybrid_2017_pt.dbc starts
CM_ "toyota_rav4_hybrid_2017_pt.dbc starts";
CM_ "toyota_rav4_hybrid_2017_pt.dbc starts
CM_ "toyota_rav4_hybrid_2017_pt.dbc starts ";
CM_ "toyota_rav4_hybrid_2017_pt.dbc starts h
CM_ "toyota_rav4_hybrid_2017_pt.dbc start";
CM_ "toyota_rav4_hybrid_2017_pt.dbc starts
CM_ "toyota_rav4_hybrid_2017_pt.dbc start";
CM_ "toyota_rav4_hybrid_2017_pt.dbc starts
CM_ "toyota_rav4_hybrid_2017_pt.dbc starts";
CM_ "toyota_rav4_hybrid_2017_pt.dbc starts
CM_ "toyota_rav4_hybrid_2017_pt.dbc starts ";
CM_ "toyota_rav4_hybrid_2017_pt.dbc starts h
CM_ "toyota_rav4_hybrid_2017_pt.dbc starts";
CM_ "toyota_rav4_hybrid_2017_pt.dbc starts
CM_ "toyota_rav4_hybrid_2017_pt.dbc starts ";
CM_ "toyota_rav4_hybrid_2017_pt.dbc starts h
CM_ "toyota_rav4_hybrid_2017_pt.dbc starts ";
CM_ "toyota_rav4_hybrid_2017_pt.dbc starts h
CM_ "toyota_rav4_hybrid_2017_pt.dbc starts h";
CM_ "toyota_rav4_hybrid_2017_pt.dbc starts he
CM_ "toyota_rav4_hybrid_2017_pt.dbc start";
CM_ "toyota_rav4_hybrid_2017_pt.dbc starts
CM_ "toyota_rav4_hybrid_2017_pt.dbc start";
CM_ "toyota_rav4_hybrid_2017_pt.dbc starts
CM_ "toyota_rav4_hybrid_2017_pt.dbc starts";
CM_ "toyota_rav4_hybrid_2017_pt.dbc starts
CM_ "toyota_rav4_hybrid_2017_pt.dbc starts ";
CM_ "toyota_rav4_hybrid_2017_pt.dbc starts h
CM_ "toyota_rav4_hybrid_2017_pt.dbc starts";
CM_ "toyota_rav4_hybrid_2017_pt.dbc starts
CM_ "toyota_rav4_hybrid_2017_pt.dbc starts ";
CM_ "toyota_rav4_hybrid_2017_pt.dbc starts h
CM_ "toyota_rav4_hybrid_2017_pt.dbc starts ";
CM_ "toyota_rav4_hybrid_2017_pt.dbc starts h
CM_ "toyota_rav4_hybrid_2017_pt.dbc starts h";
CM_ "toyota_rav4_hybrid_2017_pt.dbc starts he
CM_ "toyota_rav4_hybrid_2017_pt.dbc starts";
CM_ "toyota_rav4_hybrid_2017_pt.dbc starts
CM_ "toyota_rav4_hybrid_2017_pt.dbc starts ";
CM_ "toyota_rav4_hybrid_2017_pt.dbc starts h
CM_ "toyota_rav4_hybrid_2017_pt.dbc starts ";
CM_ "toyota_rav4_hybrid_2017_pt.dbc starts h
CM_ "toyota_rav4_hybrid_2017_pt.dbc starts h";
CM_ "toyota_rav4_hybrid_2017_pt.dbc starts he
CM_ "toyota_rav4_hybrid_2017_pt.dbc starts ";
CM_ "toyota_rav4_hybrid_2017_pt.dbc starts h
CM_ "toyota_rav4_hybrid_2017_pt.dbc starts h";
CM_ "toyota_rav4_hybrid_2017_pt.dbc starts he
CM_ "toyota_rav4_hybrid_2017_pt.dbc starts h";
CM_ "toyota_rav4_hybrid_2017_pt.dbc starts he
CM_ "toyota_rav4_hybrid_2017_pt.dbc starts he";
CM_ "toyota_rav4_hybrid_2017_pt.dbc starts her
CM_ "toyota_rav4_hybrid_2017_pt.dbc sta";
CM_ "toyota_rav4_hybrid_2017_pt.dbc star
CM_ "toyota_rav4_hybrid_2017_pt.dbc star";
CM_ "toyota_rav4_hybrid_2017_pt.dbc start
CM_ "toyota_rav4_hybrid_2017_pt.dbc star";
CM_ "toyota_rav4_hybrid_2017_pt.dbc start
CM_ "toyota_rav4_hybrid_2017_pt.dbc start";
CM_ "toyota_rav4_hybrid_2017_pt.dbc starts
CM_ "toyota_rav4_hybrid_2017_pt.dbc sta";
CM_ "toyota_rav4_hybrid_2017_pt.dbc star
CM_ "toyota_rav4_hybrid_2017_pt.dbc star";
CM_ "toyota_rav4_hybrid_2017_pt.dbc start
CM_ "toyota_rav4_hybrid_2017_pt.dbc star";
CM_ "toyota_rav4_hybrid_2017_pt.dbc start
CM_ "toyota_rav4_hybrid_2017_pt.dbc start";
CM_ "toyota_rav4_hybrid_2017_pt.dbc starts
CM_ "toyota_rav4_hybrid_2017_pt.dbc star";
CM_ "toyota_rav4_hybrid_2017_pt.dbc start
CM_ "toyota_rav4_hybrid_2017_pt.dbc start";
CM_ "toyota_rav4_hybrid_2017_pt.dbc starts
CM_ "toyota_rav4_hybrid_2017_pt.dbc star";
CM_ "toyota_rav4_hybrid_2017_pt.dbc start
CM_ "toyota_rav4_hybrid_2017_pt.dbc start";
CM_ "toyota_rav4_hybrid_2017_pt.dbc starts
CM_ "toyota_rav4_hybrid_2017_pt.dbc start";
CM_ "toyota_rav4_hybrid_2017_pt.dbc starts
CM_ "toyota_rav4_hybrid_2017_pt.dbc start";
CM_ "toyota_rav4_hybrid_2017_pt.dbc starts
CM_ "toyota_rav4_hybrid_2017_pt.dbc starts";
CM_ "toyota_rav4_hybrid_2017_pt.dbc starts
CM_ "toyota_rav4_hybrid_2017_pt.dbc starts ";
CM_ "toyota_rav4_hybrid_2017_pt.dbc starts h
CM_ "toyota_rav4_hybrid_2017_pt.dbc star";
CM_ "toyota_rav4_hybrid_2017_pt.dbc start
CM_ "toyota_rav4_hybrid_2017_pt.dbc start";
CM_ "toyota_rav4_hybrid_2017_pt.dbc starts
CM_ "toyota_rav4_hybrid_2017_pt.dbc star";
CM_ "toyota_rav4_hybrid_2017_pt.dbc start
CM_ "toyota_rav4_hybrid_2017_pt.dbc start";
CM_ "toyota_rav4_hybrid_2017_pt.dbc starts
CM_ "toyota_rav4_hybrid_2017_pt.dbc start";
CM_ "toyota_rav4_hybrid_2017_pt.dbc starts
CM_ "toyota_rav4_hybrid_2017_pt.dbc start";
CM_ "toyota_rav4_hybrid_2017_pt.dbc starts
CM_ "toyota_rav4_hybrid_2017_pt.dbc starts";
CM_ "toyota_rav4_hybrid_2017_pt.dbc starts
CM_ "toyota_rav4_hybrid_2017_pt.dbc starts ";
CM_ "toyota_rav4_hybrid_2017_pt.dbc starts h
CM_ "toyota_rav4_hybrid_2017_pt.dbc start";
CM_ "toyota_rav4_hybrid_2017_pt.dbc starts
CM_ "toyota_rav4_hybrid_2017_pt.dbc start";
CM_ "toyota_rav4_hybrid_2017_pt.dbc starts
CM_ "toyota_rav4_hybrid_2017_pt.dbc starts";
CM_ "toyota_rav4_hybrid_2017_pt.dbc starts
CM_ "toyota_rav4_hybrid_2017_pt.dbc starts ";
CM_ "toyota_rav4_hybrid_2017_pt.dbc starts h
CM_ "toyota_rav4_hybrid_2017_pt.dbc starts";
CM_ "toyota_rav4_hybrid_2017_pt.dbc starts
CM_ "toyota_rav4_hybrid_2017_pt.dbc starts ";
CM_ "toyota_rav4_hybrid_2017_pt.dbc starts h
CM_ "toyota_rav4_hybrid_2017_pt.dbc starts ";
CM_ "toyota_rav4_hybrid_2017_pt.dbc starts h
CM_ "toyota_rav4_hybrid_2017_pt.dbc starts h";
CM_ "toyota_rav4_hybrid_2017_pt.dbc starts he
CM_ "toyota_rav4_hybrid_2017_pt.dbc star";
CM_ "toyota_rav4_hybrid_2017_pt.dbc start
CM_ "toyota_rav4_hybrid_2017_pt.dbc start";
CM_ "toyota_rav4_hybrid_2017_pt.dbc starts
CM_ "toyota_rav4_hybrid_2017_pt.dbc star";
CM_ "toyota_rav4_hybrid_2017_pt.dbc start
CM_ "toyota_rav4_hybrid_2017_pt.dbc start";
CM_ "toyota_rav4_hybrid_2017_pt.dbc starts
CM_ "toyota_rav4_hybrid_2017_pt.dbc start";
CM_ "toyota_rav4_hybrid_2017_pt.dbc starts
CM_ "toyota_rav4_hybrid_2017_pt.dbc start";
CM_ "toyota_rav4_hybrid_2017_pt.dbc starts
CM_ "toyota_rav4_hybrid_2017_pt.dbc starts";
CM_ "toyota_rav4_hybrid_2017_pt.dbc starts
CM_ "toyota_rav4_hybrid_2017_pt.dbc starts ";
CM_ "toyota_rav4_hybrid_2017_pt.dbc starts h
CM_ "toyota_rav4_hybrid_2017_pt.dbc start";
CM_ "toyota_rav4_hybrid_2017_pt.dbc starts
CM_ "toyota_rav4_hybrid_2017_pt.dbc start";
CM_ "toyota_rav4_hybrid_2017_pt.dbc starts
CM_ "toyota_rav4_hybrid_2017_pt.dbc starts";
CM_ "toyota_rav4_hybrid_2017_pt.dbc starts
CM_ "toyota_rav4_hybrid_2017_pt.dbc starts ";
CM_ "toyota_rav4_hybrid_2017_pt.dbc starts h
CM_ "toyota_rav4_hybrid_2017_pt.dbc starts";
CM_ "toyota_rav4_hybrid_2017_pt.dbc starts
CM_ "toyota_rav4_hybrid_2017_pt.dbc starts ";
CM_ "toyota_rav4_hybrid_2017_pt.dbc starts h
CM_ "toyota_rav4_hybrid_2017_pt.dbc starts ";
CM_ "toyota_rav4_hybrid_2017_pt.dbc starts h
CM_ "toyota_rav4_hybrid_2017_pt.dbc starts h";
CM_ "toyota_rav4_hybrid_2017_pt.dbc starts he
CM_ "toyota_rav4_hybrid_2017_pt.dbc start";
CM_ "toyota_rav4_hybrid_2017_pt.dbc starts
CM_ "toyota_rav4_hybrid_2017_pt.dbc start";
CM_ "toyota_rav4_hybrid_2017_pt.dbc starts
CM_ "toyota_rav4_hybrid_2017_pt.dbc starts";
CM_ "toyota_rav4_hybrid_2017_pt.dbc starts
CM_ "toyota_rav4_hybrid_2017_pt.dbc starts ";
CM_ "toyota_rav4_hybrid_2017_pt.dbc starts h
CM_ "toyota_rav4_hybrid_2017_pt.dbc starts";
CM_ "toyota_rav4_hybrid_2017_pt.dbc starts
CM_ "toyota_rav4_hybrid_2017_pt.dbc starts ";
CM_ "toyota_rav4_hybrid_2017_pt.dbc starts h
CM_ "toyota_rav4_hybrid_2017_pt.dbc starts ";
CM_ "toyota_rav4_hybrid_2017_pt.dbc starts h
CM_ "toyota_rav4_hybrid_2017_pt.dbc starts h";
CM_ "toyota_rav4_hybrid_2017_pt.dbc starts he
CM_ "toyota_rav4_hybrid_2017_pt.dbc starts";
CM_ "toyota_rav4_hybrid_2017_pt.dbc starts
CM_ "toyota_rav4_hybrid_2017_pt.dbc starts ";
CM_ "toyota_rav4_hybrid_2017_pt.dbc starts h
CM_ "toyota_rav4_hybrid_2017_pt.dbc starts ";
CM_ "toyota_rav4_hybrid_2017_pt.dbc starts h
CM_ "toyota_rav4_hybrid_2017_pt.dbc starts h";
CM_ "toyota_rav4_hybrid_2017_pt.dbc starts he
CM_ "toyota_rav4_hybrid_2017_pt.dbc starts ";
CM_ "toyota_rav4_hybrid_2017_pt.dbc starts h
CM_ "toyota_rav4_hybrid_2017_pt.dbc starts h";
CM_ "toyota_rav4_hybrid_2017_pt.dbc starts he
CM_ "toyota_rav4_hybrid_2017_pt.dbc starts h";
CM_ "toyota_rav4_hybrid_2017_pt.dbc starts he
CM_ "toyota_rav4_hybrid_2017_pt.dbc starts he";
CM_ "toyota_rav4_hybrid_2017_pt.dbc starts her
CM_ "toyota_rav4_hybrid_2017_pt.dbc star";
CM_ "toyota_rav4_hybrid_2017_pt.dbc start
CM_ "toyota_rav4_hybrid_2017_pt.dbc start";
CM_ "toyota_rav4_hybrid_2017_pt.dbc starts
CM_ "toyota_rav4_hybrid_2017_pt.dbc star";
CM_ "toyota_rav4_hybrid_2017_pt.dbc start
CM_ "toyota_rav4_hybrid_2017_pt.dbc start";
CM_ "toyota_rav4_hybrid_2017_pt.dbc starts
CM_ "toyota_rav4_hybrid_2017_pt.dbc start";
CM_ "toyota_rav4_hybrid_2017_pt.dbc starts
CM_ "toyota_rav4_hybrid_2017_pt.dbc start";
CM_ "toyota_rav4_hybrid_2017_pt.dbc starts
CM_ "toyota_rav4_hybrid_2017_pt.dbc starts";
CM_ "toyota_rav4_hybrid_2017_pt.dbc starts
CM_ "toyota_rav4_hybrid_2017_pt.dbc starts ";
CM_ "toyota_rav4_hybrid_2017_pt.dbc starts h
CM_ "toyota_rav4_hybrid_2017_pt.dbc start";
CM_ "toyota_rav4_hybrid_2017_pt.dbc starts
CM_ "toyota_rav4_hybrid_2017_pt.dbc start";
CM_ "toyota_rav4_hybrid_2017_pt.dbc starts
CM_ "toyota_rav4_hybrid_2017_pt.dbc starts";
CM_ "toyota_rav4_hybrid_2017_pt.dbc starts
CM_ "toyota_rav4_hybrid_2017_pt.dbc starts ";
CM_ "toyota_rav4_hybrid_2017_pt.dbc starts h
CM_ "toyota_rav4_hybrid_2017_pt.dbc starts";
CM_ "toyota_rav4_hybrid_2017_pt.dbc starts
CM_ "toyota_rav4_hybrid_2017_pt.dbc starts ";
CM_ "toyota_rav4_hybrid_2017_pt.dbc starts h
CM_ "toyota_rav4_hybrid_2017_pt.dbc starts ";
CM_ "toyota_rav4_hybrid_2017_pt.dbc starts h
CM_ "toyota_rav4_hybrid_2017_pt.dbc starts h";
CM_ "toyota_rav4_hybrid_2017_pt.dbc starts he
CM_ "toyota_rav4_hybrid_2017_pt.dbc start";
CM_ "toyota_rav4_hybrid_2017_pt.dbc starts
CM_ "toyota_rav4_hybrid_2017_pt.dbc start";
CM_ "toyota_rav4_hybrid_2017_pt.dbc starts
CM_ "toyota_rav4_hybrid_2017_pt.dbc starts";
CM_ "toyota_rav4_hybrid_2017_pt.dbc starts
CM_ "toyota_rav4_hybrid_2017_pt.dbc starts ";
CM_ "toyota_rav4_hybrid_2017_pt.dbc starts h
CM_ "toyota_rav4_hybrid_2017_pt.dbc starts";
CM_ "toyota_rav4_hybrid_2017_pt.dbc starts
CM_ "toyota_rav4_hybrid_2017_pt.dbc starts ";
CM_ "toyota_rav4_hybrid_2017_pt.dbc starts h
CM_ "toyota_rav4_hybrid_2017_pt.dbc starts ";
CM_ "toyota_rav4_hybrid_2017_pt.dbc starts h
CM_ "toyota_rav4_hybrid_2017_pt.dbc starts h";
CM_ "toyota_rav4_hybrid_2017_pt.dbc starts he
CM_ "toyota_rav4_hybrid_2017_pt.dbc starts";
CM_ "toyota_rav4_hybrid_2017_pt.dbc starts
CM_ "toyota_rav4_hybrid_2017_pt.dbc starts ";
CM_ "toyota_rav4_hybrid_2017_pt.dbc starts h
CM_ "toyota_rav4_hybrid_2017_pt.dbc starts ";
CM_ "toyota_rav4_hybrid_2017_pt.dbc starts h
CM_ "toyota_rav4_hybrid_2017_pt.dbc starts h";
CM_ "toyota_rav4_hybrid_2017_pt.dbc starts he
CM_ "toyota_rav4_hybrid_2017_pt.dbc starts ";
CM_ "toyota_rav4_hybrid_2017_pt.dbc starts h
CM_ "toyota_rav4_hybrid_2017_pt.dbc starts h";
CM_ "toyota_rav4_hybrid_2017_pt.dbc starts he
CM_ "toyota_rav4_hybrid_2017_pt.dbc starts h";
CM_ "toyota_rav4_hybrid_2017_pt.dbc starts he
CM_ "toyota_rav4_hybrid_2017_pt.dbc starts he";
CM_ "toyota_rav4_hybrid_2017_pt.dbc starts her
CM_ "toyota_rav4_hybrid_2017_pt.dbc start";
CM_ "toyota_rav4_hybrid_2017_pt.dbc starts
CM_ "toyota_rav4_hybrid_2017_pt.dbc start";
CM_ "toyota_rav4_hybrid_2017_pt.dbc starts
CM_ "toyota_rav4_hybrid_2017_pt.dbc starts";
CM_ "toyota_rav4_hybrid_2017_pt.dbc starts
CM_ "toyota_rav4_hybrid_2017_pt.dbc starts ";
CM_ "toyota_rav4_hybrid_2017_pt.dbc starts h
CM_ "toyota_rav4_hybrid_2017_pt.dbc starts";
CM_ "toyota_rav4_hybrid_2017_pt.dbc starts
CM_ "toyota_rav4_hybrid_2017_pt.dbc starts ";
CM_ "toyota_rav4_hybrid_2017_pt.dbc starts h
CM_ "toyota_rav4_hybrid_2017_pt.dbc starts ";
CM_ "toyota_rav4_hybrid_2017_pt.dbc starts h
CM_ "toyota_rav4_hybrid_2017_pt.dbc starts h";
CM_ "toyota_rav4_hybrid_2017_pt.dbc starts he
CM_ "toyota_rav4_hybrid_2017_pt.dbc starts";
CM_ "toyota_rav4_hybrid_2017_pt.dbc starts
CM_ "toyota_rav4_hybrid_2017_pt.dbc starts ";
CM_ "toyota_rav4_hybrid_2017_pt.dbc starts h
CM_ "toyota_rav4_hybrid_2017_pt.dbc starts ";
CM_ "toyota_rav4_hybrid_2017_pt.dbc starts h
CM_ "toyota_rav4_hybrid_2017_pt.dbc starts h";
CM_ "toyota_rav4_hybrid_2017_pt.dbc starts he
CM_ "toyota_rav4_hybrid_2017_pt.dbc starts ";
CM_ "toyota_rav4_hybrid_2017_pt.dbc starts h
CM_ "toyota_rav4_hybrid_2017_pt.dbc starts h";
CM_ "toyota_rav4_hybrid_2017_pt.dbc starts he
CM_ "toyota_rav4_hybrid_2017_pt.dbc starts h";
CM_ "toyota_rav4_hybrid_2017_pt.dbc starts he
CM_ "toyota_rav4_hybrid_2017_pt.dbc starts he";
CM_ "toyota_rav4_hybrid_2017_pt.dbc starts her
CM_ "toyota_rav4_hybrid_2017_pt.dbc starts";
CM_ "toyota_rav4_hybrid_2017_pt.dbc starts
CM_ "toyota_rav4_hybrid_2017_pt.dbc starts ";
CM_ "toyota_rav4_hybrid_2017_pt.dbc starts h
CM_ "toyota_rav4_hybrid_2017_pt.dbc starts ";
CM_ "toyota_rav4_hybrid_2017_pt.dbc starts h
CM_ "toyota_rav4_hybrid_2017_pt.dbc starts h";
CM_ "toyota_rav4_hybrid_2017_pt.dbc starts he
CM_ "toyota_rav4_hybrid_2017_pt.dbc starts ";
CM_ "toyota_rav4_hybrid_2017_pt.dbc starts h
CM_ "toyota_rav4_hybrid_2017_pt.dbc starts h";
CM_ "toyota_rav4_hybrid_2017_pt.dbc starts he
CM_ "toyota_rav4_hybrid_2017_pt.dbc starts h";
CM_ "toyota_rav4_hybrid_2017_pt.dbc starts he
CM_ "toyota_rav4_hybrid_2017_pt.dbc starts he";
CM_ "toyota_rav4_hybrid_2017_pt.dbc starts her
CM_ "toyota_rav4_hybrid_2017_pt.dbc starts ";
CM_ "toyota_rav4_hybrid_2017_pt.dbc starts h
CM_ "toyota_rav4_hybrid_2017_pt.dbc starts h";
CM_ "toyota_rav4_hybrid_2017_pt.dbc starts he
CM_ "toyota_rav4_hybrid_2017_pt.dbc starts h";
CM_ "toyota_rav4_hybrid_2017_pt.dbc starts he
CM_ "toyota_rav4_hybrid_2017_pt.dbc starts he";
CM_ "toyota_rav4_hybrid_2017_pt.dbc starts her
CM_ "toyota_rav4_hybrid_2017_pt.dbc starts h";
CM_ "toyota_rav4_hybrid_2017_pt.dbc starts he
CM_ "toyota_rav4_hybrid_2017_pt.dbc starts he";
CM_ "toyota_rav4_hybrid_2017_pt.dbc starts her
CM_ "toyota_rav4_hybrid_2017_pt.dbc starts he";
CM_ "toyota_rav4_hybrid_2017_pt.dbc starts her
CM_ "toyota_rav4_hybrid_2017_pt.dbc starts her";
CM_ "toyota_rav4_hybrid_2017_pt.dbc starts here
CM_ "toyota_rav4_hybrid_2017_pt.dbc st";
CM_ "toyota_rav4_hybrid_2017_pt.dbc sta
CM_ "toyota_rav4_hybrid_2017_pt.dbc sta";
CM_ "toyota_rav4_hybrid_2017_pt.dbc star
CM_ "toyota_rav4_hybrid_2017_pt.dbc sta";
CM_ "toyota_rav4_hybrid_2017_pt.dbc star
CM_ "toyota_rav4_hybrid_2017_pt.dbc star";
CM_ "toyota_rav4_hybrid_2017_pt.dbc start
CM_ "toyota_rav4_hybrid_2017_pt.dbc sta";
CM_ "toyota_rav4_hybrid_2017_pt.dbc star
CM_ "toyota_rav4_hybrid_2017_pt.dbc star";
CM_ "toyota_rav4_hybrid_2017_pt.dbc start
CM_ "toyota_rav4_hybrid_2017_pt.dbc star";
CM_ "toyota_rav4_hybrid_2017_pt.dbc start
CM_ "toyota_rav4_hybrid_2017_pt.dbc start";
CM_ "toyota_rav4_hybrid_2017_pt.dbc starts
CM_ "toyota_rav4_hybrid_2017_pt.dbc st";
CM_ "toyota_rav4_hybrid_2017_pt.dbc sta
CM_ "toyota_rav4_hybrid_2017_pt.dbc sta";
CM_ "toyota_rav4_hybrid_2017_pt.dbc star
CM_ "toyota_rav4_hybrid_2017_pt.dbc sta";
CM_ "toyota_rav4_hybrid_2017_pt.dbc star
CM_ "toyota_rav4_hybrid_2017_pt.dbc star";
CM_ "toyota_rav4_hybrid_2017_pt.dbc start
CM_ "toyota_rav4_hybrid_2017_pt.dbc sta";
CM_ "toyota_rav4_hybrid_2017_pt.dbc star
CM_ "toyota_rav4_hybrid_2017_pt.dbc star";
CM_ "toyota_rav4_hybrid_2017_pt.dbc start
CM_ "toyota_rav4_hybrid_2017_pt.dbc star";
CM_ "toyota_rav4_hybrid_2017_pt.dbc start
CM_ "toyota_rav4_hybrid_2017_pt.dbc start";
CM_ "toyota_rav4_hybrid_2017_pt.dbc starts
CM_ "toyota_rav4_hybrid_2017_pt.dbc sta";
CM_ "toyota_rav4_hybrid_2017_pt.dbc star
CM_ "toyota_rav4_hybrid_2017_pt.dbc star";
CM_ "toyota_rav4_hybrid_2017_pt.dbc start
CM_ "toyota_rav4_hybrid_2017_pt.dbc star";
CM_ "toyota_rav4_hybrid_2017_pt.dbc start
CM_ "toyota_rav4_hybrid_2017_pt.dbc start";
CM_ "toyota_rav4_hybrid_2017_pt.dbc starts
CM_ "toyota_rav4_hybrid_2017_pt.dbc sta";
CM_ "toyota_rav4_hybrid_2017_pt.dbc star
CM_ "toyota_rav4_hybrid_2017_pt.dbc star";
CM_ "toyota_rav4_hybrid_2017_pt.dbc start
CM_ "toyota_rav4_hybrid_2017_pt.dbc star";
CM_ "toyota_rav4_hybrid_2017_pt.dbc start
CM_ "toyota_rav4_hybrid_2017_pt.dbc start";
CM_ "toyota_rav4_hybrid_2017_pt.dbc starts
CM_ "toyota_rav4_hybrid_2017_pt.dbc star";
CM_ "toyota_rav4_hybrid_2017_pt.dbc start
CM_ "toyota_rav4_hybrid_2017_pt.dbc start";
CM_ "toyota_rav4_hybrid_2017_pt.dbc starts
CM_ "toyota_rav4_hybrid_2017_pt.dbc star";
CM_ "toyota_rav4_hybrid_2017_pt.dbc start
CM_ "toyota_rav4_hybrid_2017_pt.dbc start";
CM_ "toyota_rav4_hybrid_2017_pt.dbc starts
CM_ "toyota_rav4_hybrid_2017_pt.dbc start";
CM_ "toyota_rav4_hybrid_2017_pt.dbc starts
CM_ "toyota_rav4_hybrid_2017_pt.dbc start";
CM_ "toyota_rav4_hybrid_2017_pt.dbc starts
CM_ "toyota_rav4_hybrid_2017_pt.dbc starts";
CM_ "toyota_rav4_hybrid_2017_pt.dbc starts
CM_ "toyota_rav4_hybrid_2017_pt.dbc starts ";
CM_ "toyota_rav4_hybrid_2017_pt.dbc starts h
CM_ "toyota_rav4_hybrid_2017_pt.dbc sta";
CM_ "toyota_rav4_hybrid_2017_pt.dbc star
CM_ "toyota_rav4_hybrid_2017_pt.dbc star";
CM_ "toyota_rav4_hybrid_2017_pt.dbc start
CM_ "toyota_rav4_hybrid_2017_pt.dbc star";
CM_ "toyota_rav4_hybrid_2017_pt.dbc start
CM_ "toyota_rav4_hybrid_2017_pt.dbc start";
CM_ "toyota_rav4_hybrid_2017_pt.dbc starts
CM_ "toyota_rav4_hybrid_2017_pt.dbc sta";
CM_ "toyota_rav4_hybrid_2017_pt.dbc star
CM_ "toyota_rav4_hybrid_2017_pt.dbc star";
CM_ "toyota_rav4_hybrid_2017_pt.dbc start
CM_ "toyota_rav4_hybrid_2017_pt.dbc star";
CM_ "toyota_rav4_hybrid_2017_pt.dbc start
CM_ "toyota_rav4_hybrid_2017_pt.dbc start";
CM_ "toyota_rav4_hybrid_2017_pt.dbc starts
CM_ "toyota_rav4_hybrid_2017_pt.dbc star";
CM_ "toyota_rav4_hybrid_2017_pt.dbc start
CM_ "toyota_rav4_hybrid_2017_pt.dbc start";
CM_ "toyota_rav4_hybrid_2017_pt.dbc starts
CM_ "toyota_rav4_hybrid_2017_pt.dbc star";
CM_ "toyota_rav4_hybrid_2017_pt.dbc start
CM_ "toyota_rav4_hybrid_2017_pt.dbc start";
CM_ "toyota_rav4_hybrid_2017_pt.dbc starts
CM_ "toyota_rav4_hybrid_2017_pt.dbc start";
CM_ "toyota_rav4_hybrid_2017_pt.dbc starts
CM_ "toyota_rav4_hybrid_2017_pt.dbc start";
CM_ "toyota_rav4_hybrid_2017_pt.dbc starts
CM_ "toyota_rav4_hybrid_2017_pt.dbc starts";
CM_ "toyota_rav4_hybrid_2017_pt.dbc starts
CM_ "toyota_rav4_hybrid_2017_pt.dbc starts ";
CM_ "toyota_rav4_hybrid_2017_pt.dbc starts h
CM_ "toyota_rav4_hybrid_2017_pt.dbc star";
CM_ "toyota_rav4_hybrid_2017_pt.dbc start
CM_ "toyota_rav4_hybrid_2017_pt.dbc start";
CM_ "toyota_rav4_hybrid_2017_pt.dbc starts
CM_ "toyota_rav4_hybrid_2017_pt.dbc star";
CM_ "toyota_rav4_hybrid_2017_pt.dbc start
CM_ "toyota_rav4_hybrid_2017_pt.dbc start";
CM_ "toyota_rav4_hybrid_2017_pt.dbc starts
CM_ "toyota_rav4_hybrid_2017_pt.dbc start";
CM_ "toyota_rav4_hybrid_2017_pt.dbc starts
CM_ "toyota_rav4_hybrid_2017_pt.dbc start";
CM_ "toyota_rav4_hybrid_2017_pt.dbc starts
CM_ "toyota_rav4_hybrid_2017_pt.dbc starts";
CM_ "toyota_rav4_hybrid_2017_pt.dbc starts
CM_ "toyota_rav4_hybrid_2017_pt.dbc starts ";
CM_ "toyota_rav4_hybrid_2017_pt.dbc starts h
CM_ "toyota_rav4_hybrid_2017_pt.dbc start";
CM_ "toyota_rav4_hybrid_2017_pt.dbc starts
CM_ "toyota_rav4_hybrid_2017_pt.dbc start";
CM_ "toyota_rav4_hybrid_2017_pt.dbc starts
CM_ "toyota_rav4_hybrid_2017_pt.dbc starts";
CM_ "toyota_rav4_hybrid_2017_pt.dbc starts
CM_ "toyota_rav4_hybrid_2017_pt.dbc starts ";
CM_ "toyota_rav4_hybrid_2017_pt.dbc starts h
CM_ "toyota_rav4_hybrid_2017_pt.dbc starts";
CM_ "toyota_rav4_hybrid_2017_pt.dbc starts
CM_ "toyota_rav4_hybrid_2017_pt.dbc starts ";
CM_ "toyota_rav4_hybrid_2017_pt.dbc starts h
CM_ "toyota_rav4_hybrid_2017_pt.dbc starts ";
CM_ "toyota_rav4_hybrid_2017_pt.dbc starts h
CM_ "toyota_rav4_hybrid_2017_pt.dbc starts h";
CM_ "toyota_rav4_hybrid_2017_pt.dbc starts he
CM_ "toyota_rav4_hybrid_2017_pt.dbc sta";
CM_ "toyota_rav4_hybrid_2017_pt.dbc star
CM_ "toyota_rav4_hybrid_2017_pt.dbc star";
CM_ "toyota_rav4_hybrid_2017_pt.dbc start
CM_ "toyota_rav4_hybrid_2017_pt.dbc star";
CM_ "toyota_rav4_hybrid_2017_pt.dbc start
CM_ "toyota_rav4_hybrid_2017_pt.dbc start";
CM_ "toyota_rav4_hybrid_2017_pt.dbc starts
CM_ "toyota_rav4_hybrid_2017_pt.dbc sta";
CM_ "toyota_rav4_hybrid_2017_pt.dbc star
CM_ "toyota_rav4_hybrid_2017_pt.dbc star";
CM_ "toyota_rav4_hybrid_2017_pt.dbc start
CM_ "toyota_rav4_hybrid_2017_pt.dbc star";
CM_ "toyota_rav4_hybrid_2017_pt.dbc start
CM_ "toyota_rav4_hybrid_2017_pt.dbc start";
CM_ "toyota_rav4_hybrid_2017_pt.dbc starts
CM_ "toyota_rav4_hybrid_2017_pt.dbc star";
CM_ "toyota_rav4_hybrid_2017_pt.dbc start
CM_ "toyota_rav4_hybrid_2017_pt.dbc start";
CM_ "toyota_rav4_hybrid_2017_pt.dbc starts
CM_ "toyota_rav4_hybrid_2017_pt.dbc star";
CM_ "toyota_rav4_hybrid_2017_pt.dbc start
CM_ "toyota_rav4_hybrid_2017_pt.dbc start";
CM_ "toyota_rav4_hybrid_2017_pt.dbc starts
CM_ "toyota_rav4_hybrid_2017_pt.dbc start";
CM_ "toyota_rav4_hybrid_2017_pt.dbc starts
CM_ "toyota_rav4_hybrid_2017_pt.dbc start";
CM_ "toyota_rav4_hybrid_2017_pt.dbc starts
CM_ "toyota_rav4_hybrid_2017_pt.dbc starts";
CM_ "toyota_rav4_hybrid_2017_pt.dbc starts
CM_ "toyota_rav4_hybrid_2017_pt.dbc starts ";
CM_ "toyota_rav4_hybrid_2017_pt.dbc starts h
CM_ "toyota_rav4_hybrid_2017_pt.dbc star";
CM_ "toyota_rav4_hybrid_2017_pt.dbc start
CM_ "toyota_rav4_hybrid_2017_pt.dbc start";
CM_ "toyota_rav4_hybrid_2017_pt.dbc starts
CM_ "toyota_rav4_hybrid_2017_pt.dbc star";
CM_ "toyota_rav4_hybrid_2017_pt.dbc start
CM_ "toyota_rav4_hybrid_2017_pt.dbc start";
CM_ "toyota_rav4_hybrid_2017_pt.dbc starts
CM_ "toyota_rav4_hybrid_2017_pt.dbc start";
CM_ "toyota_rav4_hybrid_2017_pt.dbc starts
CM_ "toyota_rav4_hybrid_2017_pt.dbc start";
CM_ "toyota_rav4_hybrid_2017_pt.dbc starts
CM_ "toyota_rav4_hybrid_2017_pt.dbc starts";
CM_ "toyota_rav4_hybrid_2017_pt.dbc starts
CM_ "toyota_rav4_hybrid_2017_pt.dbc starts ";
CM_ "toyota_rav4_hybrid_2017_pt.dbc starts h
CM_ "toyota_rav4_hybrid_2017_pt.dbc start";
CM_ "toyota_rav4_hybrid_2017_pt.dbc starts
CM_ "toyota_rav4_hybrid_2017_pt.dbc start";
CM_ "toyota_rav4_hybrid_2017_pt.dbc starts
CM_ "toyota_rav4_hybrid_2017_pt.dbc starts";
CM_ "toyota_rav4_hybrid_2017_pt.dbc starts
CM_ "toyota_rav4_hybrid_2017_pt.dbc starts ";
CM_ "toyota_rav4_hybrid_2017_pt.dbc starts h
CM_ "toyota_rav4_hybrid_2017_pt.dbc starts";
CM_ "toyota_rav4_hybrid_2017_pt.dbc starts
CM_ "toyota_rav4_hybrid_2017_pt.dbc starts ";
CM_ "toyota_rav4_hybrid_2017_pt.dbc starts h
CM_ "toyota_rav4_hybrid_2017_pt.dbc starts ";
CM_ "toyota_rav4_hybrid_2017_pt.dbc starts h
CM_ "toyota_rav4_hybrid_2017_pt.dbc starts h";
CM_ "toyota_rav4_hybrid_2017_pt.dbc starts he
CM_ "toyota_rav4_hybrid_2017_pt.dbc star";
CM_ "toyota_rav4_hybrid_2017_pt.dbc start
CM_ "toyota_rav4_hybrid_2017_pt.dbc start";
CM_ "toyota_rav4_hybrid_2017_pt.dbc starts
CM_ "toyota_rav4_hybrid_2017_pt.dbc star";
CM_ "toyota_rav4_hybrid_2017_pt.dbc start
CM_ "toyota_rav4_hybrid_2017_pt.dbc start";
CM_ "toyota_rav4_hybrid_2017_pt.dbc starts
CM_ "toyota_rav4_hybrid_2017_pt.dbc start";
CM_ "toyota_rav4_hybrid_2017_pt.dbc starts
CM_ "toyota_rav4_hybrid_2017_pt.dbc start";
CM_ "toyota_rav4_hybrid_2017_pt.dbc starts
CM_ "toyota_rav4_hybrid_2017_pt.dbc starts";
CM_ "toyota_rav4_hybrid_2017_pt.dbc starts
CM_ "toyota_rav4_hybrid_2017_pt.dbc starts ";
CM_ "toyota_rav4_hybrid_2017_pt.dbc starts h
CM_ "toyota_rav4_hybrid_2017_pt.dbc start";
CM_ "toyota_rav4_hybrid_2017_pt.dbc starts
CM_ "toyota_rav4_hybrid_2017_pt.dbc start";
CM_ "toyota_rav4_hybrid_2017_pt.dbc starts
CM_ "toyota_rav4_hybrid_2017_pt.dbc starts";
CM_ "toyota_rav4_hybrid_2017_pt.dbc starts
CM_ "toyota_rav4_hybrid_2017_pt.dbc starts ";
CM_ "toyota_rav4_hybrid_2017_pt.dbc starts h
CM_ "toyota_rav4_hybrid_2017_pt.dbc starts";
CM_ "toyota_rav4_hybrid_2017_pt.dbc starts
CM_ "toyota_rav4_hybrid_2017_pt.dbc starts ";
CM_ "toyota_rav4_hybrid_2017_pt.dbc starts h
CM_ "toyota_rav4_hybrid_2017_pt.dbc starts ";
CM_ "toyota_rav4_hybrid_2017_pt.dbc starts h
CM_ "toyota_rav4_hybrid_2017_pt.dbc starts h";
CM_ "toyota_rav4_hybrid_2017_pt.dbc starts he
CM_ "toyota_rav4_hybrid_2017_pt.dbc start";
CM_ "toyota_rav4_hybrid_2017_pt.dbc starts
CM_ "toyota_rav4_hybrid_2017_pt.dbc start";
CM_ "toyota_rav4_hybrid_2017_pt.dbc starts
CM_ "toyota_rav4_hybrid_2017_pt.dbc starts";
CM_ "toyota_rav4_hybrid_2017_pt.dbc starts
CM_ "toyota_rav4_hybrid_2017_pt.dbc starts ";
CM_ "toyota_rav4_hybrid_2017_pt.dbc starts h
CM_ "toyota_rav4_hybrid_2017_pt.dbc starts";
CM_ "toyota_rav4_hybrid_2017_pt.dbc starts
CM_ "toyota_rav4_hybrid_2017_pt.dbc starts ";
CM_ "toyota_rav4_hybrid_2017_pt.dbc starts h
CM_ "toyota_rav4_hybrid_2017_pt.dbc starts ";
CM_ "toyota_rav4_hybrid_2017_pt.dbc starts h
CM_ "toyota_rav4_hybrid_2017_pt.dbc starts h";
CM_ "toyota_rav4_hybrid_2017_pt.dbc starts he
CM_ "toyota_rav4_hybrid_2017_pt.dbc starts";
CM_ "toyota_rav4_hybrid_2017_pt.dbc starts
CM_ "toyota_rav4_hybrid_2017_pt.dbc starts ";
CM_ "toyota_rav4_hybrid_2017_pt.dbc starts h
CM_ "toyota_rav4_hybrid_2017_pt.dbc starts ";
CM_ "toyota_rav4_hybrid_2017_pt.dbc starts h
CM_ "toyota_rav4_hybrid_2017_pt.dbc starts h";
CM_ "toyota_rav4_hybrid_2017_pt.dbc starts he
CM_ "toyota_rav4_hybrid_2017_pt.dbc starts ";
CM_ "toyota_rav4_hybrid_2017_pt.dbc starts h
CM_ "toyota_rav4_hybrid_2017_pt.dbc starts h";
CM_ "toyota_rav4_hybrid_2017_pt.dbc starts he
CM_ "toyota_rav4_hybrid_2017_pt.dbc starts h";
CM_ "toyota_rav4_hybrid_2017_pt.dbc starts he
CM_ "toyota_rav4_hybrid_2017_pt.dbc starts he";
CM_ "toyota_rav4_hybrid_2017_pt.dbc starts her
CM_ "toyota_rav4_hybrid_2017_pt.dbc sta";
CM_ "toyota_rav4_hybrid_2017_pt.dbc star
CM_ "toyota_rav4_hybrid_2017_pt.dbc star";
CM_ "toyota_rav4_hybrid_2017_pt.dbc start
CM_ "toyota_rav4_hybrid_2017_pt.dbc star";
CM_ "toyota_rav4_hybrid_2017_pt.dbc start
CM_ "toyota_rav4_hybrid_2017_pt.dbc start";
CM_ "toyota_rav4_hybrid_2017_pt.dbc starts
CM_ "toyota_rav4_hybrid_2017_pt.dbc sta";
CM_ "toyota_rav4_hybrid_2017_pt.dbc star
CM_ "toyota_rav4_hybrid_2017_pt.dbc star";
CM_ "toyota_rav4_hybrid_2017_pt.dbc start
CM_ "toyota_rav4_hybrid_2017_pt.dbc star";
CM_ "toyota_rav4_hybrid_2017_pt.dbc start
CM_ "toyota_rav4_hybrid_2017_pt.dbc start";
CM_ "toyota_rav4_hybrid_2017_pt.dbc starts
CM_ "toyota_rav4_hybrid_2017_pt.dbc star";
CM_ "toyota_rav4_hybrid_2017_pt.dbc start
CM_ "toyota_rav4_hybrid_2017_pt.dbc start";
CM_ "toyota_rav4_hybrid_2017_pt.dbc starts
CM_ "toyota_rav4_hybrid_2017_pt.dbc star";
CM_ "toyota_rav4_hybrid_2017_pt.dbc start
CM_ "toyota_rav4_hybrid_2017_pt.dbc start";
CM_ "toyota_rav4_hybrid_2017_pt.dbc starts
CM_ "toyota_rav4_hybrid_2017_pt.dbc start";
CM_ "toyota_rav4_hybrid_2017_pt.dbc starts
CM_ "toyota_rav4_hybrid_2017_pt.dbc start";
CM_ "toyota_rav4_hybrid_2017_pt.dbc starts
CM_ "toyota_rav4_hybrid_2017_pt.dbc starts";
CM_ "toyota_rav4_hybrid_2017_pt.dbc starts
CM_ "toyota_rav4_hybrid_2017_pt.dbc starts ";
CM_ "toyota_rav4_hybrid_2017_pt.dbc starts h
CM_ "toyota_rav4_hybrid_2017_pt.dbc star";
CM_ "toyota_rav4_hybrid_2017_pt.dbc start
CM_ "toyota_rav4_hybrid_2017_pt.dbc start";
CM_ "toyota_rav4_hybrid_2017_pt.dbc starts
CM_ "toyota_rav4_hybrid_2017_pt.dbc star";
CM_ "toyota_rav4_hybrid_2017_pt.dbc start
CM_ "toyota_rav4_hybrid_2017_pt.dbc start";
CM_ "toyota_rav4_hybrid_2017_pt.dbc starts
CM_ "toyota_rav4_hybrid_2017_pt.dbc start";
CM_ "toyota_rav4_hybrid_2017_pt.dbc starts
CM_ "toyota_rav4_hybrid_2017_pt.dbc start";
CM_ "toyota_rav4_hybrid_2017_pt.dbc starts
CM_ "toyota_rav4_hybrid_2017_pt.dbc starts";
CM_ "toyota_rav4_hybrid_2017_pt.dbc starts
CM_ "toyota_rav4_hybrid_2017_pt.dbc starts ";
CM_ "toyota_rav4_hybrid_2017_pt.dbc starts h
CM_ "toyota_rav4_hybrid_2017_pt.dbc start";
CM_ "toyota_rav4_hybrid_2017_pt.dbc starts
CM_ "toyota_rav4_hybrid_2017_pt.dbc start";
CM_ "toyota_rav4_hybrid_2017_pt.dbc starts
CM_ "toyota_rav4_hybrid_2017_pt.dbc starts";
CM_ "toyota_rav4_hybrid_2017_pt.dbc starts
CM_ "toyota_rav4_hybrid_2017_pt.dbc starts ";
CM_ "toyota_rav4_hybrid_2017_pt.dbc starts h
CM_ "toyota_rav4_hybrid_2017_pt.dbc starts";
CM_ "toyota_rav4_hybrid_2017_pt.dbc starts
CM_ "toyota_rav4_hybrid_2017_pt.dbc starts ";
CM_ "toyota_rav4_hybrid_2017_pt.dbc starts h
CM_ "toyota_rav4_hybrid_2017_pt.dbc starts ";
CM_ "toyota_rav4_hybrid_2017_pt.dbc starts h
CM_ "toyota_rav4_hybrid_2017_pt.dbc starts h";
CM_ "toyota_rav4_hybrid_2017_pt.dbc starts he
CM_ "toyota_rav4_hybrid_2017_pt.dbc star";
CM_ "toyota_rav4_hybrid_2017_pt.dbc start
CM_ "toyota_rav4_hybrid_2017_pt.dbc start";
CM_ "toyota_rav4_hybrid_2017_pt.dbc starts
CM_ "toyota_rav4_hybrid_2017_pt.dbc star";
CM_ "toyota_rav4_hybrid_2017_pt.dbc start
CM_ "toyota_rav4_hybrid_2017_pt.dbc start";
CM_ "toyota_rav4_hybrid_2017_pt.dbc starts
CM_ "toyota_rav4_hybrid_2017_pt.dbc start";
CM_ "toyota_rav4_hybrid_2017_pt.dbc starts
CM_ "toyota_rav4_hybrid_2017_pt.dbc start";
CM_ "toyota_rav4_hybrid_2017_pt.dbc starts
CM_ "toyota_rav4_hybrid_2017_pt.dbc starts";
CM_ "toyota_rav4_hybrid_2017_pt.dbc starts
CM_ "toyota_rav4_hybrid_2017_pt.dbc starts ";
CM_ "toyota_rav4_hybrid_2017_pt.dbc starts h
CM_ "toyota_rav4_hybrid_2017_pt.dbc start";
CM_ "toyota_rav4_hybrid_2017_pt.dbc starts
CM_ "toyota_rav4_hybrid_2017_pt.dbc start";
CM_ "toyota_rav4_hybrid_2017_pt.dbc starts
CM_ "toyota_rav4_hybrid_2017_pt.dbc starts";
CM_ "toyota_rav4_hybrid_2017_pt.dbc starts
CM_ "toyota_rav4_hybrid_2017_pt.dbc starts ";
CM_ "toyota_rav4_hybrid_2017_pt.dbc starts h
CM_ "toyota_rav4_hybrid_2017_pt.dbc starts";
CM_ "toyota_rav4_hybrid_2017_pt.dbc starts
CM_ "toyota_rav4_hybrid_2017_pt.dbc starts ";
CM_ "toyota_rav4_hybrid_2017_pt.dbc starts h
CM_ "toyota_rav4_hybrid_2017_pt.dbc starts ";
CM_ "toyota_rav4_hybrid_2017_pt.dbc starts h
CM_ "toyota_rav4_hybrid_2017_pt.dbc starts h";
CM_ "toyota_rav4_hybrid_2017_pt.dbc starts he
CM_ "toyota_rav4_hybrid_2017_pt.dbc start";
CM_ "toyota_rav4_hybrid_2017_pt.dbc starts
CM_ "toyota_rav4_hybrid_2017_pt.dbc start";
CM_ "toyota_rav4_hybrid_2017_pt.dbc starts
CM_ "toyota_rav4_hybrid_2017_pt.dbc starts";
CM_ "toyota_rav4_hybrid_2017_pt.dbc starts
CM_ "toyota_rav4_hybrid_2017_pt.dbc starts ";
CM_ "toyota_rav4_hybrid_2017_pt.dbc starts h
CM_ "toyota_rav4_hybrid_2017_pt.dbc starts";
CM_ "toyota_rav4_hybrid_2017_pt.dbc starts
CM_ "toyota_rav4_hybrid_2017_pt.dbc starts ";
CM_ "toyota_rav4_hybrid_2017_pt.dbc starts h
CM_ "toyota_rav4_hybrid_2017_pt.dbc starts ";
CM_ "toyota_rav4_hybrid_2017_pt.dbc starts h
CM_ "toyota_rav4_hybrid_2017_pt.dbc starts h";
CM_ "toyota_rav4_hybrid_2017_pt.dbc starts he
CM_ "toyota_rav4_hybrid_2017_pt.dbc starts";
CM_ "toyota_rav4_hybrid_2017_pt.dbc starts
CM_ "toyota_rav4_hybrid_2017_pt.dbc starts ";
CM_ "toyota_rav4_hybrid_2017_pt.dbc starts h
CM_ "toyota_rav4_hybrid_2017_pt.dbc starts ";
CM_ "toyota_rav4_hybrid_2017_pt.dbc starts h
CM_ "toyota_rav4_hybrid_2017_pt.dbc starts h";
CM_ "toyota_rav4_hybrid_2017_pt.dbc starts he
CM_ "toyota_rav4_hybrid_2017_pt.dbc starts ";
CM_ "toyota_rav4_hybrid_2017_pt.dbc starts h
CM_ "toyota_rav4_hybrid_2017_pt.dbc starts h";
CM_ "toyota_rav4_hybrid_2017_pt.dbc starts he
CM_ "toyota_rav4_hybrid_2017_pt.dbc starts h";
CM_ "toyota_rav4_hybrid_2017_pt.dbc starts he
CM_ "toyota_rav4_hybrid_2017_pt.dbc starts he";
CM_ "toyota_rav4_hybrid_2017_pt.dbc starts her
CM_ "toyota_rav4_hybrid_2017_pt.dbc star";
CM_ "toyota_rav4_hybrid_2017_pt.dbc start
CM_ "toyota_rav4_hybrid_2017_pt.dbc start";
CM_ "toyota_rav4_hybrid_2017_pt.dbc starts
CM_ "toyota_rav4_hybrid_2017_pt.dbc star";
CM_ "toyota_rav4_hybrid_2017_pt.dbc start
CM_ "toyota_rav4_hybrid_2017_pt.dbc start";
CM_ "toyota_rav4_hybrid_2017_pt.dbc starts
CM_ "toyota_rav4_hybrid_2017_pt.dbc start";
CM_ "toyota_rav4_hybrid_2017_pt.dbc starts
CM_ "toyota_rav4_hybrid_2017_pt.dbc start";
CM_ "toyota_rav4_hybrid_2017_pt.dbc starts
CM_ "toyota_rav4_hybrid_2017_pt.dbc starts";
CM_ "toyota_rav4_hybrid_2017_pt.dbc starts
CM_ "toyota_rav4_hybrid_2017_pt.dbc starts ";
CM_ "toyota_rav4_hybrid_2017_pt.dbc starts h
CM_ "toyota_rav4_hybrid_2017_pt.dbc start";
CM_ "toyota_rav4_hybrid_2017_pt.dbc starts
CM_ "toyota_rav4_hybrid_2017_pt.dbc start";
CM_ "toyota_rav4_hybrid_2017_pt.dbc starts
CM_ "toyota_rav4_hybrid_2017_pt.dbc starts";
CM_ "toyota_rav4_hybrid_2017_pt.dbc starts
CM_ "toyota_rav4_hybrid_2017_pt.dbc starts ";
CM_ "toyota_rav4_hybrid_2017_pt.dbc starts h
CM_ "toyota_rav4_hybrid_2017_pt.dbc starts";
CM_ "toyota_rav4_hybrid_2017_pt.dbc starts
CM_ "toyota_rav4_hybrid_2017_pt.dbc starts ";
CM_ "toyota_rav4_hybrid_2017_pt.dbc starts h
CM_ "toyota_rav4_hybrid_2017_pt.dbc starts ";
CM_ "toyota_rav4_hybrid_2017_pt.dbc starts h
CM_ "toyota_rav4_hybrid_2017_pt.dbc starts h";
CM_ "toyota_rav4_hybrid_2017_pt.dbc starts he
CM_ "toyota_rav4_hybrid_2017_pt.dbc start";
CM_ "toyota_rav4_hybrid_2017_pt.dbc starts
CM_ "toyota_rav4_hybrid_2017_pt.dbc start";
CM_ "toyota_rav4_hybrid_2017_pt.dbc starts
CM_ "toyota_rav4_hybrid_2017_pt.dbc starts";
CM_ "toyota_rav4_hybrid_2017_pt.dbc starts
CM_ "toyota_rav4_hybrid_2017_pt.dbc starts ";
CM_ "toyota_rav4_hybrid_2017_pt.dbc starts h
CM_ "toyota_rav4_hybrid_2017_pt.dbc starts";
CM_ "toyota_rav4_hybrid_2017_pt.dbc starts
CM_ "toyota_rav4_hybrid_2017_pt.dbc starts ";
CM_ "toyota_rav4_hybrid_2017_pt.dbc starts h
CM_ "toyota_rav4_hybrid_2017_pt.dbc starts ";
CM_ "toyota_rav4_hybrid_2017_pt.dbc starts h
CM_ "toyota_rav4_hybrid_2017_pt.dbc starts h";
CM_ "toyota_rav4_hybrid_2017_pt.dbc starts he
CM_ "toyota_rav4_hybrid_2017_pt.dbc starts";
CM_ "toyota_rav4_hybrid_2017_pt.dbc starts
CM_ "toyota_rav4_hybrid_2017_pt.dbc starts ";
CM_ "toyota_rav4_hybrid_2017_pt.dbc starts h
CM_ "toyota_rav4_hybrid_2017_pt.dbc starts ";
CM_ "toyota_rav4_hybrid_2017_pt.dbc starts h
CM_ "toyota_rav4_hybrid_2017_pt.dbc starts h";
CM_ "toyota_rav4_hybrid_2017_pt.dbc starts he
CM_ "toyota_rav4_hybrid_2017_pt.dbc starts ";
CM_ "toyota_rav4_hybrid_2017_pt.dbc starts h
CM_ "toyota_rav4_hybrid_2017_pt.dbc starts h";
CM_ "toyota_rav4_hybrid_2017_pt.dbc starts he
CM_ "toyota_rav4_hybrid_2017_pt.dbc starts h";
CM_ "toyota_rav4_hybrid_2017_pt.dbc starts he
CM_ "toyota_rav4_hybrid_2017_pt.dbc starts he";
CM_ "toyota_rav4_hybrid_2017_pt.dbc starts her
CM_ "toyota_rav4_hybrid_2017_pt.dbc start";
CM_ "toyota_rav4_hybrid_2017_pt.dbc starts
CM_ "toyota_rav4_hybrid_2017_pt.dbc start";
CM_ "toyota_rav4_hybrid_2017_pt.dbc starts
CM_ "toyota_rav4_hybrid_2017_pt.dbc starts";
CM_ "toyota_rav4_hybrid_2017_pt.dbc starts
CM_ "toyota_rav4_hybrid_2017_pt.dbc starts ";
CM_ "toyota_rav4_hybrid_2017_pt.dbc starts h
CM_ "toyota_rav4_hybrid_2017_pt.dbc starts";
CM_ "toyota_rav4_hybrid_2017_pt.dbc starts
CM_ "toyota_rav4_hybrid_2017_pt.dbc starts ";
CM_ "toyota_rav4_hybrid_2017_pt.dbc starts h
CM_ "toyota_rav4_hybrid_2017_pt.dbc starts ";
CM_ "toyota_rav4_hybrid_2017_pt.dbc starts h
CM_ "toyota_rav4_hybrid_2017_pt.dbc starts h";
CM_ "toyota_rav4_hybrid_2017_pt.dbc starts he
CM_ "toyota_rav4_hybrid_2017_pt.dbc starts";
CM_ "toyota_rav4_hybrid_2017_pt.dbc starts
CM_ "toyota_rav4_hybrid_2017_pt.dbc starts ";
CM_ "toyota_rav4_hybrid_2017_pt.dbc starts h
CM_ "toyota_rav4_hybrid_2017_pt.dbc starts ";
CM_ "toyota_rav4_hybrid_2017_pt.dbc starts h
CM_ "toyota_rav4_hybrid_2017_pt.dbc starts h";
CM_ "toyota_rav4_hybrid_2017_pt.dbc starts he
CM_ "toyota_rav4_hybrid_2017_pt.dbc starts ";
CM_ "toyota_rav4_hybrid_2017_pt.dbc starts h
CM_ "toyota_rav4_hybrid_2017_pt.dbc starts h";
CM_ "toyota_rav4_hybrid_2017_pt.dbc starts he
CM_ "toyota_rav4_hybrid_2017_pt.dbc starts h";
CM_ "toyota_rav4_hybrid_2017_pt.dbc starts he
CM_ "toyota_rav4_hybrid_2017_pt.dbc starts he";
CM_ "toyota_rav4_hybrid_2017_pt.dbc starts her
CM_ "toyota_rav4_hybrid_2017_pt.dbc starts";
CM_ "toyota_rav4_hybrid_2017_pt.dbc starts
CM_ "toyota_rav4_hybrid_2017_pt.dbc starts ";
CM_ "toyota_rav4_hybrid_2017_pt.dbc starts h
CM_ "toyota_rav4_hybrid_2017_pt.dbc starts ";
CM_ "toyota_rav4_hybrid_2017_pt.dbc starts h
CM_ "toyota_rav4_hybrid_2017_pt.dbc starts h";
CM_ "toyota_rav4_hybrid_2017_pt.dbc starts he
CM_ "toyota_rav4_hybrid_2017_pt.dbc starts ";
CM_ "toyota_rav4_hybrid_2017_pt.dbc starts h
CM_ "toyota_rav4_hybrid_2017_pt.dbc starts h";
CM_ "toyota_rav4_hybrid_2017_pt.dbc starts he
CM_ "toyota_rav4_hybrid_2017_pt.dbc starts h";
CM_ "toyota_rav4_hybrid_2017_pt.dbc starts he
CM_ "toyota_rav4_hybrid_2017_pt.dbc starts he";
CM_ "toyota_rav4_hybrid_2017_pt.dbc starts her
CM_ "toyota_rav4_hybrid_2017_pt.dbc starts ";
CM_ "toyota_rav4_hybrid_2017_pt.dbc starts h
CM_ "toyota_rav4_hybrid_2017_pt.dbc starts h";
CM_ "toyota_rav4_hybrid_2017_pt.dbc starts he
CM_ "toyota_rav4_hybrid_2017_pt.dbc starts h";
CM_ "toyota_rav4_hybrid_2017_pt.dbc starts he
CM_ "toyota_rav4_hybrid_2017_pt.dbc starts he";
CM_ "toyota_rav4_hybrid_2017_pt.dbc starts her
CM_ "toyota_rav4_hybrid_2017_pt.dbc starts h";
CM_ "toyota_rav4_hybrid_2017_pt.dbc starts he
CM_ "toyota_rav4_hybrid_2017_pt.dbc starts he";
CM_ "toyota_rav4_hybrid_2017_pt.dbc starts her
CM_ "toyota_rav4_hybrid_2017_pt.dbc starts he";
CM_ "toyota_rav4_hybrid_2017_pt.dbc starts her
CM_ "toyota_rav4_hybrid_2017_pt.dbc starts her";
CM_ "toyota_rav4_hybrid_2017_pt.dbc starts here
CM_ "toyota_rav4_hybrid_2017_pt.dbc sta";
CM_ "toyota_rav4_hybrid_2017_pt.dbc star
CM_ "toyota_rav4_hybrid_2017_pt.dbc star";
CM_ "toyota_rav4_hybrid_2017_pt.dbc start
CM_ "toyota_rav4_hybrid_2017_pt.dbc star";
CM_ "toyota_rav4_hybrid_2017_pt.dbc start
CM_ "toyota_rav4_hybrid_2017_pt.dbc start";
CM_ "toyota_rav4_hybrid_2017_pt.dbc starts
CM_ "toyota_rav4_hybrid_2017_pt.dbc sta";
CM_ "toyota_rav4_hybrid_2017_pt.dbc star
CM_ "toyota_rav4_hybrid_2017_pt.dbc star";
CM_ "toyota_rav4_hybrid_2017_pt.dbc start
CM_ "toyota_rav4_hybrid_2017_pt.dbc star";
CM_ "toyota_rav4_hybrid_2017_pt.dbc start
CM_ "toyota_rav4_hybrid_2017_pt.dbc start";
CM_ "toyota_rav4_hybrid_2017_pt.dbc starts
CM_ "toyota_rav4_hybrid_2017_pt.dbc star";
CM_ "toyota_rav4_hybrid_2017_pt.dbc start
CM_ "toyota_rav4_hybrid_2017_pt.dbc start";
CM_ "toyota_rav4_hybrid_2017_pt.dbc starts
CM_ "toyota_rav4_hybrid_2017_pt.dbc star";
CM_ "toyota_rav4_hybrid_2017_pt.dbc start
CM_ "toyota_rav4_hybrid_2017_pt.dbc start";
CM_ "toyota_rav4_hybrid_2017_pt.dbc starts
CM_ "toyota_rav4_hybrid_2017_pt.dbc start";
CM_ "toyota_rav4_hybrid_2017_pt.dbc starts
CM_ "toyota_rav4_hybrid_2017_pt.dbc start";
CM_ "toyota_rav4_hybrid_2017_pt.dbc starts
CM_ "toyota_rav4_hybrid_2017_pt.dbc starts";
CM_ "toyota_rav4_hybrid_2017_pt.dbc starts
CM_ "toyota_rav4_hybrid_2017_pt.dbc starts ";
CM_ "toyota_rav4_hybrid_2017_pt.dbc starts h
CM_ "toyota_rav4_hybrid_2017_pt.dbc star";
CM_ "toyota_rav4_hybrid_2017_pt.dbc start
CM_ "toyota_rav4_hybrid_2017_pt.dbc start";
CM_ "toyota_rav4_hybrid_2017_pt.dbc starts
CM_ "toyota_rav4_hybrid_2017_pt.dbc star";
CM_ "toyota_rav4_hybrid_2017_pt.dbc start
CM_ "toyota_rav4_hybrid_2017_pt.dbc start";
CM_ "toyota_rav4_hybrid_2017_pt.dbc starts
CM_ "toyota_rav4_hybrid_2017_pt.dbc start";
CM_ "toyota_rav4_hybrid_2017_pt.dbc starts
CM_ "toyota_rav4_hybrid_2017_pt.dbc start";
CM_ "toyota_rav4_hybrid_2017_pt.dbc starts
CM_ "toyota_rav4_hybrid_2017_pt.dbc starts";
CM_ "toyota_rav4_hybrid_2017_pt.dbc starts
CM_ "toyota_rav4_hybrid_2017_pt.dbc starts ";
CM_ "toyota_rav4_hybrid_2017_pt.dbc starts h
CM_ "toyota_rav4_hybrid_2017_pt.dbc start";
CM_ "toyota_rav4_hybrid_2017_pt.dbc starts
CM_ "toyota_rav4_hybrid_2017_pt.dbc start";
CM_ "toyota_rav4_hybrid_2017_pt.dbc starts
CM_ "toyota_rav4_hybrid_2017_pt.dbc starts";
CM_ "toyota_rav4_hybrid_2017_pt.dbc starts
CM_ "toyota_rav4_hybrid_2017_pt.dbc starts ";
CM_ "toyota_rav4_hybrid_2017_pt.dbc starts h
CM_ "toyota_rav4_hybrid_2017_pt.dbc starts";
CM_ "toyota_rav4_hybrid_2017_pt.dbc starts
CM_ "toyota_rav4_hybrid_2017_pt.dbc starts ";
CM_ "toyota_rav4_hybrid_2017_pt.dbc starts h
CM_ "toyota_rav4_hybrid_2017_pt.dbc starts ";
CM_ "toyota_rav4_hybrid_2017_pt.dbc starts h
CM_ "toyota_rav4_hybrid_2017_pt.dbc starts h";
CM_ "toyota_rav4_hybrid_2017_pt.dbc starts he
CM_ "toyota_rav4_hybrid_2017_pt.dbc star";
CM_ "toyota_rav4_hybrid_2017_pt.dbc start
CM_ "toyota_rav4_hybrid_2017_pt.dbc start";
CM_ "toyota_rav4_hybrid_2017_pt.dbc starts
CM_ "toyota_rav4_hybrid_2017_pt.dbc star";
CM_ "toyota_rav4_hybrid_2017_pt.dbc start
CM_ "toyota_rav4_hybrid_2017_pt.dbc start";
CM_ "toyota_rav4_hybrid_2017_pt.dbc starts
CM_ "toyota_rav4_hybrid_2017_pt.dbc start";
CM_ "toyota_rav4_hybrid_2017_pt.dbc starts
CM_ "toyota_rav4_hybrid_2017_pt.dbc start";
CM_ "toyota_rav4_hybrid_2017_pt.dbc starts
CM_ "toyota_rav4_hybrid_2017_pt.dbc starts";
CM_ "toyota_rav4_hybrid_2017_pt.dbc starts
CM_ "toyota_rav4_hybrid_2017_pt.dbc starts ";
CM_ "toyota_rav4_hybrid_2017_pt.dbc starts h
CM_ "toyota_rav4_hybrid_2017_pt.dbc start";
CM_ "toyota_rav4_hybrid_2017_pt.dbc starts
CM_ "toyota_rav4_hybrid_2017_pt.dbc start";
CM_ "toyota_rav4_hybrid_2017_pt.dbc starts
CM_ "toyota_rav4_hybrid_2017_pt.dbc starts";
CM_ "toyota_rav4_hybrid_2017_pt.dbc starts
CM_ "toyota_rav4_hybrid_2017_pt.dbc starts ";
CM_ "toyota_rav4_hybrid_2017_pt.dbc starts h
CM_ "toyota_rav4_hybrid_2017_pt.dbc starts";
CM_ "toyota_rav4_hybrid_2017_pt.dbc starts
CM_ "toyota_rav4_hybrid_2017_pt.dbc starts ";
CM_ "toyota_rav4_hybrid_2017_pt.dbc starts h
CM_ "toyota_rav4_hybrid_2017_pt.dbc starts ";
CM_ "toyota_rav4_hybrid_2017_pt.dbc starts h
CM_ "toyota_rav4_hybrid_2017_pt.dbc starts h";
CM_ "toyota_rav4_hybrid_2017_pt.dbc starts he
CM_ "toyota_rav4_hybrid_2017_pt.dbc start";
CM_ "toyota_rav4_hybrid_2017_pt.dbc starts
CM_ "toyota_rav4_hybrid_2017_pt.dbc start";
CM_ "toyota_rav4_hybrid_2017_pt.dbc starts
CM_ "toyota_rav4_hybrid_2017_pt.dbc starts";
CM_ "toyota_rav4_hybrid_2017_pt.dbc starts
CM_ "toyota_rav4_hybrid_2017_pt.dbc starts ";
CM_ "toyota_rav4_hybrid_2017_pt.dbc starts h
CM_ "toyota_rav4_hybrid_2017_pt.dbc starts";
CM_ "toyota_rav4_hybrid_2017_pt.dbc starts
CM_ "toyota_rav4_hybrid_2017_pt.dbc starts ";
CM_ "toyota_rav4_hybrid_2017_pt.dbc starts h
CM_ "toyota_rav4_hybrid_2017_pt.dbc starts ";
CM_ "toyota_rav4_hybrid_2017_pt.dbc starts h
CM_ "toyota_rav4_hybrid_2017_pt.dbc starts h";
CM_ "toyota_rav4_hybrid_2017_pt.dbc starts he
CM_ "toyota_rav4_hybrid_2017_pt.dbc starts";
CM_ "toyota_rav4_hybrid_2017_pt.dbc starts
CM_ "toyota_rav4_hybrid_2017_pt.dbc starts ";
CM_ "toyota_rav4_hybrid_2017_pt.dbc starts h
CM_ "toyota_rav4_hybrid_2017_pt.dbc starts ";
CM_ "toyota_rav4_hybrid_2017_pt.dbc starts h
CM_ "toyota_rav4_hybrid_2017_pt.dbc starts h";
CM_ "toyota_rav4_hybrid_2017_pt.dbc starts he
CM_ "toyota_rav4_hybrid_2017_pt.dbc starts ";
CM_ "toyota_rav4_hybrid_2017_pt.dbc starts h
CM_ "toyota_rav4_hybrid_2017_pt.dbc starts h";
CM_ "toyota_rav4_hybrid_2017_pt.dbc starts he
CM_ "toyota_rav4_hybrid_2017_pt.dbc starts h";
CM_ "toyota_rav4_hybrid_2017_pt.dbc starts he
CM_ "toyota_rav4_hybrid_2017_pt.dbc starts he";
CM_ "toyota_rav4_hybrid_2017_pt.dbc starts her
CM_ "toyota_rav4_hybrid_2017_pt.dbc star";
CM_ "toyota_rav4_hybrid_2017_pt.dbc start
CM_ "toyota_rav4_hybrid_2017_pt.dbc start";
CM_ "toyota_rav4_hybrid_2017_pt.dbc starts
CM_ "toyota_rav4_hybrid_2017_pt.dbc star";
CM_ "toyota_rav4_hybrid_2017_pt.dbc start
CM_ "toyota_rav4_hybrid_2017_pt.dbc start";
CM_ "toyota_rav4_hybrid_2017_pt.dbc starts
CM_ "toyota_rav4_hybrid_2017_pt.dbc start";
CM_ "toyota_rav4_hybrid_2017_pt.dbc starts
CM_ "toyota_rav4_hybrid_2017_pt.dbc start";
CM_ "toyota_rav4_hybrid_2017_pt.dbc starts
CM_ "toyota_rav4_hybrid_2017_pt.dbc starts";
CM_ "toyota_rav4_hybrid_2017_pt.dbc starts
CM_ "toyota_rav4_hybrid_2017_pt.dbc starts ";
CM_ "toyota_rav4_hybrid_2017_pt.dbc starts h
CM_ "toyota_rav4_hybrid_2017_pt.dbc start";
CM_ "toyota_rav4_hybrid_2017_pt.dbc starts
CM_ "toyota_rav4_hybrid_2017_pt.dbc start";
CM_ "toyota_rav4_hybrid_2017_pt.dbc starts
CM_ "toyota_rav4_hybrid_2017_pt.dbc starts";
CM_ "toyota_rav4_hybrid_2017_pt.dbc starts
CM_ "toyota_rav4_hybrid_2017_pt.dbc starts ";
CM_ "toyota_rav4_hybrid_2017_pt.dbc starts h
CM_ "toyota_rav4_hybrid_2017_pt.dbc starts";
CM_ "toyota_rav4_hybrid_2017_pt.dbc starts
CM_ "toyota_rav4_hybrid_2017_pt.dbc starts ";
CM_ "toyota_rav4_hybrid_2017_pt.dbc starts h
CM_ "toyota_rav4_hybrid_2017_pt.dbc starts ";
CM_ "toyota_rav4_hybrid_2017_pt.dbc starts h
CM_ "toyota_rav4_hybrid_2017_pt.dbc starts h";
CM_ "toyota_rav4_hybrid_2017_pt.dbc starts he
CM_ "toyota_rav4_hybrid_2017_pt.dbc start";
CM_ "toyota_rav4_hybrid_2017_pt.dbc starts
CM_ "toyota_rav4_hybrid_2017_pt.dbc start";
CM_ "toyota_rav4_hybrid_2017_pt.dbc starts
CM_ "toyota_rav4_hybrid_2017_pt.dbc starts";
CM_ "toyota_rav4_hybrid_2017_pt.dbc starts
CM_ "toyota_rav4_hybrid_2017_pt.dbc starts ";
CM_ "toyota_rav4_hybrid_2017_pt.dbc starts h
CM_ "toyota_rav4_hybrid_2017_pt.dbc starts";
CM_ "toyota_rav4_hybrid_2017_pt.dbc starts
CM_ "toyota_rav4_hybrid_2017_pt.dbc starts ";
CM_ "toyota_rav4_hybrid_2017_pt.dbc starts h
CM_ "toyota_rav4_hybrid_2017_pt.dbc starts ";
CM_ "toyota_rav4_hybrid_2017_pt.dbc starts h
CM_ "toyota_rav4_hybrid_2017_pt.dbc starts h";
CM_ "toyota_rav4_hybrid_2017_pt.dbc starts he
CM_ "toyota_rav4_hybrid_2017_pt.dbc starts";
CM_ "toyota_rav4_hybrid_2017_pt.dbc starts
CM_ "toyota_rav4_hybrid_2017_pt.dbc starts ";
CM_ "toyota_rav4_hybrid_2017_pt.dbc starts h
CM_ "toyota_rav4_hybrid_2017_pt.dbc starts ";
CM_ "toyota_rav4_hybrid_2017_pt.dbc starts h
CM_ "toyota_rav4_hybrid_2017_pt.dbc starts h";
CM_ "toyota_rav4_hybrid_2017_pt.dbc starts he
CM_ "toyota_rav4_hybrid_2017_pt.dbc starts ";
CM_ "toyota_rav4_hybrid_2017_pt.dbc starts h
CM_ "toyota_rav4_hybrid_2017_pt.dbc starts h";
CM_ "toyota_rav4_hybrid_2017_pt.dbc starts he
CM_ "toyota_rav4_hybrid_2017_pt.dbc starts h";
CM_ "toyota_rav4_hybrid_2017_pt.dbc starts he
CM_ "toyota_rav4_hybrid_2017_pt.dbc starts he";
CM_ "toyota_rav4_hybrid_2017_pt.dbc starts her
CM_ "toyota_rav4_hybrid_2017_pt.dbc start";
CM_ "toyota_rav4_hybrid_2017_pt.dbc starts
CM_ "toyota_rav4_hybrid_2017_pt.dbc start";
CM_ "toyota_rav4_hybrid_2017_pt.dbc starts
CM_ "toyota_rav4_hybrid_2017_pt.dbc starts";
CM_ "toyota_rav4_hybrid_2017_pt.dbc starts
CM_ "toyota_rav4_hybrid_2017_pt.dbc starts ";
CM_ "toyota_rav4_hybrid_2017_pt.dbc starts h
CM_ "toyota_rav4_hybrid_2017_pt.dbc starts";
CM_ "toyota_rav4_hybrid_2017_pt.dbc starts
CM_ "toyota_rav4_hybrid_2017_pt.dbc starts ";
CM_ "toyota_rav4_hybrid_2017_pt.dbc starts h
CM_ "toyota_rav4_hybrid_2017_pt.dbc starts ";
CM_ "toyota_rav4_hybrid_2017_pt.dbc starts h
CM_ "toyota_rav4_hybrid_2017_pt.dbc starts h";
CM_ "toyota_rav4_hybrid_2017_pt.dbc starts he
CM_ "toyota_rav4_hybrid_2017_pt.dbc starts";
CM_ "toyota_rav4_hybrid_2017_pt.dbc starts
CM_ "toyota_rav4_hybrid_2017_pt.dbc starts ";
CM_ "toyota_rav4_hybrid_2017_pt.dbc starts h
CM_ "toyota_rav4_hybrid_2017_pt.dbc starts ";
CM_ "toyota_rav4_hybrid_2017_pt.dbc starts h
CM_ "toyota_rav4_hybrid_2017_pt.dbc starts h";
CM_ "toyota_rav4_hybrid_2017_pt.dbc starts he
CM_ "toyota_rav4_hybrid_2017_pt.dbc starts ";
CM_ "toyota_rav4_hybrid_2017_pt.dbc starts h
CM_ "toyota_rav4_hybrid_2017_pt.dbc starts h";
CM_ "toyota_rav4_hybrid_2017_pt.dbc starts he
CM_ "toyota_rav4_hybrid_2017_pt.dbc starts h";
CM_ "toyota_rav4_hybrid_2017_pt.dbc starts he
CM_ "toyota_rav4_hybrid_2017_pt.dbc starts he";
CM_ "toyota_rav4_hybrid_2017_pt.dbc starts her
CM_ "toyota_rav4_hybrid_2017_pt.dbc starts";
CM_ "toyota_rav4_hybrid_2017_pt.dbc starts
CM_ "toyota_rav4_hybrid_2017_pt.dbc starts ";
CM_ "toyota_rav4_hybrid_2017_pt.dbc starts h
CM_ "toyota_rav4_hybrid_2017_pt.dbc starts ";
CM_ "toyota_rav4_hybrid_2017_pt.dbc starts h
CM_ "toyota_rav4_hybrid_2017_pt.dbc starts h";
CM_ "toyota_rav4_hybrid_2017_pt.dbc starts he
CM_ "toyota_rav4_hybrid_2017_pt.dbc starts ";
CM_ "toyota_rav4_hybrid_2017_pt.dbc starts h
CM_ "toyota_rav4_hybrid_2017_pt.dbc starts h";
CM_ "toyota_rav4_hybrid_2017_pt.dbc starts he
CM_ "toyota_rav4_hybrid_2017_pt.dbc starts h";
CM_ "toyota_rav4_hybrid_2017_pt.dbc starts he
CM_ "toyota_rav4_hybrid_2017_pt.dbc starts he";
CM_ "toyota_rav4_hybrid_2017_pt.dbc starts her
CM_ "toyota_rav4_hybrid_2017_pt.dbc starts ";
CM_ "toyota_rav4_hybrid_2017_pt.dbc starts h
CM_ "toyota_rav4_hybrid_2017_pt.dbc starts h";
CM_ "toyota_rav4_hybrid_2017_pt.dbc starts he
CM_ "toyota_rav4_hybrid_2017_pt.dbc starts h";
CM_ "toyota_rav4_hybrid_2017_pt.dbc starts he
CM_ "toyota_rav4_hybrid_2017_pt.dbc starts he";
CM_ "toyota_rav4_hybrid_2017_pt.dbc starts her
CM_ "toyota_rav4_hybrid_2017_pt.dbc starts h";
CM_ "toyota_rav4_hybrid_2017_pt.dbc starts he
CM_ "toyota_rav4_hybrid_2017_pt.dbc starts he";
CM_ "toyota_rav4_hybrid_2017_pt.dbc starts her
CM_ "toyota_rav4_hybrid_2017_pt.dbc starts he";
CM_ "toyota_rav4_hybrid_2017_pt.dbc starts her
CM_ "toyota_rav4_hybrid_2017_pt.dbc starts her";
CM_ "toyota_rav4_hybrid_2017_pt.dbc starts here
CM_ "toyota_rav4_hybrid_2017_pt.dbc star";
CM_ "toyota_rav4_hybrid_2017_pt.dbc start
CM_ "toyota_rav4_hybrid_2017_pt.dbc start";
CM_ "toyota_rav4_hybrid_2017_pt.dbc starts
CM_ "toyota_rav4_hybrid_2017_pt.dbc star";
CM_ "toyota_rav4_hybrid_2017_pt.dbc start
CM_ "toyota_rav4_hybrid_2017_pt.dbc start";
CM_ "toyota_rav4_hybrid_2017_pt.dbc starts
CM_ "toyota_rav4_hybrid_2017_pt.dbc start";
CM_ "toyota_rav4_hybrid_2017_pt.dbc starts
CM_ "toyota_rav4_hybrid_2017_pt.dbc start";
CM_ "toyota_rav4_hybrid_2017_pt.dbc starts
CM_ "toyota_rav4_hybrid_2017_pt.dbc starts";
CM_ "toyota_rav4_hybrid_2017_pt.dbc starts
CM_ "toyota_rav4_hybrid_2017_pt.dbc starts ";
CM_ "toyota_rav4_hybrid_2017_pt.dbc starts h
CM_ "toyota_rav4_hybrid_2017_pt.dbc start";
CM_ "toyota_rav4_hybrid_2017_pt.dbc starts
CM_ "toyota_rav4_hybrid_2017_pt.dbc start";
CM_ "toyota_rav4_hybrid_2017_pt.dbc starts
CM_ "toyota_rav4_hybrid_2017_pt.dbc starts";
CM_ "toyota_rav4_hybrid_2017_pt.dbc starts
CM_ "toyota_rav4_hybrid_2017_pt.dbc starts ";
CM_ "toyota_rav4_hybrid_2017_pt.dbc starts h
CM_ "toyota_rav4_hybrid_2017_pt.dbc starts";
CM_ "toyota_rav4_hybrid_2017_pt.dbc starts
CM_ "toyota_rav4_hybrid_2017_pt.dbc starts ";
CM_ "toyota_rav4_hybrid_2017_pt.dbc starts h
CM_ "toyota_rav4_hybrid_2017_pt.dbc starts ";
CM_ "toyota_rav4_hybrid_2017_pt.dbc starts h
CM_ "toyota_rav4_hybrid_2017_pt.dbc starts h";
CM_ "toyota_rav4_hybrid_2017_pt.dbc starts he
CM_ "toyota_rav4_hybrid_2017_pt.dbc start";
CM_ "toyota_rav4_hybrid_2017_pt.dbc starts
CM_ "toyota_rav4_hybrid_2017_pt.dbc start";
CM_ "toyota_rav4_hybrid_2017_pt.dbc starts
CM_ "toyota_rav4_hybrid_2017_pt.dbc starts";
CM_ "toyota_rav4_hybrid_2017_pt.dbc starts
CM_ "toyota_rav4_hybrid_2017_pt.dbc starts ";
CM_ "toyota_rav4_hybrid_2017_pt.dbc starts h
CM_ "toyota_rav4_hybrid_2017_pt.dbc starts";
CM_ "toyota_rav4_hybrid_2017_pt.dbc starts
CM_ "toyota_rav4_hybrid_2017_pt.dbc starts ";
CM_ "toyota_rav4_hybrid_2017_pt.dbc starts h
CM_ "toyota_rav4_hybrid_2017_pt.dbc starts ";
CM_ "toyota_rav4_hybrid_2017_pt.dbc starts h
CM_ "toyota_rav4_hybrid_2017_pt.dbc starts h";
CM_ "toyota_rav4_hybrid_2017_pt.dbc starts he
CM_ "toyota_rav4_hybrid_2017_pt.dbc starts";
CM_ "toyota_rav4_hybrid_2017_pt.dbc starts
CM_ "toyota_rav4_hybrid_2017_pt.dbc starts ";
CM_ "toyota_rav4_hybrid_2017_pt.dbc starts h
CM_ "toyota_rav4_hybrid_2017_pt.dbc starts ";
CM_ "toyota_rav4_hybrid_2017_pt.dbc starts h
CM_ "toyota_rav4_hybrid_2017_pt.dbc starts h";
CM_ "toyota_rav4_hybrid_2017_pt.dbc starts he
CM_ "toyota_rav4_hybrid_2017_pt.dbc starts ";
CM_ "toyota_rav4_hybrid_2017_pt.dbc starts h
CM_ "toyota_rav4_hybrid_2017_pt.dbc starts h";
CM_ "toyota_rav4_hybrid_2017_pt.dbc starts he
CM_ "toyota_rav4_hybrid_2017_pt.dbc starts h";
CM_ "toyota_rav4_hybrid_2017_pt.dbc starts he
CM_ "toyota_rav4_hybrid_2017_pt.dbc starts he";
CM_ "toyota_rav4_hybrid_2017_pt.dbc starts her
CM_ "toyota_rav4_hybrid_2017_pt.dbc start";
CM_ "toyota_rav4_hybrid_2017_pt.dbc starts
CM_ "toyota_rav4_hybrid_2017_pt.dbc start";
CM_ "toyota_rav4_hybrid_2017_pt.dbc starts
CM_ "toyota_rav4_hybrid_2017_pt.dbc starts";
CM_ "toyota_rav4_hybrid_2017_pt.dbc starts
CM_ "toyota_rav4_hybrid_2017_pt.dbc starts ";
CM_ "toyota_rav4_hybrid_2017_pt.dbc starts h
CM_ "toyota_rav4_hybrid_2017_pt.dbc starts";
CM_ "toyota_rav4_hybrid_2017_pt.dbc starts
CM_ "toyota_rav4_hybrid_2017_pt.dbc starts ";
CM_ "toyota_rav4_hybrid_2017_pt.dbc starts h
CM_ "toyota_rav4_hybrid_2017_pt.dbc starts ";
CM_ "toyota_rav4_hybrid_2017_pt.dbc starts h
CM_ "toyota_rav4_hybrid_2017_pt.dbc starts h";
CM_ "toyota_rav4_hybrid_2017_pt.dbc starts he
CM_ "toyota_rav4_hybrid_2017_pt.dbc starts";
CM_ "toyota_rav4_hybrid_2017_pt.dbc starts
CM_ "toyota_rav4_hybrid_2017_pt.dbc starts ";
CM_ "toyota_rav4_hybrid_2017_pt.dbc starts h
CM_ "toyota_rav4_hybrid_2017_pt.dbc starts ";
CM_ "toyota_rav4_hybrid_2017_pt.dbc starts h
CM_ "toyota_rav4_hybrid_2017_pt.dbc starts h";
CM_ "toyota_rav4_hybrid_2017_pt.dbc starts he
CM_ "toyota_rav4_hybrid_2017_pt.dbc starts ";
CM_ "toyota_rav4_hybrid_2017_pt.dbc starts h
CM_ "toyota_rav4_hybrid_2017_pt.dbc starts h";
CM_ "toyota_rav4_hybrid_2017_pt.dbc starts he
CM_ "toyota_rav4_hybrid_2017_pt.dbc starts h";
CM_ "toyota_rav4_hybrid_2017_pt.dbc starts he
CM_ "toyota_rav4_hybrid_2017_pt.dbc starts he";
CM_ "toyota_rav4_hybrid_2017_pt.dbc starts her
CM_ "toyota_rav4_hybrid_2017_pt.dbc starts";
CM_ "toyota_rav4_hybrid_2017_pt.dbc starts
CM_ "toyota_rav4_hybrid_2017_pt.dbc starts ";
CM_ "toyota_rav4_hybrid_2017_pt.dbc starts h
CM_ "toyota_rav4_hybrid_2017_pt.dbc starts ";
CM_ "toyota_rav4_hybrid_2017_pt.dbc starts h
CM_ "toyota_rav4_hybrid_2017_pt.dbc starts h";
CM_ "toyota_rav4_hybrid_2017_pt.dbc starts he
CM_ "toyota_rav4_hybrid_2017_pt.dbc starts ";
CM_ "toyota_rav4_hybrid_2017_pt.dbc starts h
CM_ "toyota_rav4_hybrid_2017_pt.dbc starts h";
CM_ "toyota_rav4_hybrid_2017_pt.dbc starts he
CM_ "toyota_rav4_hybrid_2017_pt.dbc starts h";
CM_ "toyota_rav4_hybrid_2017_pt.dbc starts he
CM_ "toyota_rav4_hybrid_2017_pt.dbc starts he";
CM_ "toyota_rav4_hybrid_2017_pt.dbc starts her
CM_ "toyota_rav4_hybrid_2017_pt.dbc starts ";
CM_ "toyota_rav4_hybrid_2017_pt.dbc starts h
CM_ "toyota_rav4_hybrid_2017_pt.dbc starts h";
CM_ "toyota_rav4_hybrid_2017_pt.dbc starts he
CM_ "toyota_rav4_hybrid_2017_pt.dbc starts h";
CM_ "toyota_rav4_hybrid_2017_pt.dbc starts he
CM_ "toyota_rav4_hybrid_2017_pt.dbc starts he";
CM_ "toyota_rav4_hybrid_2017_pt.dbc starts her
CM_ "toyota_rav4_hybrid_2017_pt.dbc starts h";
CM_ "toyota_rav4_hybrid_2017_pt.dbc starts he
CM_ "toyota_rav4_hybrid_2017_pt.dbc starts he";
CM_ "toyota_rav4_hybrid_2017_pt.dbc starts her
CM_ "toyota_rav4_hybrid_2017_pt.dbc starts he";
CM_ "toyota_rav4_hybrid_2017_pt.dbc starts her
CM_ "toyota_rav4_hybrid_2017_pt.dbc starts her";
CM_ "toyota_rav4_hybrid_2017_pt.dbc starts here
CM_ "toyota_rav4_hybrid_2017_pt.dbc start";
CM_ "toyota_rav4_hybrid_2017_pt.dbc starts
CM_ "toyota_rav4_hybrid_2017_pt.dbc start";
CM_ "toyota_rav4_hybrid_2017_pt.dbc starts
CM_ "toyota_rav4_hybrid_2017_pt.dbc starts";
CM_ "toyota_rav4_hybrid_2017_pt.dbc starts
CM_ "toyota_rav4_hybrid_2017_pt.dbc starts ";
CM_ "toyota_rav4_hybrid_2017_pt.dbc starts h
CM_ "toyota_rav4_hybrid_2017_pt.dbc starts";
CM_ "toyota_rav4_hybrid_2017_pt.dbc starts
CM_ "toyota_rav4_hybrid_2017_pt.dbc starts ";
CM_ "toyota_rav4_hybrid_2017_pt.dbc starts h
CM_ "toyota_rav4_hybrid_2017_pt.dbc starts ";
CM_ "toyota_rav4_hybrid_2017_pt.dbc starts h
CM_ "toyota_rav4_hybrid_2017_pt.dbc starts h";
CM_ "toyota_rav4_hybrid_2017_pt.dbc starts he
CM_ "toyota_rav4_hybrid_2017_pt.dbc starts";
CM_ "toyota_rav4_hybrid_2017_pt.dbc starts
CM_ "toyota_rav4_hybrid_2017_pt.dbc starts ";
CM_ "toyota_rav4_hybrid_2017_pt.dbc starts h
CM_ "toyota_rav4_hybrid_2017_pt.dbc starts ";
CM_ "toyota_rav4_hybrid_2017_pt.dbc starts h
CM_ "toyota_rav4_hybrid_2017_pt.dbc starts h";
CM_ "toyota_rav4_hybrid_2017_pt.dbc starts he
CM_ "toyota_rav4_hybrid_2017_pt.dbc starts ";
CM_ "toyota_rav4_hybrid_2017_pt.dbc starts h
CM_ "toyota_rav4_hybrid_2017_pt.dbc starts h";
CM_ "toyota_rav4_hybrid_2017_pt.dbc starts he
CM_ "toyota_rav4_hybrid_2017_pt.dbc starts h";
CM_ "toyota_rav4_hybrid_2017_pt.dbc starts he
CM_ "toyota_rav4_hybrid_2017_pt.dbc starts he";
CM_ "toyota_rav4_hybrid_2017_pt.dbc starts her
CM_ "toyota_rav4_hybrid_2017_pt.dbc starts";
CM_ "toyota_rav4_hybrid_2017_pt.dbc starts
CM_ "toyota_rav4_hybrid_2017_pt.dbc starts ";
CM_ "toyota_rav4_hybrid_2017_pt.dbc starts h
CM_ "toyota_rav4_hybrid_2017_pt.dbc starts ";
CM_ "toyota_rav4_hybrid_2017_pt.dbc starts h
CM_ "toyota_rav4_hybrid_2017_pt.dbc starts h";
CM_ "toyota_rav4_hybrid_2017_pt.dbc starts he
CM_ "toyota_rav4_hybrid_2017_pt.dbc starts ";
CM_ "toyota_rav4_hybrid_2017_pt.dbc starts h
CM_ "toyota_rav4_hybrid_2017_pt.dbc starts h";
CM_ "toyota_rav4_hybrid_2017_pt.dbc starts he
CM_ "toyota_rav4_hybrid_2017_pt.dbc starts h";
CM_ "toyota_rav4_hybrid_2017_pt.dbc starts he
CM_ "toyota_rav4_hybrid_2017_pt.dbc starts he";
CM_ "toyota_rav4_hybrid_2017_pt.dbc starts her
CM_ "toyota_rav4_hybrid_2017_pt.dbc starts ";
CM_ "toyota_rav4_hybrid_2017_pt.dbc starts h
CM_ "toyota_rav4_hybrid_2017_pt.dbc starts h";
CM_ "toyota_rav4_hybrid_2017_pt.dbc starts he
CM_ "toyota_rav4_hybrid_2017_pt.dbc starts h";
CM_ "toyota_rav4_hybrid_2017_pt.dbc starts he
CM_ "toyota_rav4_hybrid_2017_pt.dbc starts he";
CM_ "toyota_rav4_hybrid_2017_pt.dbc starts her
CM_ "toyota_rav4_hybrid_2017_pt.dbc starts h";
CM_ "toyota_rav4_hybrid_2017_pt.dbc starts he
CM_ "toyota_rav4_hybrid_2017_pt.dbc starts he";
CM_ "toyota_rav4_hybrid_2017_pt.dbc starts her
CM_ "toyota_rav4_hybrid_2017_pt.dbc starts he";
CM_ "toyota_rav4_hybrid_2017_pt.dbc starts her
CM_ "toyota_rav4_hybrid_2017_pt.dbc starts her";
CM_ "toyota_rav4_hybrid_2017_pt.dbc starts here
CM_ "toyota_rav4_hybrid_2017_pt.dbc starts";
CM_ "toyota_rav4_hybrid_2017_pt.dbc starts
CM_ "toyota_rav4_hybrid_2017_pt.dbc starts ";
CM_ "toyota_rav4_hybrid_2017_pt.dbc starts h
CM_ "toyota_rav4_hybrid_2017_pt.dbc starts ";
CM_ "toyota_rav4_hybrid_2017_pt.dbc starts h
CM_ "toyota_rav4_hybrid_2017_pt.dbc starts h";
CM_ "toyota_rav4_hybrid_2017_pt.dbc starts he
CM_ "toyota_rav4_hybrid_2017_pt.dbc starts ";
CM_ "toyota_rav4_hybrid_2017_pt.dbc starts h
CM_ "toyota_rav4_hybrid_2017_pt.dbc starts h";
CM_ "toyota_rav4_hybrid_2017_pt.dbc starts he
CM_ "toyota_rav4_hybrid_2017_pt.dbc starts h";
CM_ "toyota_rav4_hybrid_2017_pt.dbc starts he
CM_ "toyota_rav4_hybrid_2017_pt.dbc starts he";
CM_ "toyota_rav4_hybrid_2017_pt.dbc starts her
CM_ "toyota_rav4_hybrid_2017_pt.dbc starts ";
CM_ "toyota_rav4_hybrid_2017_pt.dbc starts h
CM_ "toyota_rav4_hybrid_2017_pt.dbc starts h";
CM_ "toyota_rav4_hybrid_2017_pt.dbc starts he
CM_ "toyota_rav4_hybrid_2017_pt.dbc starts h";
CM_ "toyota_rav4_hybrid_2017_pt.dbc starts he
CM_ "toyota_rav4_hybrid_2017_pt.dbc starts he";
CM_ "toyota_rav4_hybrid_2017_pt.dbc starts her
CM_ "toyota_rav4_hybrid_2017_pt.dbc starts h";
CM_ "toyota_rav4_hybrid_2017_pt.dbc starts he
CM_ "toyota_rav4_hybrid_2017_pt.dbc starts he";
CM_ "toyota_rav4_hybrid_2017_pt.dbc starts her
CM_ "toyota_rav4_hybrid_2017_pt.dbc starts he";
CM_ "toyota_rav4_hybrid_2017_pt.dbc starts her
CM_ "toyota_rav4_hybrid_2017_pt.dbc starts her";
CM_ "toyota_rav4_hybrid_2017_pt.dbc starts here
CM_ "toyota_rav4_hybrid_2017_pt.dbc starts ";
CM_ "toyota_rav4_hybrid_2017_pt.dbc starts h
CM_ "toyota_rav4_hybrid_2017_pt.dbc starts h";
CM_ "toyota_rav4_hybrid_2017_pt.dbc starts he
CM_ "toyota_rav4_hybrid_2017_pt.dbc starts h";
CM_ "toyota_rav4_hybrid_2017_pt.dbc starts he
CM_ "toyota_rav4_hybrid_2017_pt.dbc starts he";
CM_ "toyota_rav4_hybrid_2017_pt.dbc starts her
CM_ "toyota_rav4_hybrid_2017_pt.dbc starts h";
CM_ "toyota_rav4_hybrid_2017_pt.dbc starts he
CM_ "toyota_rav4_hybrid_2017_pt.dbc starts he";
CM_ "toyota_rav4_hybrid_2017_pt.dbc starts her
CM_ "toyota_rav4_hybrid_2017_pt.dbc starts he";
CM_ "toyota_rav4_hybrid_2017_pt.dbc starts her
CM_ "toyota_rav4_hybrid_2017_pt.dbc starts her";
CM_ "toyota_rav4_hybrid_2017_pt.dbc starts here
CM_ "toyota_rav4_hybrid_2017_pt.dbc starts h";
CM_ "toyota_rav4_hybrid_2017_pt.dbc starts he
CM_ "toyota_rav4_hybrid_2017_pt.dbc starts he";
CM_ "toyota_rav4_hybrid_2017_pt.dbc starts her
CM_ "toyota_rav4_hybrid_2017_pt.dbc starts he";
CM_ "toyota_rav4_hybrid_2017_pt.dbc starts her
CM_ "toyota_rav4_hybrid_2017_pt.dbc starts her";
CM_ "toyota_rav4_hybrid_2017_pt.dbc starts here
CM_ "toyota_rav4_hybrid_2017_pt.dbc starts he";
CM_ "toyota_rav4_hybrid_2017_pt.dbc starts her
CM_ "toyota_rav4_hybrid_2017_pt.dbc starts her";
CM_ "toyota_rav4_hybrid_2017_pt.dbc starts here
CM_ "toyota_rav4_hybrid_2017_pt.dbc starts her";
CM_ "toyota_rav4_hybrid_2017_pt.dbc starts here
CM_ "toyota_rav4_hybrid_2017_pt.dbc starts here";
CM_ "toyota_rav4_hybrid_2017_pt.dbc starts here"
BO_ 550 BRAKE_MODULE: 8 XXX
SG_ BRAKE_PRESSURE : 0|9@0+ (1,0) [0|511] ";
